VERSION ""

NS_ :

BS_:

BU_: IVI ZCU_F

BO_ 3221225472 VECTOR__INDEPENDENT_SIG_MSG: 0 Vector__XXX
 SG_ IVI_SrcNodeID : 0|8@1+ (1,0) [0|255] "" Vector__XXX
 SG_ IVI_CBV_ReptMsgBit_0 : 0|1@1+ (1,0) [0|1] "" Vector__XXX
 SG_ IVI_CBV_ResdBit_1 : 0|1@1+ (1,0) [0|1] "" Vector__XXX
 SG_ IVI_CBV_ResdBit_2 : 0|1@1+ (1,0) [0|1] "" Vector__XXX
 SG_ IVI_CBV_NMCoordBit_3 : 0|1@1+ (1,0) [0|1] "" Vector__XXX
 SG_ IVI_CBV_ActWakeBit_4 : 0|1@1+ (1,0) [0|1] "" Vector__XXX
 SG_ IVI_CBV_ResdBit_5 : 0|1@1+ (1,0) [0|1] "" Vector__XXX
 SG_ IVI_CBV_PNIBit_6 : 0|1@1+ (1,0) [0|1] "" Vector__XXX
 SG_ IVI_CBV_ResdBit_7 : 0|1@1+ (1,0) [0|1] "" Vector__XXX
 SG_ IVI_UDB_0 : 0|8@1+ (1,0) [0|255] "" Vector__XXX
 SG_ IVI_UDB1_BStoRM_StBit_0 : 0|1@1+ (1,0) [0|1] "" Vector__XXX
 SG_ IVI_UDB1_PBStoRM_StBit_1 : 0|1@1+ (1,0) [0|1] "" Vector__XXX
 SG_ IVI_UDB1_RMtoNO_StBit_2 : 0|1@1+ (1,0) [0|1] "" Vector__XXX
 SG_ IVI_UDB1_RStoNO_StBit_3 : 0|1@1+ (1,0) [0|1] "" Vector__XXX
 SG_ IVI_UDB1_RStoRM_StBit_4 : 0|1@1+ (1,0) [0|1] "" Vector__XXX
 SG_ IVI_UDB1_NOtoRM_StBit_5 : 0|1@1+ (1,0) [0|1] "" Vector__XXX
 SG_ IVI_UDB1_NO_StBit_6 : 0|1@1+ (1,0) [0|1] "" Vector__XXX
 SG_ IVI_UDB1_RM_StBit_7 : 0|1@1+ (1,0) [0|1] "" Vector__XXX
 SG_ IVI_UDB2_IGN_WUPBit_0 : 0|1@1+ (1,0) [0|1] "" Vector__XXX
 SG_ IVI_UDB2_RESET_WUPBit_1 : 0|1@1+ (1,0) [0|1] "" Vector__XXX
 SG_ IVI_UDB2_NM_WUPBit_2 : 0|1@1+ (1,0) [0|1] "" Vector__XXX
 SG_ IVI_UDB2_ECUSPEC_WUPBit_3 : 0|1@1+ (1,0) [0|1] "" Vector__XXX
 SG_ IVI_UDB2_NM_AWAKEBit_4 : 0|1@1+ (1,0) [0|1] "" Vector__XXX
 SG_ IVI_UDB2_IGN_AWAKEBit_5 : 0|1@1+ (1,0) [0|1] "" Vector__XXX
 SG_ IVI_UDB2_DIAG_AWAKEBit_6 : 0|1@1+ (1,0) [0|1] "" Vector__XXX
 SG_ IVI_UDB2_ECUSPEC_AWAKEBit_7 : 0|1@1+ (1,0) [0|1] "" Vector__XXX
 SG_ IVI_UDB3_Bit_0 : 0|1@1+ (1,0) [0|1] "" Vector__XXX
 SG_ IVI_UDB3_Bit_1 : 0|1@1+ (1,0) [0|1] "" Vector__XXX
 SG_ IVI_UDB3_Bit_2 : 0|1@1+ (1,0) [0|1] "" Vector__XXX
 SG_ IVI_UDB3_Bit_3 : 0|1@1+ (1,0) [0|1] "" Vector__XXX
 SG_ IVI_UDB3_Bit_4 : 0|1@1+ (1,0) [0|1] "" Vector__XXX
 SG_ IVI_UDB3_Bit_5 : 0|1@1+ (1,0) [0|1] "" Vector__XXX
 SG_ IVI_UDB3_Bit_6 : 0|1@1+ (1,0) [0|1] "" Vector__XXX
 SG_ IVI_UDB3_Bit_7 : 0|1@1+ (1,0) [0|1] "" Vector__XXX
 SG_ IVI_UDB4_Bit_0 : 0|1@1+ (1,0) [0|1] "" Vector__XXX
 SG_ IVI_UDB4_Bit_1 : 0|1@1+ (1,0) [0|1] "" Vector__XXX
 SG_ IVI_UDB4_Bit_2 : 0|1@1+ (1,0) [0|1] "" Vector__XXX
 SG_ IVI_UDB4_Bit_3 : 0|1@1+ (1,0) [0|1] "" Vector__XXX
 SG_ IVI_UDB4_Bit_4 : 0|1@1+ (1,0) [0|1] "" Vector__XXX
 SG_ IVI_UDB4_Bit_5 : 0|1@1+ (1,0) [0|1] "" Vector__XXX
 SG_ IVI_UDB4_Bit_6 : 0|1@1+ (1,0) [0|1] "" Vector__XXX
 SG_ IVI_UDB4_Bit_7 : 0|1@1+ (1,0) [0|1] "" Vector__XXX
 SG_ IVI_UDB5_Bit_0 : 0|1@1+ (1,0) [0|1] "" Vector__XXX
 SG_ IVI_UDB5_Bit_1 : 0|1@1+ (1,0) [0|1] "" Vector__XXX
 SG_ IVI_UDB5_Bit_2 : 0|1@1+ (1,0) [0|1] "" Vector__XXX
 SG_ IVI_UDB5_Bit_3 : 0|1@1+ (1,0) [0|1] "" Vector__XXX
 SG_ IVI_UDB5_Bit_4 : 0|1@1+ (1,0) [0|1] "" Vector__XXX
 SG_ IVI_UDB5_Bit_5 : 0|1@1+ (1,0) [0|1] "" Vector__XXX
 SG_ IVI_UDB5_Bit_6 : 0|1@1+ (1,0) [0|1] "" Vector__XXX
 SG_ IVI_UDB5_Bit_7 : 0|1@1+ (1,0) [0|1] "" Vector__XXX
 SG_ ZCUF_SrcNodeID : 0|8@1+ (1,0) [0|255] "" Vector__XXX
 SG_ ZCUF_CBV_ReptMsgBit_0 : 0|1@1+ (1,0) [0|1] "" Vector__XXX
 SG_ ZCUF_CBV_ResdBit_1 : 0|1@1+ (1,0) [0|1] "" Vector__XXX
 SG_ ZCUF_CBV_ResdBit_2 : 0|1@1+ (1,0) [0|1] "" Vector__XXX
 SG_ ZCUF_CBV_NMCoordBit_3 : 0|1@1+ (1,0) [0|1] "" Vector__XXX
 SG_ ZCUF_CBV_ActWakeBit_4 : 0|1@1+ (1,0) [0|1] "" Vector__XXX
 SG_ ZCUF_CBV_ResdBit_5 : 0|1@1+ (1,0) [0|1] "" Vector__XXX
 SG_ ZCUF_CBV_PNIBit_6 : 0|1@1+ (1,0) [0|1] "" Vector__XXX
 SG_ ZCUF_CBV_ResdBit_7 : 0|1@1+ (1,0) [0|1] "" Vector__XXX
 SG_ ZCUF_UDB_0 : 0|8@1+ (1,0) [0|255] "" Vector__XXX
 SG_ ZCUF_UDB1_BStoRM_StBit_0 : 0|1@1+ (1,0) [0|1] "" Vector__XXX
 SG_ ZCUF_UDB1_PBStoRM_StBit1 : 0|1@1+ (1,0) [0|1] "" Vector__XXX
 SG_ ZCUF_UDB1_RMtoNO_StBit_2 : 0|1@1+ (1,0) [0|1] "" Vector__XXX
 SG_ ZCUF_UDB1_RStoNO_StBit_3 : 0|1@1+ (1,0) [0|1] "" Vector__XXX
 SG_ ZCUF_UDB1_RStoRM_StBit_4 : 0|1@1+ (1,0) [0|1] "" Vector__XXX
 SG_ ZCUF_UDB1_NOtoRM_StBit_5 : 0|1@1+ (1,0) [0|1] "" Vector__XXX
 SG_ ZCUF_UDB1_NO_StBit_6 : 0|1@1+ (1,0) [0|1] "" Vector__XXX
 SG_ ZCUF_UDB1_RM_StBit_7 : 0|1@1+ (1,0) [0|1] "" Vector__XXX
 SG_ ZCUF_UDB2_IGN_WUPBit_0 : 0|1@1+ (1,0) [0|1] "" Vector__XXX
 SG_ ZCUF_UDB2_RESET_WUPBit_1 : 0|1@1+ (1,0) [0|1] "" Vector__XXX
 SG_ ZCUF_UDB2_NM_WUPBit_2 : 0|1@1+ (1,0) [0|1] "" Vector__XXX
 SG_ ZCUF_UDB2_ECUSPEC_WUPBit_3 : 0|1@1+ (1,0) [0|1] "" Vector__XXX
 SG_ ZCUF_UDB2_NM_AWAKEBit_4 : 0|1@1+ (1,0) [0|1] "" Vector__XXX
 SG_ ZCUF_UDB2_IGN_AWAKEBit_5 : 0|1@1+ (1,0) [0|1] "" Vector__XXX
 SG_ ZCUF_UDB2_DIAG_AWAKEBit_6 : 0|1@1+ (1,0) [0|1] "" Vector__XXX
 SG_ ZCUF_UDB2_ECUSPEC_AWKEBit7 : 0|1@1+ (1,0) [0|1] "" Vector__XXX
 SG_ ZCUF_UDB3_Bit_0 : 0|1@1+ (1,0) [0|1] "" Vector__XXX
 SG_ ZCUF_UDB3_Bit_1 : 0|1@1+ (1,0) [0|1] "" Vector__XXX
 SG_ ZCUF_UDB3_Bit_2 : 0|1@1+ (1,0) [0|1] "" Vector__XXX
 SG_ ZCUF_UDB3_Bit_3 : 0|1@1+ (1,0) [0|1] "" Vector__XXX
 SG_ ZCUF_UDB3_Bit_4 : 0|1@1+ (1,0) [0|1] "" Vector__XXX
 SG_ ZCUF_UDB3_Bit_5 : 0|1@1+ (1,0) [0|1] "" Vector__XXX
 SG_ ZCUF_UDB3_Bit_6 : 0|1@1+ (1,0) [0|1] "" Vector__XXX
 SG_ ZCUF_UDB3_Bit_7 : 0|1@1+ (1,0) [0|1] "" Vector__XXX
 SG_ ZCUF_UDB4_Bit_0 : 0|1@1+ (1,0) [0|1] "" Vector__XXX
 SG_ ZCUF_UDB4_Bit_1 : 0|1@1+ (1,0) [0|1] "" Vector__XXX
 SG_ ZCUF_UDB4_Bit_2 : 0|1@1+ (1,0) [0|1] "" Vector__XXX
 SG_ ZCUF_UDB4_Bit_3 : 0|1@1+ (1,0) [0|1] "" Vector__XXX
 SG_ ZCUF_UDB4_Bit_4 : 0|1@1+ (1,0) [0|1] "" Vector__XXX
 SG_ ZCUF_UDB4_Bit_5 : 0|1@1+ (1,0) [0|1] "" Vector__XXX
 SG_ ZCUF_UDB4_Bit_6 : 0|1@1+ (1,0) [0|1] "" Vector__XXX
 SG_ ZCUF_UDB4_Bit_7 : 0|1@1+ (1,0) [0|1] "" Vector__XXX
 SG_ ZCUF_UDB5_Bit_0 : 0|1@1+ (1,0) [0|1] "" Vector__XXX
 SG_ ZCUF_UDB5_Bit_1 : 0|1@1+ (1,0) [0|1] "" Vector__XXX
 SG_ ZCUF_UDB5_Bit_2 : 0|1@1+ (1,0) [0|1] "" Vector__XXX
 SG_ ZCUF_UDB5_Bit_3 : 0|1@1+ (1,0) [0|1] "" Vector__XXX
 SG_ ZCUF_UDB5_Bit_4 : 0|1@1+ (1,0) [0|1] "" Vector__XXX
 SG_ ZCUF_UDB5_Bit_5 : 0|1@1+ (1,0) [0|1] "" Vector__XXX
 SG_ ZCUF_UDB5_Bit_6 : 0|1@1+ (1,0) [0|1] "" Vector__XXX
 SG_ ZCUF_UDB5_Bit_7 : 0|1@1+ (1,0) [0|1] "" Vector__XXX

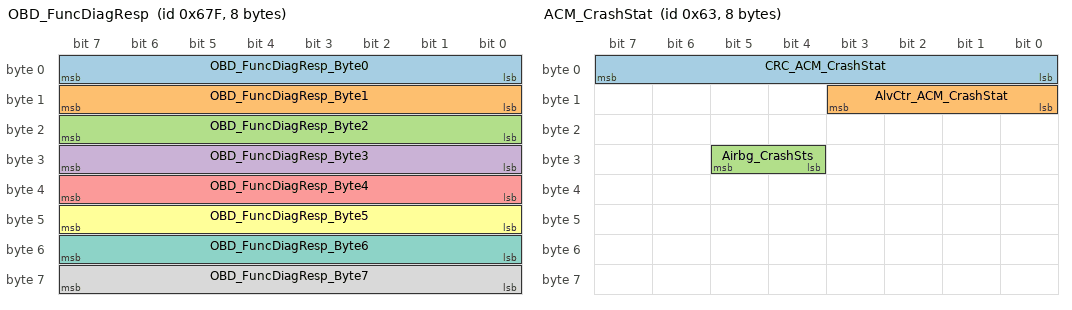
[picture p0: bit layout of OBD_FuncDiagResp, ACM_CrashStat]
BO_ 1663 OBD_FuncDiagResp: 8 IVI
 SG_ OBD_FuncDiagResp_Byte0 : 0|8@1+ (1,0) [0|255] ""  ZCU_F
 SG_ OBD_FuncDiagResp_Byte1 : 8|8@1+ (1,0) [0|255] ""  ZCU_F
 SG_ OBD_FuncDiagResp_Byte2 : 16|8@1+ (1,0) [0|255] ""  ZCU_F
 SG_ OBD_FuncDiagResp_Byte3 : 24|8@1+ (1,0) [0|255] ""  ZCU_F
 SG_ OBD_FuncDiagResp_Byte4 : 32|8@1+ (1,0) [0|255] ""  ZCU_F
 SG_ OBD_FuncDiagResp_Byte5 : 40|8@1+ (1,0) [0|255] ""  ZCU_F
 SG_ OBD_FuncDiagResp_Byte6 : 48|8@1+ (1,0) [0|255] ""  ZCU_F
 SG_ OBD_FuncDiagResp_Byte7 : 56|8@1+ (1,0) [0|255] ""  ZCU_F

BO_ 99 ACM_CrashStat: 8 ZCU_F
 SG_ CRC_ACM_CrashStat : 0|8@1+ (1,0) [0|255] ""  IVI
 SG_ AlvCtr_ACM_CrashStat : 8|4@1+ (1,0) [0|14] ""  IVI
 SG_ Airbg_CrashSts : 28|2@1+ (1,0) [0|3] ""  IVI

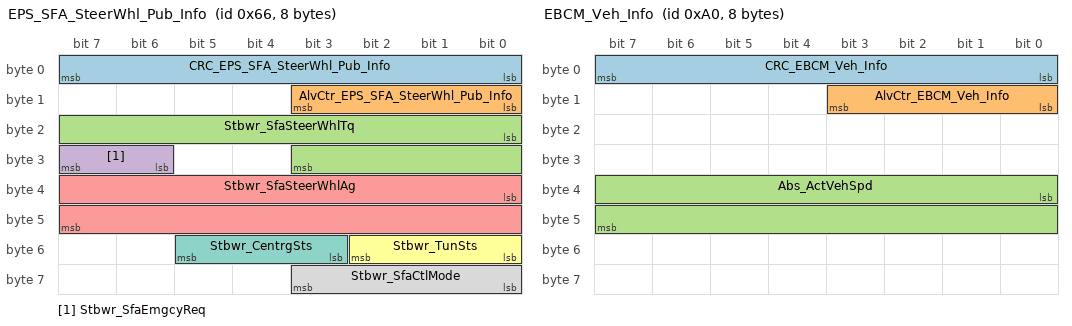
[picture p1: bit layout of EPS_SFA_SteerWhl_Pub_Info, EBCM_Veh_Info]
BO_ 102 EPS_SFA_SteerWhl_Pub_Info: 8 ZCU_F
 SG_ CRC_EPS_SFA_SteerWhl_Pub_Info : 0|8@1+ (1,0) [0|255] ""  IVI
 SG_ AlvCtr_EPS_SFA_SteerWhl_Pub_Info : 8|4@1+ (1,0) [0|14] ""  IVI
 SG_ Stbwr_SfaSteerWhlTq : 16|12@1+ (0.02,-40) [-40|40] "Nm"  IVI
 SG_ Stbwr_SfaEmgcyReq : 30|2@1+ (1,0) [0|3] ""  IVI
 SG_ Stbwr_SfaSteerWhlAg : 32|16@1+ (0.02,-655) [-655|655] "degree"  IVI
 SG_ Stbwr_TunSts : 48|3@1+ (1,0) [0|7] ""  IVI
 SG_ Stbwr_CentrgSts : 51|3@1+ (1,0) [0|7] ""  IVI
 SG_ Stbwr_SfaCtlMode : 56|4@1+ (1,0) [0|15] ""  IVI

BO_ 103 VCU_ETractSys_Info: 32 ZCU_F
 SG_ CRC_VCU_ETractSys_Info : 0|16@1+ (1,0) [0|65535] ""  IVI
 SG_ AlvCtr_VCU_ETractSys_Info : 16|8@1+ (1,0) [0|255] ""  IVI
 SG_ Dtqmt_TgtTqEdsRe : 104|12@1+ (0.5,-1023) [-1023|1024.5] "Nm"  IVI
 SG_ Dtqmt_TgtTqEdsFrnt : 120|12@1+ (0.5,-1023) [-1023|1024.5] "Nm"  IVI

BO_ 118 RWSM_Info: 32 ZCU_F
 SG_ CRC_RWSM_Info : 0|16@1+ (1,0) [0|65535] ""  IVI
 SG_ AlvCtr_RWSM_Info : 16|8@1+ (1,0) [0|255] ""  IVI
 SG_ ReWhlSteer_MeasdStkVal : 40|16@1+ (0.01,-327.67) [0|327.65] "mm"  IVI
 SG_ ReWhlSteer_Sts : 56|2@1+ (1,0) [0|3] ""  IVI

BO_ 119 BMS_Sts: 64 ZCU_F
 SG_ CRC_BMS_Sts : 0|16@1+ (1,0) [0|65535] ""  IVI
 SG_ AlvCtr_BMS_Sts : 16|8@1+ (1,0) [0|255] ""  IVI
 SG_ Bms_BatPreCdnSts : 70|2@1+ (1,0) [0|3] ""  IVI

BO_ 128 EPS_RWA_Pinion_Pub_Info: 32 ZCU_F
 SG_ CRC_EPS_RWA_Pinion_Pub_Info : 0|16@1+ (1,0) [0|65535] ""  IVI
 SG_ AlvCtr_EPS_RWA_Pinion_Pub_Info : 16|8@1+ (1,0) [0|255] ""  IVI
 SG_ Stbwr_RwaPinionAg : 24|16@1+ (0.02,-655) [-655|655] "degree"  IVI
 SG_ Stbwr_RwaPinionAgSpd : 40|16@1+ (0.05,-1638) [-1638|1638] "deg/s"  IVI
 SG_ Stbwr_RwaRackPosn : 56|20@1+ (0.001,-524) [-524|524] "mm"  IVI
 SG_ Stbwr_RwaRackSpd : 76|20@1+ (0.001,-524) [-524|524.575] "mm/s"  IVI

BO_ 160 EBCM_Veh_Info: 8 ZCU_F
 SG_ CRC_EBCM_Veh_Info : 0|8@1+ (1,0) [0|255] ""  IVI
 SG_ AlvCtr_EBCM_Veh_Info : 8|4@1+ (1,0) [0|14] ""  IVI
 SG_ Abs_ActVehSpd : 32|16@1+ (0.015625,0) [0|350] "kmph"  IVI

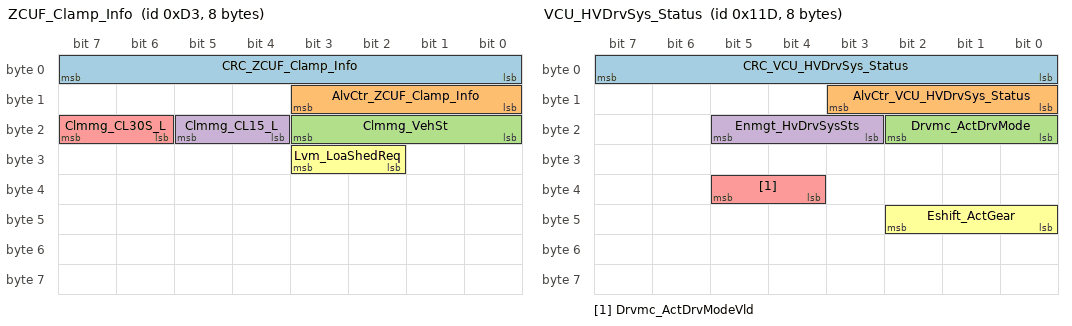
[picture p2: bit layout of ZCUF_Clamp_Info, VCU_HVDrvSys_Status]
BO_ 211 ZCUF_Clamp_Info: 8 ZCU_F
 SG_ CRC_ZCUF_Clamp_Info : 0|8@1+ (1,0) [0|255] ""  IVI
 SG_ AlvCtr_ZCUF_Clamp_Info : 8|4@1+ (1,0) [0|14] ""  IVI
 SG_ Clmmg_VehSt : 16|4@1+ (1,0) [0|15] ""  IVI
 SG_ Clmmg_CL15_L : 20|2@1+ (1,0) [0|3] ""  IVI
 SG_ Clmmg_CL30S_L : 22|2@1+ (1,0) [0|3] ""  IVI
 SG_ Lvm_LoaShedReq : 26|2@1+ (1,0) [0|3] ""  IVI

BO_ 223 ASU_SnsrInfo: 32 ZCU_F
 SG_ CRC_ASU_SnsrInfo : 0|16@1+ (1,0) [0|65535] ""  IVI
 SG_ AlvCtr_ASU_SnsrInfo : 16|8@1+ (1,0) [0|255] ""  IVI
 SG_ AirSuspUnit_HeiFL : 24|12@1+ (1,0) [0|4095] "mm"  IVI
 SG_ AirSuspUnit_HeiFR : 36|12@1+ (1,0) [0|4095] "mm"  IVI
 SG_ AirSuspUnit_HeiRR : 48|12@1+ (1,0) [0|4095] "mm"  IVI
 SG_ AirSuspUnit_HeiRL : 60|12@1+ (1,0) [0|4095] "mm"  IVI
 SG_ AirSuspUnit_HeiSts : 72|3@1+ (1,0) [0|7] ""  IVI
 SG_ AirSuspUnit_CdcModeSts : 75|3@1+ (1,0) [0|7] ""  IVI
 SG_ AirSuspUnit_IngrsModAck : 78|2@1+ (1,0) [0|3] ""  IVI
 SG_ AirSuspUnit_SprgModeSts : 80|3@1+ (1,0) [0|7] ""  IVI
 SG_ AirSuspUnit_CmprSts : 83|3@1+ (1,0) [0|7] ""  IVI
 SG_ AirSuspUnit_SrvModeSts : 86|2@1+ (1,0) [0|3] ""  IVI
 SG_ AirSuspUnit_AirTankP : 88|8@1+ (10,0) [0|2530] "bar"  IVI
 SG_ AirSuspUnit_Sts : 96|3@1+ (1,0) [0|7] ""  IVI

BO_ 273 VCU_Batt_Info: 32 ZCU_F
 SG_ CRC_VCU_Batt_Info : 0|16@1+ (1,0) [0|65535] ""  IVI
 SG_ AlvCtr_VCU_Batt_Info : 16|8@1+ (1,0) [0|255] ""  IVI
 SG_ Bms_PackI : 24|16@1+ (0.1,-1500) [-1500|1500] "A"  IVI
 SG_ Bms_PackU : 40|16@1+ (0.1,0) [0|600] "V"  IVI
 SG_ Acchg_RmngChgTi : 56|12@1+ (1,0) [0|1500] "minute"  IVI
 SG_ Fschg_RmngChgTi : 68|12@1+ (1,0) [0|1500] "minute"  IVI

BO_ 279 VCU_Charging_Info: 32 ZCU_F
 SG_ CRC_VCU_Charging_Info : 0|16@1+ (1,0) [0|65535] ""  IVI
 SG_ AlvCtr_VCU_Charging_Info : 16|8@1+ (1,0) [0|255] ""  IVI
 SG_ Fschg_DcChgGunIn : 24|2@1+ (1,0) [0|3] ""  IVI
 SG_ Acchg_AcChgGunIn : 26|2@1+ (1,0) [0|3] ""  IVI

BO_ 285 VCU_HVDrvSys_Status: 8 ZCU_F
 SG_ CRC_VCU_HVDrvSys_Status : 0|8@1+ (1,0) [0|255] ""  IVI
 SG_ AlvCtr_VCU_HVDrvSys_Status : 8|4@1+ (1,0) [0|14] ""  IVI
 SG_ Drvmc_ActDrvMode : 16|3@1+ (1,0) [0|7] ""  IVI
 SG_ Enmgt_HvDrvSysSts : 19|3@1+ (1,0) [0|7] ""  IVI
 SG_ Drvmc_ActDrvModeVld : 36|2@1+ (1,0) [0|3] ""  IVI
 SG_ Eshift_ActGear : 40|3@1+ (1,0) [0|7] ""  IVI

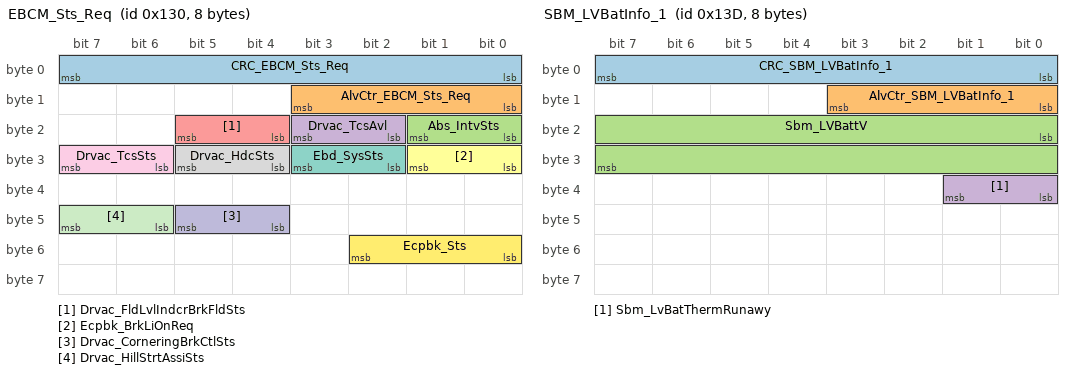
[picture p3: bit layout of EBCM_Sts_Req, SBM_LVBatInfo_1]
BO_ 304 EBCM_Sts_Req: 8 ZCU_F
 SG_ CRC_EBCM_Sts_Req : 0|8@1+ (1,0) [0|255] ""  IVI
 SG_ AlvCtr_EBCM_Sts_Req : 8|4@1+ (1,0) [0|14] ""  IVI
 SG_ Abs_IntvSts : 16|2@1+ (1,0) [0|3] ""  IVI
 SG_ Drvac_TcsAvl : 18|2@1+ (1,0) [0|3] ""  IVI
 SG_ Drvac_FldLvlIndcrBrkFldSts : 20|2@1+ (1,0) [0|3] ""  IVI
 SG_ Ecpbk_BrkLiOnReq : 24|2@1+ (1,0) [0|3] ""  IVI
 SG_ Ebd_SysSts : 26|2@1+ (1,0) [0|3] ""  IVI
 SG_ Drvac_HdcSts : 28|2@1+ (1,0) [0|3] ""  IVI
 SG_ Drvac_TcsSts : 30|2@1+ (1,0) [0|3] ""  IVI
 SG_ Drvac_CorneringBrkCtlSts : 44|2@1+ (1,0) [0|3] ""  IVI
 SG_ Drvac_HillStrtAssiSts : 46|2@1+ (1,0) [0|3] ""  IVI
 SG_ Ecpbk_Sts : 48|3@1+ (1,0) [0|7] ""  IVI

BO_ 313 ZCUR_LampCmd: 32 ZCU_F
 SG_ CRC_ZCUR_LampCmd : 0|16@1+ (1,0) [0|65535] ""  IVI
 SG_ AlvCtr_ZCUR_LampCmd : 16|8@1+ (1,0) [0|255] ""  IVI

BO_ 317 SBM_LVBatInfo_1: 8 ZCU_F
 SG_ CRC_SBM_LVBatInfo_1 : 0|8@1+ (1,0) [0|255] ""  IVI
 SG_ AlvCtr_SBM_LVBatInfo_1 : 8|4@1+ (1,0) [0|14] ""  IVI
 SG_ Sbm_LVBattV : 16|16@1+ (0.001,0) [0|65.535] "V"  IVI
 SG_ Sbm_LvBatThermRunawy : 32|2@1+ (1,0) [0|3] ""  IVI

BO_ 318 SBM_LVBatInfo_2: 32 ZCU_F
 SG_ CRC_SBM_LVBatInfo_2 : 0|16@1+ (1,0) [0|65535] ""  IVI
 SG_ AlvCtr_SBM_LVBatInfo_2 : 16|8@1+ (1,0) [0|255] ""  IVI
 SG_ Sbm_LVBatActSoh : 32|7@1+ (1,0) [0|100] "%"  IVI
 SG_ Sbm_CriticalSoCAlert : 40|4@1+ (1,0) [0|15] ""  IVI
 SG_ Sbm_LvBattT : 96|8@1+ (1,-40) [-40|215] "°C"  IVI

BO_ 327 VCU_Consumption_Info: 12 ZCU_F
 SG_ Engmt_LvAuxAvgEngCns : 0|16@1+ (0.1,0) [0|1440] "Kwh/100Km"  IVI
 SG_ Engmt_InttsEngCnsRate : 16|10@1+ (1,0) [0|1023] "W"  IVI
 SG_ Engmt_TotAvgEngCns : 32|16@1+ (0.1,0) [0|1440] "Kwh/100Km"  IVI
 SG_ Engmt_EdsAvgEngCns : 48|16@1+ (0.1,0) [0|1440] "Kwh/100Km"  IVI
 SG_ Engmt_ThermAvgEngCns : 64|16@1+ (0.1,0) [0|1440] "Kwh/100Km"  IVI

BO_ 349 VCU_To_Veh_Info: 32 ZCU_F
 SG_ CRC_VCU_To_Veh_Info : 0|16@1+ (1,0) [0|65535] ""  IVI
 SG_ AlvCtr_VCU_To_Veh_Info : 16|8@1+ (1,0) [0|255] ""  IVI
 SG_ Acchg_HVBatSoc : 24|10@1+ (0.1,0) [0|100] "%"  IVI
 SG_ Acchg_AcChgSts : 34|3@1+ (1,0) [0|7] ""  IVI
 SG_ Awd_ActWhlDrvMode : 37|3@1+ (1,0) [0|7] ""  IVI
 SG_ Engmt_ChrgrDlvPwr : 40|16@1+ (0.1,0) [0|1440] "kW"  IVI
 SG_ Engmt_VehRmngDrvRng : 56|10@1+ (1,0) [0|1023] "km"  IVI
 SG_ Cregb_CoastRgnLvlIndcr : 69|3@1+ (1,0) [0|7] ""  IVI
 SG_ Fschg_VehChrgnSts : 72|3@1+ (1,0) [0|7] ""  IVI
 SG_ Eshift_ChngGearFromPark : 78|2@1+ (1,0) [0|3] ""  IVI
 SG_ Engmt_VehMilg : 80|10@1+ (1,0) [0|1023] "km/kWh"  IVI
 SG_ Fschg_HVBatSoc : 90|10@1+ (0.1,0) [0|100] "%"  IVI
 SG_ Fschg_ChgGunLockSts : 100|2@1+ (1,0) [0|3] ""  IVI
 SG_ Awd_ActWhlDrvModeVld : 120|2@1+ (1,0) [0|3] ""  IVI

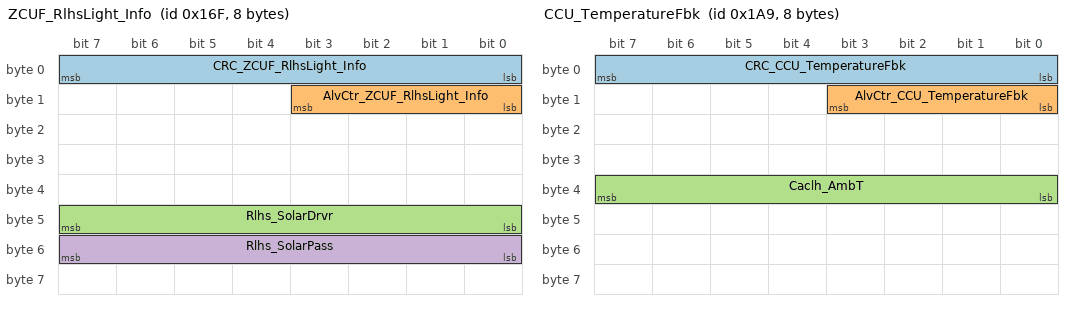
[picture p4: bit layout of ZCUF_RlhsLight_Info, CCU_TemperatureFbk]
BO_ 367 ZCUF_RlhsLight_Info: 8 ZCU_F
 SG_ CRC_ZCUF_RlhsLight_Info : 0|8@1+ (1,0) [0|255] ""  IVI
 SG_ AlvCtr_ZCUF_RlhsLight_Info : 8|4@1+ (1,0) [0|14] ""  IVI
 SG_ Rlhs_SolarDrvr : 40|8@1+ (4,0) [0|1000] "W/m2"  IVI
 SG_ Rlhs_SolarPass : 48|8@1+ (4,0) [0|1000] "W/m2"  IVI

BO_ 371 HDLML_FrontLamp_Sts: 32 ZCU_F
 SG_ CRC_HDLML_FrontLamp_Sts : 0|16@1+ (1,0) [0|65535] ""  IVI
 SG_ AlvCtr_HDLML_FrontLamp_Sts : 16|8@1+ (1,0) [0|255] ""  IVI
 SG_ Hdlamp_LeLoBeamLampSts : 24|2@1+ (1,0) [0|3] ""  IVI
 SG_ Hdlamp_LeHiBeamLampSts : 26|3@1+ (1,0) [0|7] ""  IVI

BO_ 377 HDLMR_FrontLamp_Sts: 32 ZCU_F
 SG_ CRC_HDLMR_FrontLamp_Sts : 0|16@1+ (1,0) [0|65535] ""  IVI
 SG_ AlvCtr_HDLMR_FrontLamp_Sts : 16|8@1+ (1,0) [0|255] ""  IVI
 SG_ Hdlamp_RiLoBeamLampSts : 24|2@1+ (1,0) [0|3] ""  IVI
 SG_ Hdlamp_RiHiBeamLampSts : 26|3@1+ (1,0) [0|7] ""  IVI

BO_ 383 SLMFL_FrontLamp_Sts: 32 ZCU_F
 SG_ CRC_SLMFL_FrontLamp_Sts : 0|16@1+ (1,0) [0|65535] ""  IVI
 SG_ AlvCtr_SLMFL_FrontLamp_Sts : 16|8@1+ (1,0) [0|255] ""  IVI
 SG_ Hdlamp_LeFrntPosnLampSts : 24|2@1+ (1,0) [0|3] ""  IVI
 SG_ Hdlamp_LeDRLLampSts : 26|2@1+ (1,0) [0|3] ""  IVI
 SG_ Hdlamp_FrntLeBodyTurnIndcrSts : 28|3@1+ (1,0) [0|7] ""  IVI

BO_ 387 SLMFR_FrontLamp_Sts: 32 ZCU_F
 SG_ CRC_SLMFR_FrontLamp_Sts : 0|16@1+ (1,0) [0|65535] ""  IVI
 SG_ AlvCtr_SLMFR_FrontLamp_Sts : 16|8@1+ (1,0) [0|255] ""  IVI
 SG_ Hdlamp_RiFrntPosnLampSts : 24|2@1+ (1,0) [0|3] ""  IVI
 SG_ Hdlamp_RiDRLLampSts : 26|2@1+ (1,0) [0|3] ""  IVI
 SG_ Hdlamp_FrntRiBodyTurnIndcrSts : 28|3@1+ (1,0) [0|7] ""  IVI

BO_ 393 RLML_RearLampSts: 32 ZCU_F
 SG_ CRC_RLML_RearLampSts : 0|16@1+ (1,0) [0|65535] ""  IVI
 SG_ AlvCtr_RLML_RearLampSts : 16|8@1+ (1,0) [0|255] ""  IVI
 SG_ Relamp_LeBodyBrkLampSts : 24|2@1+ (1,0) [0|3] ""  IVI
 SG_ Relamp_ReLeBodyPosnLampSts : 26|2@1+ (1,0) [0|3] ""  IVI
 SG_ Relamp_ReLeBodyTurnIndcrSts : 28|3@1+ (1,0) [0|7] ""  IVI

BO_ 399 RLMR_RearLampSts: 32 ZCU_F
 SG_ CRC_RLMR_RearLampSts : 0|16@1+ (1,0) [0|65535] ""  IVI
 SG_ AlvCtr_RLMR_RearLampSts : 16|8@1+ (1,0) [0|255] ""  IVI
 SG_ Relamp_RiBodyBrkLampSts : 24|2@1+ (1,0) [0|3] ""  IVI
 SG_ Relamp_ReRiBodyPosnLampSts : 26|2@1+ (1,0) [0|3] ""  IVI
 SG_ Relamp_ReRiBodyTurnIndcrSts : 28|3@1+ (1,0) [0|7] ""  IVI

BO_ 403 TLML_RearLampSts: 32 ZCU_F
 SG_ CRC_TLML_RearLampSts : 0|16@1+ (1,0) [0|65535] ""  IVI
 SG_ AlvCtr_TLML_RearLampSts : 16|8@1+ (1,0) [0|255] ""  IVI
 SG_ Relamp_LeTLGBrkLampSts : 24|2@1+ (1,0) [0|3] ""  IVI
 SG_ Relamp_ReLeTLGPosnLampSts : 26|2@1+ (1,0) [0|3] ""  IVI
 SG_ Relamp_ReLeTLGTurnIndcrSts : 28|3@1+ (1,0) [0|7] ""  IVI

BO_ 409 SLMFC_LampSts: 32 ZCU_F
 SG_ CRC_SLMFC_LampSts : 0|16@1+ (1,0) [0|65535] ""  IVI
 SG_ AlvCtr_SLMFC_LampSts : 16|8@1+ (1,0) [0|255] ""  IVI
 SG_ Hdlamp_FrntCentr_LeSignLampSts : 24|2@1+ (1,0) [0|3] ""  IVI
 SG_ Hdlamp_FrntCentr_RiSignLampSts : 26|2@1+ (1,0) [0|3] ""  IVI

BO_ 410 SLMRC_LampSts: 32 ZCU_F
 SG_ CRC_SLMRC_LampSts : 0|16@1+ (1,0) [0|65535] ""  IVI
 SG_ AlvCtr_SLMRC_LampSts : 16|8@1+ (1,0) [0|255] ""  IVI
 SG_ Relamp_FrntCentr_LeSignLampSts : 24|2@1+ (1,0) [0|3] ""  IVI
 SG_ Relamp_FrntCentr_RiSignLampSts : 26|2@1+ (1,0) [0|3] ""  IVI

BO_ 415 TLMR_RearLampSts: 32 ZCU_F
 SG_ CRC_TLMR_RearLampSts : 0|16@1+ (1,0) [0|65535] ""  IVI
 SG_ AlvCtr_TLMR_RearLampSts : 16|8@1+ (1,0) [0|255] ""  IVI
 SG_ Relamp_RiTLGBrkLampSts : 24|2@1+ (1,0) [0|3] ""  IVI
 SG_ Relamp_ReRiTLGPosnLampSts : 26|2@1+ (1,0) [0|3] ""  IVI
 SG_ Relamp_ReRiTLGTurnIndcrSts : 28|3@1+ (1,0) [0|7] ""  IVI

BO_ 419 CCU_CompPwr_Req: 8 ZCU_F
 SG_ Ccsf_AgsOpenReq : 32|2@1+ (1,0) [0|3] ""  IVI

BO_ 425 CCU_TemperatureFbk: 8 ZCU_F
 SG_ CRC_CCU_TemperatureFbk : 0|8@1+ (1,0) [0|255] ""  IVI
 SG_ AlvCtr_CCU_TemperatureFbk : 8|4@1+ (1,0) [0|14] ""  IVI
 SG_ Caclh_AmbT : 32|8@1+ (0.5,-40) [-40|85] "°C"  IVI

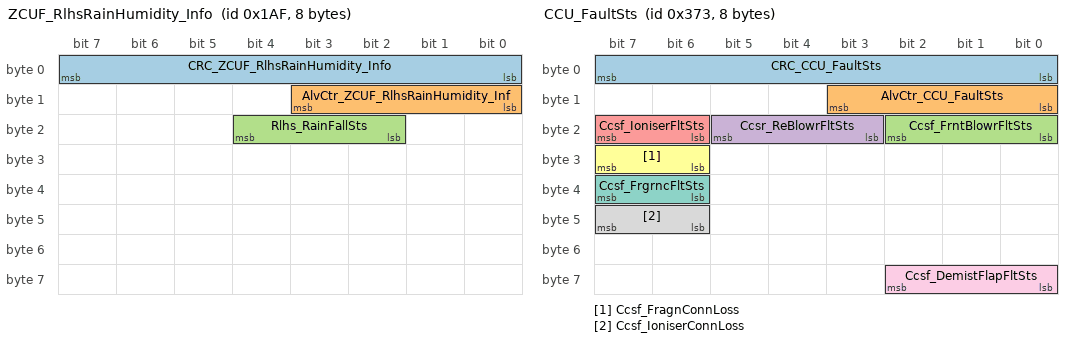
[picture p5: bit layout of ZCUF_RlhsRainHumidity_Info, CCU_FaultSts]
BO_ 431 ZCUF_RlhsRainHumidity_Info: 8 ZCU_F
 SG_ CRC_ZCUF_RlhsRainHumidity_Info : 0|8@1+ (1,0) [0|255] ""  IVI
 SG_ AlvCtr_ZCUF_RlhsRainHumidity_Inf : 8|4@1+ (1,0) [0|14] ""  IVI
 SG_ Rlhs_RainFallSts : 18|3@1+ (1,0) [0|7] ""  IVI

BO_ 740 ADAS_Rvc_Info: 32 ZCU_F
 SG_ CRC_ADAS_Rvc_Info : 0|16@1+ (1,0) [0|65535] ""  IVI
 SG_ AlvCtr_ADAS_Rvc_Info : 16|8@1+ (1,0) [0|255] ""  IVI
 SG_ Rvc_ReBlindSpot_Sts : 24|2@1+ (1,0) [0|3] ""  IVI

BO_ 869 IVI_Ept_Feature_Info: 32 IVI
 SG_ IVI_Acchr_chrggunUnlck_cmd : 0|2@1+ (1,0) [0|3] ""  ZCU_F
 SG_ Acchg_IviChgStopReq : 2|2@1+ (1,0) [0|3] ""  ZCU_F
 SG_ Acchg_ChrgnSdleTi : 4|12@1+ (1,0) [0|2359] "minute"  ZCU_F
 SG_ Acchg_IviMaxChgILim : 16|16@1+ (0.1,0) [0|1500] "A"  ZCU_F
 SG_ Acchg_PeakHourMngtEna : 32|2@1+ (1,0) [0|3] ""  ZCU_F
 SG_ Acchg_IviEnaSdleChrgn : 34|2@1+ (1,0) [0|3] ""  ZCU_F
 SG_ Acchg_IviTgtChgSocLvl : 38|10@1+ (0.1,0) [0|100] "%"  ZCU_F
 SG_ Awd_WhlDrvModeSeln : 48|2@1+ (1,0) [0|3] ""  ZCU_F
 SG_ Eshift_TowMode_Req : 50|2@1+ (1,0) [0|3] ""  ZCU_F
 SG_ Drvmc_ValetModeAcvnSts : 52|2@1+ (1,0) [0|3] ""  ZCU_F
 SG_ Drvmc_WashModeAcvnSts : 54|2@1+ (1,0) [0|3] ""  ZCU_F
 SG_ Dtqmt_SrvModeSpdLim : 56|16@1+ (0.015625,0) [0|350] "kmph"  ZCU_F
 SG_ Drvmc_ShowroomModeAcvnSts : 72|2@1+ (1,0) [0|3] ""  ZCU_F
 SG_ Dtqmt_SrvSpdOvrrEna : 76|2@1+ (1,0) [0|3] ""  ZCU_F
 SG_ Drvmc_TrsptModeAcvnSts : 78|2@1+ (1,0) [0|3] ""  ZCU_F
 SG_ Dtqmt_ValetModeSpdLim : 80|16@1+ (0.015625,0) [0|350] "kmph"  ZCU_F
 SG_ Drvmc_DrvModeSelnReq : 96|3@1+ (1,0) [0|7] ""  ZCU_F
 SG_ Cregb_RegenLvl_Req : 99|3@1+ (1,0) [0|7] ""  ZCU_F

BO_ 873 ZCUR_IVI_Sts: 32 ZCU_F
 SG_ CRC_ZCUR_IVI_Sts : 0|16@1+ (1,0) [0|65535] ""  IVI
 SG_ AlvCtr_ZCUR_IVI_Sts : 16|8@1+ (1,0) [0|255] ""  IVI
 SG_ Acttg_TailGateSts : 24|4@1+ (1,0) [0|15] ""  IVI
 SG_ Acttg_TailGateNmlznSts : 28|2@1+ (1,0) [0|3] ""  IVI
 SG_ Acttg_TailGateAjarSts : 30|2@1+ (1,0) [0|3] ""  IVI
 SG_ Acttg_ActPosnAgSts : 32|7@1+ (1,0) [0|100] "%"  IVI
 SG_ SeatCfmt_ReLeVentnSts : 40|3@1+ (1,0) [0|7] ""  IVI
 SG_ SeatCfmt_ReRiVentnSts : 43|3@1+ (1,0) [0|7] ""  IVI
 SG_ SeatCfmt_ReLeVentnCshnFanFailSts : 48|2@1+ (1,0) [0|3] ""  IVI
 SG_ SeatCfmt_ReLeVentnSqubFanFailSts : 50|2@1+ (1,0) [0|3] ""  IVI
 SG_ SeatCfmt_ReRiVentnCshnFanFailSts : 52|2@1+ (1,0) [0|3] ""  IVI
 SG_ SeatCfmt_ReRiVentnSqubFanFailSts : 54|2@1+ (1,0) [0|3] ""  IVI
 SG_ ChrgrPort_LockUnlck_Sts : 60|2@1+ (1,0) [0|3] ""  IVI
 SG_ ChrgrPort_Ajar_Sts : 62|2@1+ (1,0) [0|3] ""  IVI
 SG_ Relamp_RiLicePlateSts : 64|2@1+ (1,0) [0|3] ""  IVI
 SG_ Relamp_LeLicePlateSts : 66|2@1+ (1,0) [0|3] ""  IVI
 SG_ Relamp_FogLampSts : 68|2@1+ (1,0) [0|3] ""  IVI
 SG_ Relamp_ChmslSts : 70|2@1+ (1,0) [0|3] ""  IVI
 SG_ Relamp_RevLmpSts : 72|2@1+ (1,0) [0|3] ""  IVI

BO_ 883 CCU_FaultSts: 8 ZCU_F
 SG_ CRC_CCU_FaultSts : 0|8@1+ (1,0) [0|255] ""  IVI
 SG_ AlvCtr_CCU_FaultSts : 8|4@1+ (1,0) [0|14] ""  IVI
 SG_ Ccsf_FrntBlowrFltSts : 16|3@1+ (1,0) [0|7] ""  IVI
 SG_ Ccsr_ReBlowrFltSts : 19|3@1+ (1,0) [0|7] ""  IVI
 SG_ Ccsf_IoniserFltSts : 22|2@1+ (1,0) [0|3] ""  IVI
 SG_ Ccsf_FragnConnLoss : 30|2@1+ (1,0) [0|3] ""  IVI
 SG_ Ccsf_FrgrncFltSts : 38|2@1+ (1,0) [0|3] ""  IVI
 SG_ Ccsf_IoniserConnLoss : 46|2@1+ (1,0) [0|3] ""  IVI
 SG_ Ccsf_DemistFlapFltSts : 56|3@1+ (1,0) [0|7] ""  IVI

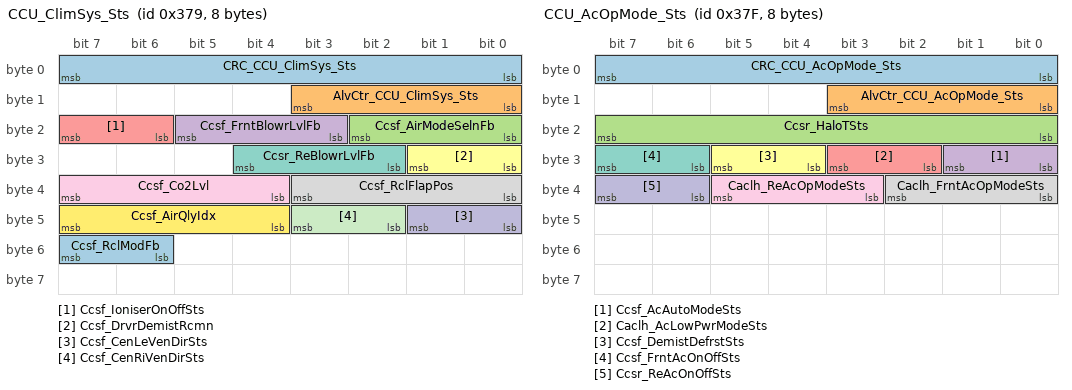
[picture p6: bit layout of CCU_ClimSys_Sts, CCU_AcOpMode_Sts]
BO_ 889 CCU_ClimSys_Sts: 8 ZCU_F
 SG_ CRC_CCU_ClimSys_Sts : 0|8@1+ (1,0) [0|255] ""  IVI
 SG_ AlvCtr_CCU_ClimSys_Sts : 8|4@1+ (1,0) [0|14] ""  IVI
 SG_ Ccsf_AirModeSelnFb : 16|3@1+ (1,0) [0|7] ""  IVI
 SG_ Ccsf_FrntBlowrLvlFb : 19|3@1+ (1,0) [0|7] ""  IVI
 SG_ Ccsf_IoniserOnOffSts : 22|2@1+ (1,0) [0|3] ""  IVI
 SG_ Ccsf_DrvrDemistRcmn : 24|2@1+ (1,0) [0|3] ""  IVI
 SG_ Ccsr_ReBlowrLvlFb : 26|3@1+ (1,0) [0|7] ""  IVI
 SG_ Ccsf_RclFlapPos : 32|4@1+ (10,0) [0|100] "%"  IVI
 SG_ Ccsf_Co2Lvl : 36|4@1+ (10,0) [0|100] "ppm"  IVI
 SG_ Ccsf_CenLeVenDirSts : 40|2@1+ (1,0) [0|3] ""  IVI
 SG_ Ccsf_CenRiVenDirSts : 42|2@1+ (1,0) [0|3] ""  IVI
 SG_ Ccsf_AirQlyIdx : 44|4@1+ (1,0) [0|15] ""  IVI
 SG_ Ccsf_RclModFb : 54|2@1+ (1,0) [0|3] ""  IVI

BO_ 895 CCU_AcOpMode_Sts: 8 ZCU_F
 SG_ CRC_CCU_AcOpMode_Sts : 0|8@1+ (1,0) [0|255] ""  IVI
 SG_ AlvCtr_CCU_AcOpMode_Sts : 8|4@1+ (1,0) [0|14] ""  IVI
 SG_ Ccsr_HaloTSts : 16|8@1+ (0.5,-40) [-40|85] "°C"  IVI
 SG_ Ccsf_AcAutoModeSts : 24|2@1+ (1,0) [0|3] ""  IVI
 SG_ Caclh_AcLowPwrModeSts : 26|2@1+ (1,0) [0|3] ""  IVI
 SG_ Ccsf_DemistDefrstSts : 28|2@1+ (1,0) [0|3] ""  IVI
 SG_ Ccsf_FrntAcOnOffSts : 30|2@1+ (1,0) [0|3] ""  IVI
 SG_ Caclh_FrntAcOpModeSts : 32|3@1+ (1,0) [0|7] ""  IVI
 SG_ Caclh_ReAcOpModeSts : 35|3@1+ (1,0) [0|7] ""  IVI
 SG_ Ccsr_ReAcOnOffSts : 38|2@1+ (1,0) [0|3] ""  IVI

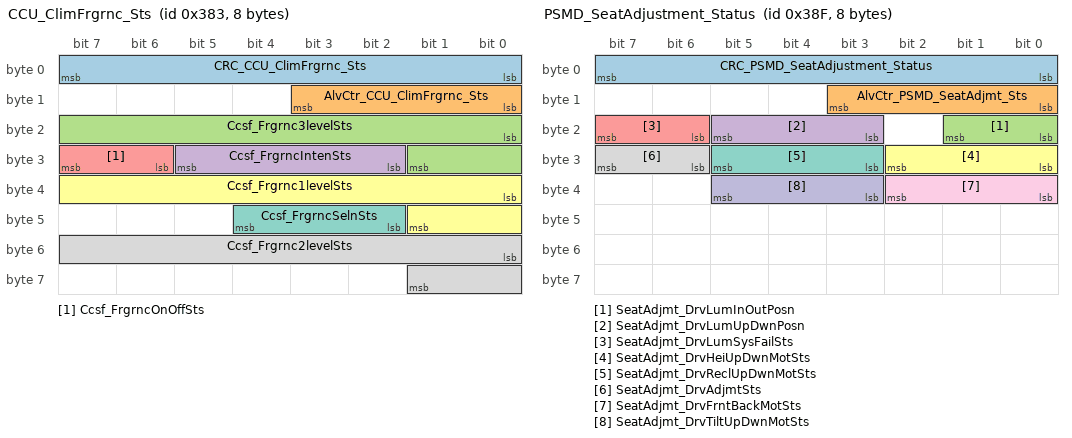
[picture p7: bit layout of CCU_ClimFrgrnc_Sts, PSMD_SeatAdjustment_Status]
BO_ 899 CCU_ClimFrgrnc_Sts: 8 ZCU_F
 SG_ CRC_CCU_ClimFrgrnc_Sts : 0|8@1+ (1,0) [0|255] ""  IVI
 SG_ AlvCtr_CCU_ClimFrgrnc_Sts : 8|4@1+ (1,0) [0|14] ""  IVI
 SG_ Ccsf_Frgrnc3levelSts : 16|10@1+ (0.1,0) [0|100] ""  IVI
 SG_ Ccsf_FrgrncIntenSts : 26|4@1+ (10,0) [0|100] ""  IVI
 SG_ Ccsf_FrgrncOnOffSts : 30|2@1+ (1,0) [0|3] ""  IVI
 SG_ Ccsf_Frgrnc1levelSts : 32|10@1+ (0.1,0) [0|100] ""  IVI
 SG_ Ccsf_FrgrncSelnSts : 42|3@1+ (1,0) [0|7] ""  IVI
 SG_ Ccsf_Frgrnc2levelSts : 48|10@1+ (0.1,0) [0|100] ""  IVI

BO_ 911 PSMD_SeatAdjustment_Status: 8 ZCU_F
 SG_ CRC_PSMD_SeatAdjustment_Status : 0|8@1+ (1,0) [0|255] ""  IVI
 SG_ AlvCtr_PSMD_SeatAdjmt_Sts : 8|4@1+ (1,0) [0|14] ""  IVI
 SG_ SeatAdjmt_DrvLumInOutPosn : 16|2@1+ (1,0) [0|3] ""  IVI
 SG_ SeatAdjmt_DrvLumUpDwnPosn : 19|3@1+ (1,0) [0|7] ""  IVI
 SG_ SeatAdjmt_DrvLumSysFailSts : 22|2@1+ (1,0) [0|3] ""  IVI
 SG_ SeatAdjmt_DrvHeiUpDwnMotSts : 24|3@1+ (1,0) [0|7] ""  IVI
 SG_ SeatAdjmt_DrvReclUpDwnMotSts : 27|3@1+ (1,0) [0|7] ""  IVI
 SG_ SeatAdjmt_DrvAdjmtSts : 30|2@1+ (1,0) [0|3] ""  IVI
 SG_ SeatAdjmt_DrvFrntBackMotSts : 32|3@1+ (1,0) [0|7] ""  IVI
 SG_ SeatAdjmt_DrvTiltUpDwnMotSts : 35|3@1+ (1,0) [0|7] ""  IVI

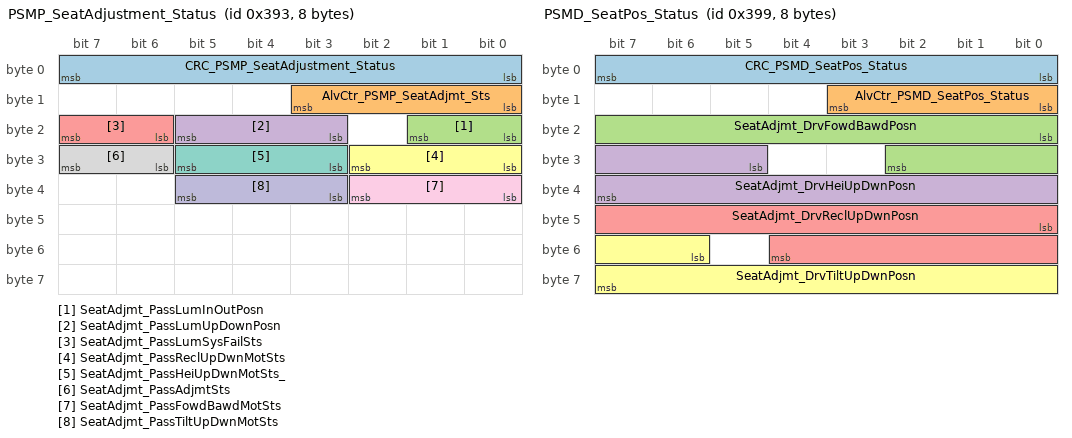
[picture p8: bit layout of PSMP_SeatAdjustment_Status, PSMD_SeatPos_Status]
BO_ 915 PSMP_SeatAdjustment_Status: 8 ZCU_F
 SG_ CRC_PSMP_SeatAdjustment_Status : 0|8@1+ (1,0) [0|255] ""  IVI
 SG_ AlvCtr_PSMP_SeatAdjmt_Sts : 8|4@1+ (1,0) [0|14] ""  IVI
 SG_ SeatAdjmt_PassLumInOutPosn : 16|2@1+ (1,0) [0|3] ""  IVI
 SG_ SeatAdjmt_PassLumUpDownPosn : 19|3@1+ (1,0) [0|7] ""  IVI
 SG_ SeatAdjmt_PassLumSysFailSts : 22|2@1+ (1,0) [0|3] ""  IVI
 SG_ SeatAdjmt_PassReclUpDwnMotSts : 24|3@1+ (1,0) [0|7] ""  IVI
 SG_ SeatAdjmt_PassHeiUpDwnMotSts_ : 27|3@1+ (1,0) [0|7] ""  IVI
 SG_ SeatAdjmt_PassAdjmtSts : 30|2@1+ (1,0) [0|3] ""  IVI
 SG_ SeatAdjmt_PassFowdBawdMotSts : 32|3@1+ (1,0) [0|7] ""  IVI
 SG_ SeatAdjmt_PassTiltUpDwnMotSts : 35|3@1+ (1,0) [0|7] ""  IVI

BO_ 921 PSMD_SeatPos_Status: 8 ZCU_F
 SG_ CRC_PSMD_SeatPos_Status : 0|8@1+ (1,0) [0|255] ""  IVI
 SG_ AlvCtr_PSMD_SeatPos_Status : 8|4@1+ (1,0) [0|14] ""  IVI
 SG_ SeatAdjmt_DrvFowdBawdPosn : 16|11@1+ (1,0) [0|1400] "Count"  IVI
 SG_ SeatAdjmt_DrvHeiUpDwnPosn : 29|11@1+ (1,0) [0|1600] "Count"  IVI
 SG_ SeatAdjmt_DrvReclUpDwnPosn : 40|13@1+ (1,0) [0|5000] "Count"  IVI
 SG_ SeatAdjmt_DrvTiltUpDwnPosn : 54|10@1+ (1,0) [0|1000] "Count"  IVI

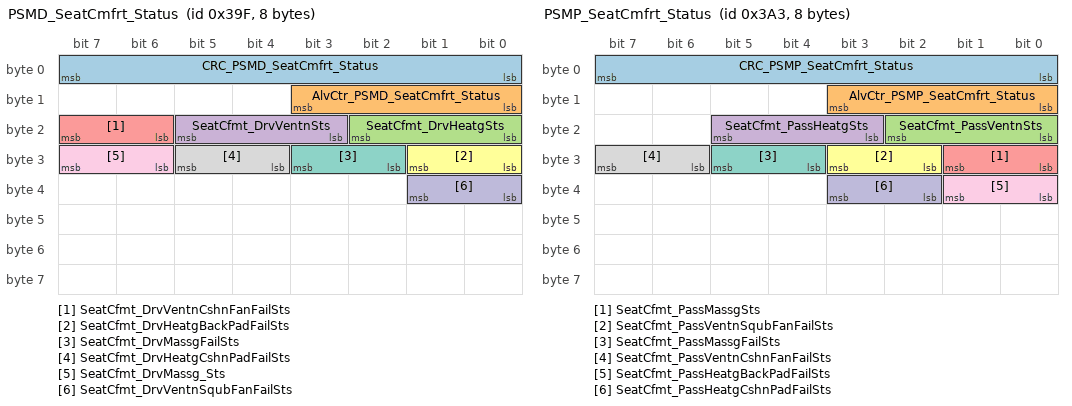
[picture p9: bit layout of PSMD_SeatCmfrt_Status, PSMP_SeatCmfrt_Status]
BO_ 927 PSMD_SeatCmfrt_Status: 8 ZCU_F
 SG_ CRC_PSMD_SeatCmfrt_Status : 0|8@1+ (1,0) [0|255] ""  IVI
 SG_ AlvCtr_PSMD_SeatCmfrt_Status : 8|4@1+ (1,0) [0|14] ""  IVI
 SG_ SeatCfmt_DrvHeatgSts : 16|3@1+ (1,0) [0|7] ""  IVI
 SG_ SeatCfmt_DrvVentnSts : 19|3@1+ (1,0) [0|7] ""  IVI
 SG_ SeatCfmt_DrvVentnCshnFanFailSts : 22|2@1+ (1,0) [0|3] ""  IVI
 SG_ SeatCfmt_DrvHeatgBackPadFailSts : 24|2@1+ (1,0) [0|3] ""  IVI
 SG_ SeatCfmt_DrvMassgFailSts : 26|2@1+ (1,0) [0|3] ""  IVI
 SG_ SeatCfmt_DrvHeatgCshnPadFailSts : 28|2@1+ (1,0) [0|3] ""  IVI
 SG_ SeatCfmt_DrvMassg_Sts : 30|2@1+ (1,0) [0|3] ""  IVI
 SG_ SeatCfmt_DrvVentnSqubFanFailSts : 32|2@1+ (1,0) [0|3] ""  IVI

BO_ 931 PSMP_SeatCmfrt_Status: 8 ZCU_F
 SG_ CRC_PSMP_SeatCmfrt_Status : 0|8@1+ (1,0) [0|255] ""  IVI
 SG_ AlvCtr_PSMP_SeatCmfrt_Status : 8|4@1+ (1,0) [0|14] ""  IVI
 SG_ SeatCfmt_PassVentnSts : 16|3@1+ (1,0) [0|7] ""  IVI
 SG_ SeatCfmt_PassHeatgSts : 19|3@1+ (1,0) [0|7] ""  IVI
 SG_ SeatCfmt_PassMassgSts : 24|2@1+ (1,0) [0|3] ""  IVI
 SG_ SeatCfmt_PassVentnSqubFanFailSts : 26|2@1+ (1,0) [0|3] ""  IVI
 SG_ SeatCfmt_PassMassgFailSts : 28|2@1+ (1,0) [0|3] ""  IVI
 SG_ SeatCfmt_PassVentnCshnFanFailSts : 30|2@1+ (1,0) [0|3] ""  IVI
 SG_ SeatCfmt_PassHeatgBackPadFailSts : 32|2@1+ (1,0) [0|3] ""  IVI
 SG_ SeatCfmt_PassHeatgCshnPadFailSts : 34|2@1+ (1,0) [0|3] ""  IVI

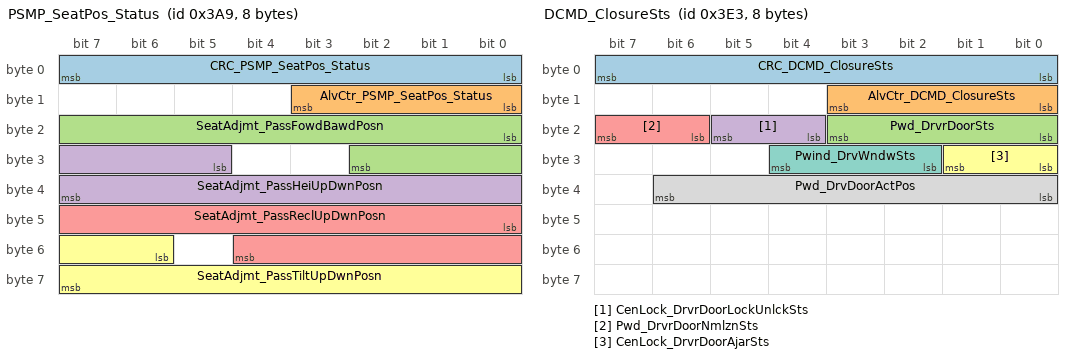
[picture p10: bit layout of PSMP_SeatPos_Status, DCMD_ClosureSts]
BO_ 937 PSMP_SeatPos_Status: 8 ZCU_F
 SG_ CRC_PSMP_SeatPos_Status : 0|8@1+ (1,0) [0|255] ""  IVI
 SG_ AlvCtr_PSMP_SeatPos_Status : 8|4@1+ (1,0) [0|14] ""  IVI
 SG_ SeatAdjmt_PassFowdBawdPosn : 16|11@1+ (1,0) [0|1400] "Count"  IVI
 SG_ SeatAdjmt_PassHeiUpDwnPosn : 29|11@1+ (1,0) [0|1600] "Count"  IVI
 SG_ SeatAdjmt_PassReclUpDwnPosn : 40|13@1+ (1,0) [0|5000] "Count"  IVI
 SG_ SeatAdjmt_PassTiltUpDwnPosn : 54|10@1+ (1,0) [0|1000] "Count"  IVI

BO_ 995 DCMD_ClosureSts: 8 ZCU_F
 SG_ CRC_DCMD_ClosureSts : 0|8@1+ (1,0) [0|255] ""  IVI
 SG_ AlvCtr_DCMD_ClosureSts : 8|4@1+ (1,0) [0|14] ""  IVI
 SG_ Pwd_DrvrDoorSts : 16|4@1+ (1,0) [0|15] ""  IVI
 SG_ CenLock_DrvrDoorLockUnlckSts : 20|2@1+ (1,0) [0|3] ""  IVI
 SG_ Pwd_DrvrDoorNmlznSts : 22|2@1+ (1,0) [0|3] ""  IVI
 SG_ CenLock_DrvrDoorAjarSts : 24|2@1+ (1,0) [0|3] ""  IVI
 SG_ Pwind_DrvWndwSts : 26|3@1+ (1,0) [0|7] ""  IVI
 SG_ Pwd_DrvDoorActPos : 32|7@1+ (1,0) [0|100] "%"  IVI

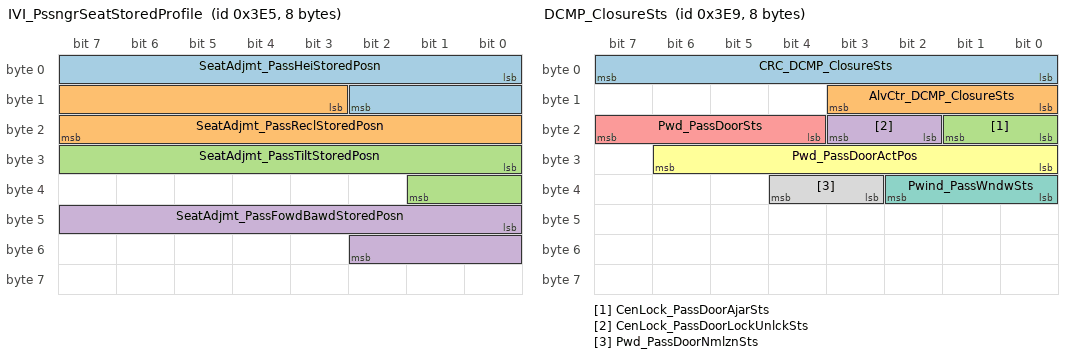
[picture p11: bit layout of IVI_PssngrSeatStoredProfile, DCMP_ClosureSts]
BO_ 997 IVI_PssngrSeatStoredProfile: 8 IVI
 SG_ SeatAdjmt_PassHeiStoredPosn : 0|11@1+ (1,0) [0|1600] "Count"  ZCU_F
 SG_ SeatAdjmt_PassReclStoredPosn : 11|13@1+ (1,0) [0|5000] "Count"  ZCU_F
 SG_ SeatAdjmt_PassTiltStoredPosn : 24|10@1+ (1,0) [0|1000] "Count"  ZCU_F
 SG_ SeatAdjmt_PassFowdBawdStoredPosn : 40|11@1+ (1,0) [0|1400] "Count"  ZCU_F

BO_ 999 VCU_Sts: 32 ZCU_F
 SG_ CRC_VCU_Sts : 0|16@1+ (1,0) [0|65535] ""  IVI
 SG_ AlvCtr_VCU_Sts : 16|8@1+ (1,0) [0|255] ""  IVI
 SG_ Engmt_LimphmSts : 24|2@1+ (1,0) [0|3] ""  IVI
 SG_ Fschg_ChgAuthenSts : 32|3@1+ (1,0) [0|7] ""  IVI
 SG_ Acchg_ChgAuthnSts : 35|3@1+ (1,0) [0|7] ""  IVI
 SG_ Thmgt_ThermFltSts : 38|2@1+ (1,0) [0|3] ""  IVI
 SG_ Cregb_CoastRgnTqPctg : 40|8@1+ (1,0) [0|100] "%"  IVI
 SG_ Hfdia_RemdActn : 48|8@1+ (1,0) [0|255] ""  IVI
 SG_ Hvsco_HvSysSts : 56|3@1+ (1,0) [0|7] ""  IVI

BO_ 1001 DCMP_ClosureSts: 8 ZCU_F
 SG_ CRC_DCMP_ClosureSts : 0|8@1+ (1,0) [0|255] ""  IVI
 SG_ AlvCtr_DCMP_ClosureSts : 8|4@1+ (1,0) [0|14] ""  IVI
 SG_ CenLock_PassDoorAjarSts : 16|2@1+ (1,0) [0|3] ""  IVI
 SG_ CenLock_PassDoorLockUnlckSts : 18|2@1+ (1,0) [0|3] ""  IVI
 SG_ Pwd_PassDoorSts : 20|4@1+ (1,0) [0|15] ""  IVI
 SG_ Pwd_PassDoorActPos : 24|7@1+ (1,0) [0|100] "%"  IVI
 SG_ Pwind_PassWndwSts : 32|3@1+ (1,0) [0|7] ""  IVI
 SG_ Pwd_PassDoorNmlznSts : 35|2@1+ (1,0) [0|3] ""  IVI

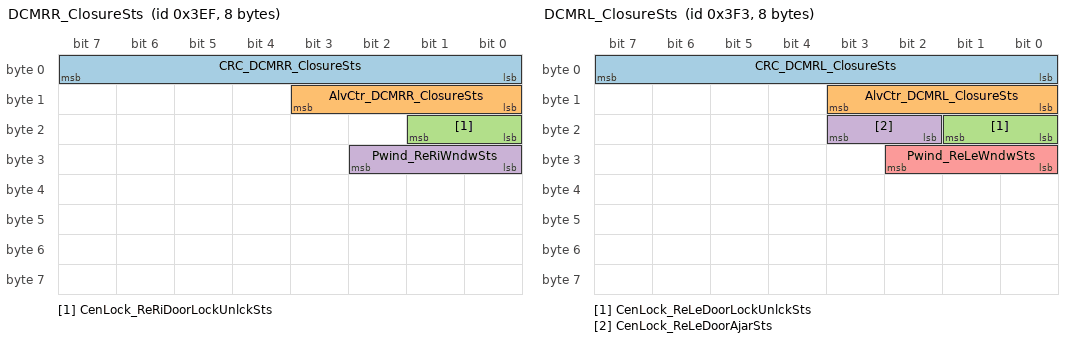
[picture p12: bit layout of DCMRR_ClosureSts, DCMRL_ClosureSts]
BO_ 1007 DCMRR_ClosureSts: 8 ZCU_F
 SG_ CRC_DCMRR_ClosureSts : 0|8@1+ (1,0) [0|255] ""  IVI
 SG_ AlvCtr_DCMRR_ClosureSts : 8|4@1+ (1,0) [0|14] ""  IVI
 SG_ CenLock_ReRiDoorLockUnlckSts : 16|2@1+ (1,0) [0|3] ""  IVI
 SG_ Pwind_ReRiWndwSts : 24|3@1+ (1,0) [0|7] ""  IVI

BO_ 1011 DCMRL_ClosureSts: 8 ZCU_F
 SG_ CRC_DCMRL_ClosureSts : 0|8@1+ (1,0) [0|255] ""  IVI
 SG_ AlvCtr_DCMRL_ClosureSts : 8|4@1+ (1,0) [0|14] ""  IVI
 SG_ CenLock_ReLeDoorLockUnlckSts : 16|2@1+ (1,0) [0|3] ""  IVI
 SG_ CenLock_ReLeDoorAjarSts : 18|2@1+ (1,0) [0|3] ""  IVI
 SG_ Pwind_ReLeWndwSts : 24|3@1+ (1,0) [0|7] ""  IVI

BO_ 1017 ZCUF_WiperSts: 32 ZCU_F
 SG_ CRC_ZCUF_WiperSts : 0|16@1+ (1,0) [0|65535] ""  IVI
 SG_ AlvCtr_ZCUF_WiperSts : 16|8@1+ (1,0) [0|255] ""  IVI
 SG_ Wipr_FrntLeParkPosSts : 24|2@1+ (1,0) [0|3] ""  IVI
 SG_ Wipr_FrntLeSerPosSts : 26|2@1+ (1,0) [0|3] ""  IVI
 SG_ Wipr_FrntLeSts : 28|2@1+ (1,0) [0|3] ""  IVI
 SG_ Wipr_FrntRiParkPosSts : 32|2@1+ (1,0) [0|3] ""  IVI
 SG_ Wipr_FrntRiSerPosSts : 34|2@1+ (1,0) [0|3] ""  IVI
 SG_ Wipr_FrntRiSts : 36|2@1+ (1,0) [0|3] ""  IVI
 SG_ Wipr_WshrSts : 38|2@1+ (1,0) [0|3] ""  IVI
 SG_ Wipr_WshrFluidLevelSts : 40|3@1+ (1,0) [0|7] ""  IVI
 SG_ Wipr_FrntRiFaildSts : 48|4@1+ (1,0) [0|15] ""  IVI
 SG_ Wipr_FrntLeFaildSts : 52|4@1+ (1,0) [0|15] ""  IVI

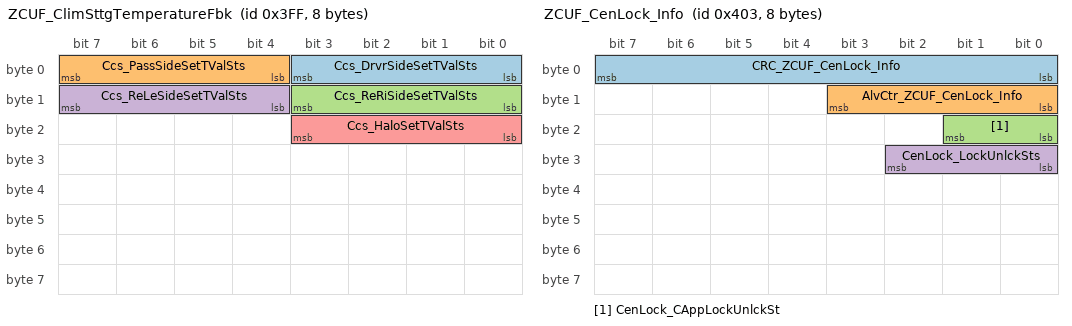
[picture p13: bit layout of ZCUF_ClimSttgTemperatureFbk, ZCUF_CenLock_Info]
BO_ 1023 ZCUF_ClimSttgTemperatureFbk: 8 ZCU_F
 SG_ Ccs_DrvrSideSetTValSts : 0|4@1+ (1,16) [16|28] "°C"  IVI
 SG_ Ccs_PassSideSetTValSts : 4|4@1+ (1,16) [16|28] "°C"  IVI
 SG_ Ccs_ReRiSideSetTValSts : 8|4@1+ (1,16) [16|28] "°C"  IVI
 SG_ Ccs_ReLeSideSetTValSts : 12|4@1+ (1,16) [16|28] "°C"  IVI
 SG_ Ccs_HaloSetTValSts : 16|4@1+ (1,16) [16|28] "°C"  IVI

BO_ 1027 ZCUF_CenLock_Info: 8 ZCU_F
 SG_ CRC_ZCUF_CenLock_Info : 0|8@1+ (1,0) [0|255] ""  IVI
 SG_ AlvCtr_ZCUF_CenLock_Info : 8|4@1+ (1,0) [0|14] ""  IVI
 SG_ CenLock_CAppLockUnlckSt : 16|2@1+ (1,0) [0|3] ""  IVI
 SG_ CenLock_LockUnlckSts : 24|3@1+ (1,0) [0|7] ""  IVI

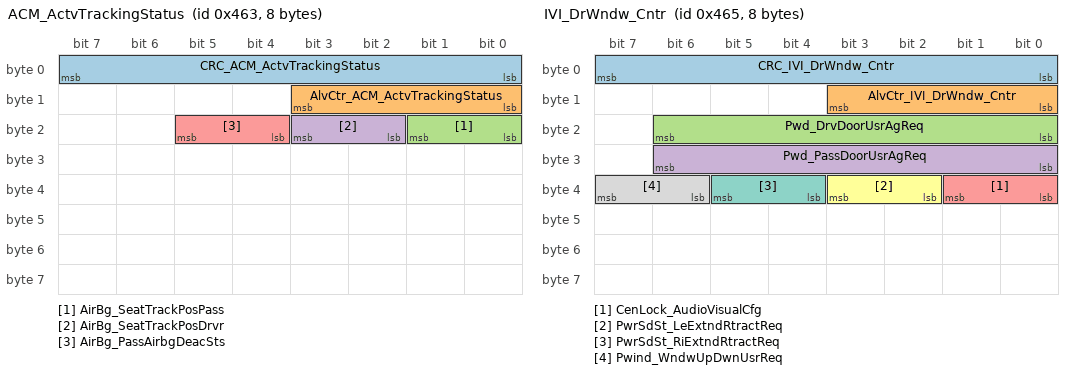
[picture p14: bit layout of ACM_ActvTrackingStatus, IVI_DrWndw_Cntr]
BO_ 1123 ACM_ActvTrackingStatus: 8 ZCU_F
 SG_ CRC_ACM_ActvTrackingStatus : 0|8@1+ (1,0) [0|255] ""  IVI
 SG_ AlvCtr_ACM_ActvTrackingStatus : 8|4@1+ (1,0) [0|14] ""  IVI
 SG_ AirBg_SeatTrackPosPass : 16|2@1+ (1,0) [0|3] ""  IVI
 SG_ AirBg_SeatTrackPosDrvr : 18|2@1+ (1,0) [0|3] ""  IVI
 SG_ AirBg_PassAirbgDeacSts : 20|2@1+ (1,0) [0|3] ""  IVI

BO_ 1125 IVI_DrWndw_Cntr: 8 IVI
 SG_ CRC_IVI_DrWndw_Cntr : 0|8@1+ (1,0) [0|255] ""  ZCU_F
 SG_ AlvCtr_IVI_DrWndw_Cntr : 8|4@1+ (1,0) [0|14] ""  ZCU_F
 SG_ Pwd_DrvDoorUsrAgReq : 16|7@1+ (1,0) [0|100] "%"  ZCU_F
 SG_ Pwd_PassDoorUsrAgReq : 24|7@1+ (1,0) [0|100] "%"  ZCU_F
 SG_ CenLock_AudioVisualCfg : 32|2@1+ (1,0) [0|3] ""  ZCU_F
 SG_ PwrSdSt_LeExtndRtractReq : 34|2@1+ (1,0) [0|3] ""  ZCU_F
 SG_ PwrSdSt_RiExtndRtractReq : 36|2@1+ (1,0) [0|3] ""  ZCU_F
 SG_ Pwind_WndwUpDwnUsrReq : 38|2@1+ (1,0) [0|3] ""  ZCU_F

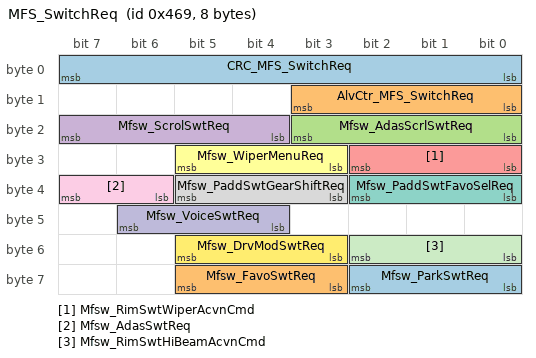
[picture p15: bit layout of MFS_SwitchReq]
BO_ 1129 MFS_SwitchReq: 8 ZCU_F
 SG_ CRC_MFS_SwitchReq : 0|8@1+ (1,0) [0|255] ""  IVI
 SG_ AlvCtr_MFS_SwitchReq : 8|4@1+ (1,0) [0|14] ""  IVI
 SG_ Mfsw_AdasScrlSwtReq : 16|4@1+ (1,0) [0|15] ""  IVI
 SG_ Mfsw_ScrolSwtReq : 20|4@1+ (1,0) [0|15] ""  IVI
 SG_ Mfsw_RimSwtWiperAcvnCmd : 24|3@1+ (1,0) [0|7] ""  IVI
 SG_ Mfsw_WiperMenuReq : 27|3@1+ (1,0) [0|7] ""  IVI
 SG_ Mfsw_PaddSwtFavoSelReq : 32|3@1+ (1,0) [0|7] ""  IVI
 SG_ Mfsw_PaddSwtGearShiftReq : 35|3@1+ (1,0) [0|7] ""  IVI
 SG_ Mfsw_AdasSwtReq : 38|2@1+ (1,0) [0|3] ""  IVI
 SG_ Mfsw_VoiceSwtReq : 44|3@1+ (1,0) [0|7] ""  IVI
 SG_ Mfsw_RimSwtHiBeamAcvnCmd : 48|3@1+ (1,0) [0|7] ""  IVI
 SG_ Mfsw_DrvModSwtReq : 51|3@1+ (1,0) [0|7] ""  IVI
 SG_ Mfsw_ParkSwtReq : 56|3@1+ (1,0) [0|7] ""  IVI
 SG_ Mfsw_FavoSwtReq : 59|3@1+ (1,0) [0|7] ""  IVI

CM_ "Infotainment 1 CAN FD";
CM_ BU_ IVI "In Vehicle Infotainment";
CM_ BU_ ZCU_F "Zone Control Unit-Front";
CM_ BO_ 3221225472 "This is a message for not used signals, created by Vector CANdb++ DBC OLE DB Provider.";
CM_ SG_ 3221225472 IVI_SrcNodeID "IVI Network management signal for Source Node identifer";
CM_ SG_ 3221225472 IVI_CBV_ReptMsgBit_0 "IVI Network management signal for Control bit vector Repeat Message Request";
CM_ SG_ 3221225472 IVI_CBV_ResdBit_1 "IVI Network management signal for Control bit vector Reserved";
CM_ SG_ 3221225472 IVI_CBV_ResdBit_2 "IVI Network management signal for Control bit vector Reserved";
CM_ SG_ 3221225472 IVI_CBV_NMCoordBit_3 "IVI Network management signal for Control bit vector NM Coordinator Sleep Bit";
CM_ SG_ 3221225472 IVI_CBV_ActWakeBit_4 "IVI Network management signal for Control bit vector Active Wakeup Bit";
CM_ SG_ 3221225472 IVI_CBV_ResdBit_5 "IVI Network management signal for Control bit vector Reserved";
CM_ SG_ 3221225472 IVI_CBV_PNIBit_6 "IVI Network management signal for Partial Network Information Bit";
CM_ SG_ 3221225472 IVI_CBV_ResdBit_7 "IVI Network management signal for Control bit vector Reserved";
CM_ SG_ 3221225472 IVI_UDB_0 "IVI Network management user data Byte 0";
CM_ SG_ 3221225472 IVI_UDB1_BStoRM_StBit_0 "IVI Network management user data 1 from Bus sleep mode to Repeat Message State";
CM_ SG_ 3221225472 IVI_UDB1_PBStoRM_StBit_1 "IVI Network management user data 1 from Prepare Bus sleep mode to Repeat Message State";
CM_ SG_ 3221225472 IVI_UDB1_RMtoNO_StBit_2 "IVI Network management user data 1 from Repeat Message State to Normal Operation State";
CM_ SG_ 3221225472 IVI_UDB1_RStoNO_StBit_3 "IVI Network management user data 1 from Ready Sleep State to Normal Operation State";
CM_ SG_ 3221225472 IVI_UDB1_RStoRM_StBit_4 "IVI Network management user data 1 from Ready Sleep State to Repeat Message State";
CM_ SG_ 3221225472 IVI_UDB1_NOtoRM_StBit_5 "IVI Network management user data 1 from Normal Operation State to Repeat Message State";
CM_ SG_ 3221225472 IVI_UDB1_NO_StBit_6 "IVI Network management user data 1 at Normal Operation State";
CM_ SG_ 3221225472 IVI_UDB1_RM_StBit_7 "IVI Network management user data 1 at Repeat Message State";
CM_ SG_ 3221225472 IVI_UDB2_IGN_WUPBit_0 "ECU was power off or Bus sleep mode and stated by Ignition turn on";
CM_ SG_ 3221225472 IVI_UDB2_RESET_WUPBit_1 "If ECU was already awake, in Prepare Bus Sleep or Ready Sleep Mode and re -started by an internal or an external reset.";
CM_ SG_ 3221225472 IVI_UDB2_NM_WUPBit_2 "ECU was in Power off , Bus Sleep, Prepare Bus Sleep or Ready Sleep Mode and then re-started by a network communication.";
CM_ SG_ 3221225472 IVI_UDB2_ECUSPEC_WUPBit_3 "ECU was in Power off, Bus Sleep, Prepare Bus Sleep or Ready Sleep mode or awake and then re -started by ECU -specific reason(e.g. pressed Button, timer, etc.)";
CM_ SG_ 3221225472 IVI_UDB2_NM_AWAKEBit_4 "ECU need network communication and keeps the network awake.";
CM_ SG_ 3221225472 IVI_UDB2_IGN_AWAKEBit_5 "ECU can not release communication because Ignition is turn on.";
CM_ SG_ 3221225472 IVI_UDB2_DIAG_AWAKEBit_6 "ECU need communication for diagnostic purpose and keeps network awake.";
CM_ SG_ 3221225472 IVI_UDB2_ECUSPEC_AWAKEBit_7 "ECU keeps the network awake for ECU-define reasons for which communication is needed.";
CM_ SG_ 3221225472 IVI_UDB3_Bit_0 "IVI Network management user data 3 Bit 0";
CM_ SG_ 3221225472 IVI_UDB3_Bit_1 "IVI Network management user data 3 Bit 1";
CM_ SG_ 3221225472 IVI_UDB3_Bit_2 "IVI Network management user data 3 Bit 2";
CM_ SG_ 3221225472 IVI_UDB3_Bit_3 "IVI Network management user data 3 Bit 3";
CM_ SG_ 3221225472 IVI_UDB3_Bit_4 "IVI Network management user data 3 Bit 4";
CM_ SG_ 3221225472 IVI_UDB3_Bit_5 "IVI Network management user data 3 Bit 5";
CM_ SG_ 3221225472 IVI_UDB3_Bit_6 "IVI Network management user data 3 Bit 6";
CM_ SG_ 3221225472 IVI_UDB3_Bit_7 "IVI Network management user data 3 Bit 7";
CM_ SG_ 3221225472 IVI_UDB4_Bit_0 "IVI Network management user data 4 Bit 0";
CM_ SG_ 3221225472 IVI_UDB4_Bit_1 "IVI Network management user data 4 Bit 1";
CM_ SG_ 3221225472 IVI_UDB4_Bit_2 "IVI Network management user data 4 Bit 2";
CM_ SG_ 3221225472 IVI_UDB4_Bit_3 "IVI Network management user data 4 Bit 3";
CM_ SG_ 3221225472 IVI_UDB4_Bit_4 "IVI Network management user data 4 Bit 4";
CM_ SG_ 3221225472 IVI_UDB4_Bit_5 "IVI Network management user data 4 Bit 5";
CM_ SG_ 3221225472 IVI_UDB4_Bit_6 "IVI Network management user data 4 Bit 6";
CM_ SG_ 3221225472 IVI_UDB4_Bit_7 "IVI Network management user data 4 Bit 7";
CM_ SG_ 3221225472 IVI_UDB5_Bit_0 "IVI Network management user data 5 Bit 0";
CM_ SG_ 3221225472 IVI_UDB5_Bit_1 "IVI Network management user data 5 Bit 1";
CM_ SG_ 3221225472 IVI_UDB5_Bit_2 "IVI Network management user data 5 Bit 2";
CM_ SG_ 3221225472 IVI_UDB5_Bit_3 "IVI Network management user data 5 Bit 3";
CM_ SG_ 3221225472 IVI_UDB5_Bit_4 "IVI Network management user data 5 Bit 4";
CM_ SG_ 3221225472 IVI_UDB5_Bit_5 "IVI Network management user data 5 Bit 5";
CM_ SG_ 3221225472 IVI_UDB5_Bit_6 "IVI Network management user data 5 Bit 6";
CM_ SG_ 3221225472 IVI_UDB5_Bit_7 "IVI Network management user data 5 Bit 7";
CM_ SG_ 3221225472 ZCUF_SrcNodeID "ZCU_F Network management signal for Source Node identifer";
CM_ SG_ 3221225472 ZCUF_CBV_ReptMsgBit_0 "ZCU_F Network management signal for Control bit vector Repeat Message Request";
CM_ SG_ 3221225472 ZCUF_CBV_ResdBit_1 "ZCU_F Network management signal for Control bit vector Reserved";
CM_ SG_ 3221225472 ZCUF_CBV_ResdBit_2 "ZCU_F Network management signal for Control bit vector Reserved";
CM_ SG_ 3221225472 ZCUF_CBV_NMCoordBit_3 "ZCU_F Network management signal for Control bit vector NM Coordinator Sleep Bit";
CM_ SG_ 3221225472 ZCUF_CBV_ActWakeBit_4 "ZCU_F Network management signal for Control bit vector Active Wakeup Bit";
CM_ SG_ 3221225472 ZCUF_CBV_ResdBit_5 "ZCU_F Network management signal for Control bit vector Reserved";
CM_ SG_ 3221225472 ZCUF_CBV_PNIBit_6 "ZCU_F Network management signal for Partial Network Information Bit";
CM_ SG_ 3221225472 ZCUF_CBV_ResdBit_7 "ZCU_F Network management signal for Control bit vector Reserved";
CM_ SG_ 3221225472 ZCUF_UDB_0 "ZCU_F Network management user data Byte 0";
CM_ SG_ 3221225472 ZCUF_UDB1_BStoRM_StBit_0 "ZCU_F Network management user data 1 from Bus sleep mode to Repeat Message State";
CM_ SG_ 3221225472 ZCUF_UDB1_PBStoRM_StBit1 "ZCU_F Network management user data 1 from Prepare Bus sleep mode to Repeat Message State";
CM_ SG_ 3221225472 ZCUF_UDB1_RMtoNO_StBit_2 "ZCU_F Network management user data 1 from Repeat Message State to Normal Operation State";
CM_ SG_ 3221225472 ZCUF_UDB1_RStoNO_StBit_3 "ZCU_F Network management user data 1 from Ready Sleep State to Normal Operation State";
CM_ SG_ 3221225472 ZCUF_UDB1_RStoRM_StBit_4 "ZCU_F Network management user data 1 from Ready Sleep State to Repeat Message State";
CM_ SG_ 3221225472 ZCUF_UDB1_NOtoRM_StBit_5 "ZCU_F Network management user data 1 from Normal Operation State to Repeat Message State";
CM_ SG_ 3221225472 ZCUF_UDB1_NO_StBit_6 "ZCU_F Network management user data 1 at Normal Operation State";
CM_ SG_ 3221225472 ZCUF_UDB1_RM_StBit_7 "ZCU_F Network management user data 1 at Repeat Message State";
CM_ SG_ 3221225472 ZCUF_UDB2_IGN_WUPBit_0 "ECU was power off or Bus sleep mode and stated by Ignition turn on";
CM_ SG_ 3221225472 ZCUF_UDB2_RESET_WUPBit_1 "If ECU was already awake, in Prepare Bus Sleep or Ready Sleep Mode and re -started by an internal or an external reset.";
CM_ SG_ 3221225472 ZCUF_UDB2_NM_WUPBit_2 "ECU was in Power off , Bus Sleep, Prepare Bus Sleep or Ready Sleep Mode and then re-started by a network communication.";
CM_ SG_ 3221225472 ZCUF_UDB2_ECUSPEC_WUPBit_3 "ECU was in Power off, Bus Sleep, Prepare Bus Sleep or Ready Sleep mode or awake and then re -started by ECU -specific reason(e.g. pressed Button, timer, etc.)";
CM_ SG_ 3221225472 ZCUF_UDB2_NM_AWAKEBit_4 "ECU need network communication and keeps the network awake.";
CM_ SG_ 3221225472 ZCUF_UDB2_IGN_AWAKEBit_5 "ECU can not release communication because Ignition is turn on.";
CM_ SG_ 3221225472 ZCUF_UDB2_DIAG_AWAKEBit_6 "ECU need communication for diagnostic purpose and keeps network awake.";
CM_ SG_ 3221225472 ZCUF_UDB2_ECUSPEC_AWKEBit7 "ECU keeps the network awake for ECU-define reasons for which communication is needed.";
CM_ SG_ 3221225472 ZCUF_UDB3_Bit_0 "ZCU_F Network management user data 3 Bit 0";
CM_ SG_ 3221225472 ZCUF_UDB3_Bit_1 "ZCU_F Network management user data 3 Bit 1";
CM_ SG_ 3221225472 ZCUF_UDB3_Bit_2 "ZCU_F Network management user data 3 Bit 2";
CM_ SG_ 3221225472 ZCUF_UDB3_Bit_3 "ZCU_F Network management user data 3 Bit 3";
CM_ SG_ 3221225472 ZCUF_UDB3_Bit_4 "ZCU_F Network management user data 3 Bit 4";
CM_ SG_ 3221225472 ZCUF_UDB3_Bit_5 "ZCU_F Network management user data 3 Bit 5";
CM_ SG_ 3221225472 ZCUF_UDB3_Bit_6 "ZCU_F Network management user data 3 Bit 6";
CM_ SG_ 3221225472 ZCUF_UDB3_Bit_7 "ZCU_F Network management user data 3 Bit 7";
CM_ SG_ 3221225472 ZCUF_UDB4_Bit_0 "ZCU_F Network management user data 4 Bit 0";
CM_ SG_ 3221225472 ZCUF_UDB4_Bit_1 "ZCU_F Network management user data 4 Bit 1";
CM_ SG_ 3221225472 ZCUF_UDB4_Bit_2 "ZCU_F Network management user data 4 Bit 2";
CM_ SG_ 3221225472 ZCUF_UDB4_Bit_3 "ZCU_F Network management user data 4 Bit 3";
CM_ SG_ 3221225472 ZCUF_UDB4_Bit_4 "ZCU_F Network management user data 4 Bit 4";
CM_ SG_ 3221225472 ZCUF_UDB4_Bit_5 "ZCU_F Network management user data 4 Bit 5";
CM_ SG_ 3221225472 ZCUF_UDB4_Bit_6 "ZCU_F Network management user data 4 Bit 6";
CM_ SG_ 3221225472 ZCUF_UDB4_Bit_7 "ZCU_F Network management user data 4 Bit 7";
CM_ SG_ 3221225472 ZCUF_UDB5_Bit_0 "ZCU_F Network management user data 5 Bit 0";
CM_ SG_ 3221225472 ZCUF_UDB5_Bit_1 "ZCU_F Network management user data 5 Bit 1";
CM_ SG_ 3221225472 ZCUF_UDB5_Bit_2 "ZCU_F Network management user data 5 Bit 2";
CM_ SG_ 3221225472 ZCUF_UDB5_Bit_3 "ZCU_F Network management user data 5 Bit 3";
CM_ SG_ 3221225472 ZCUF_UDB5_Bit_4 "ZCU_F Network management user data 5 Bit 4";
CM_ SG_ 3221225472 ZCUF_UDB5_Bit_5 "ZCU_F Network management user data 5 Bit 5";
CM_ SG_ 3221225472 ZCUF_UDB5_Bit_6 "ZCU_F Network management user data 5 Bit 6";
CM_ SG_ 3221225472 ZCUF_UDB5_Bit_7 "ZCU_F Network management user data 5 Bit 7";
CM_ BO_ 1663 "Diagnostic Functional Request
";
CM_ SG_ 1663 OBD_FuncDiagResp_Byte0 "Diagnostic Signal Data Request Byte0
";
CM_ SG_ 1663 OBD_FuncDiagResp_Byte1 "Diagnostic Signal Data Request Byte1
";
CM_ SG_ 1663 OBD_FuncDiagResp_Byte2 "Diagnostic Signal Data Request Byte2
";
CM_ SG_ 1663 OBD_FuncDiagResp_Byte3 "Diagnostic Signal Data Request Byte3
";
CM_ SG_ 1663 OBD_FuncDiagResp_Byte4 "Diagnostic Signal Data Request Byte4
";
CM_ SG_ 1663 OBD_FuncDiagResp_Byte5 "Diagnostic Signal Data Request Byte5
";
CM_ SG_ 1663 OBD_FuncDiagResp_Byte6 "Diagnostic Signal Data Request Byte6
";
CM_ SG_ 1663 OBD_FuncDiagResp_Byte7 "Diagnostic Signal Data Request Byte7
";
CM_ BO_ 99 "Airbag Control Module Crash Status
";
CM_ SG_ 99 CRC_ACM_CrashStat "Cyclic Redundancy Check Profile 1c";
CM_ SG_ 99 AlvCtr_ACM_CrashStat "Alive Counter Profile 1c
";
CM_ SG_ 99 Airbg_CrashSts "crash status";
CM_ BO_ 102 "Electric Power Steering-Steering Feedback Actuator 1 (Except SFA And RWA)";
CM_ SG_ 102 CRC_EPS_SFA_SteerWhl_Pub_Info "Cyclic redundancy check Profile 1C";
CM_ SG_ 102 AlvCtr_EPS_SFA_SteerWhl_Pub_Info "Alive Counter Profile 1C";
CM_ SG_ 102 Stbwr_SfaSteerWhlTq "Torque applied to the steering wheel ";
CM_ SG_ 102 Stbwr_SfaEmgcyReq "Steering emergency request ";
CM_ SG_ 102 Stbwr_SfaSteerWhlAg "SFA Calculated Steering Angle ";
CM_ SG_ 102 Stbwr_TunSts "Status feedback based on vehicle mode ";
CM_ SG_ 102 Stbwr_CentrgSts "SFA Centering status ";
CM_ SG_ 102 Stbwr_SfaCtlMode "SFA control mode for Soft lock information to driver 
";
CM_ BO_ 103 "Vehicle Control Unit Traction system Information";
CM_ SG_ 103 CRC_VCU_ETractSys_Info "Cyclic redundancy check Profile 5";
CM_ SG_ 103 AlvCtr_VCU_ETractSys_Info "Alive Counter Profile 5
";
CM_ SG_ 103 Dtqmt_TgtTqEdsRe "Target torque of electric machine system 1";
CM_ SG_ 103 Dtqmt_TgtTqEdsFrnt "Target torque of electric machine system 2
";
CM_ BO_ 118 "Rear Wheel Steering Module Info";
CM_ SG_ 118 CRC_RWSM_Info "Cyclic redundancy check Profile 5";
CM_ SG_ 118 AlvCtr_RWSM_Info "Alive Counter Profile 5
";
CM_ SG_ 118 ReWhlSteer_MeasdStkVal "REAR_RWA_Measured Stroke Value";
CM_ SG_ 118 ReWhlSteer_Sts "Rear wheel steering status ";
CM_ BO_ 119 "Battery Management System Status
";
CM_ SG_ 119 CRC_BMS_Sts "Cyclic Redundancy Check Profile 5";
CM_ SG_ 119 AlvCtr_BMS_Sts "Alive Counter Profile 5";
CM_ SG_ 119 Bms_BatPreCdnSts "HV battery preconditioning status";
CM_ BO_ 128 "Electric Power Steering-Road Wheel Actuator 1 Pinion Info exchanged (Except SFA And RWA)";
CM_ SG_ 128 CRC_EPS_RWA_Pinion_Pub_Info "Cyclic redundancy check Profile 5";
CM_ SG_ 128 AlvCtr_EPS_RWA_Pinion_Pub_Info "Alive Counter Profile 5";
CM_ SG_ 128 Stbwr_RwaPinionAg "RWA pinion angle value";
CM_ SG_ 128 Stbwr_RwaPinionAgSpd "RWA Pinion Angle Speed";
CM_ SG_ 128 Stbwr_RwaRackPosn "RWA Current Rack Position";
CM_ SG_ 128 Stbwr_RwaRackSpd "RWA Speed Feedback";
CM_ BO_ 160 "Electronic Brake Control Module Vehicle Information
";
CM_ SG_ 160 CRC_EBCM_Veh_Info "Cyclic redundancy check Profile 5";
CM_ SG_ 160 AlvCtr_EBCM_Veh_Info "Alive Counter Profile 5
";
CM_ SG_ 160 Abs_ActVehSpd "Actual vehicle speed";
CM_ BO_ 211 "Front Zone Control Unit Clamp Information
";
CM_ SG_ 211 CRC_ZCUF_Clamp_Info "Cyclic Redundancy Check Profile 1c ";
CM_ SG_ 211 AlvCtr_ZCUF_Clamp_Info "Alive Counter Profile 1c";
CM_ SG_ 211 Clmmg_VehSt "Vehicle State";
CM_ SG_ 211 Clmmg_CL15_L "Ignition switch status - KL15";
CM_ SG_ 211 Clmmg_CL30S_L "Switched clamp 30 power supply.";
CM_ SG_ 211 Lvm_LoaShedReq "load shedding request for LV";
CM_ BO_ 223 "Air Spring Suspension Unit Sensor Info";
CM_ SG_ 223 CRC_ASU_SnsrInfo "Cyclic Redundancy Check Profile 5";
CM_ SG_ 223 AlvCtr_ASU_SnsrInfo "Alive Counter Profile 5";
CM_ SG_ 223 AirSuspUnit_HeiFL "Front Left Height Sensor Info";
CM_ SG_ 223 AirSuspUnit_HeiFR "Front Right Height Sensor Info";
CM_ SG_ 223 AirSuspUnit_HeiRR "Rear Right Height Sensor Info";
CM_ SG_ 223 AirSuspUnit_HeiRL "Rear Left Height Sensor Info";
CM_ SG_ 223 AirSuspUnit_HeiSts "Height status depend on level sensor information";
CM_ SG_ 223 AirSuspUnit_CdcModeSts "Damping Stiffness status";
CM_ SG_ 223 AirSuspUnit_IngrsModAck "In-Egress mode Acknowledgement";
CM_ SG_ 223 AirSuspUnit_SprgModeSts "Spring Stiffness status";
CM_ SG_ 223 AirSuspUnit_CmprSts "Compressor status Info";
CM_ SG_ 223 AirSuspUnit_SrvModeSts "ASU sends Service mode enable/Disabled status to IVI";
CM_ SG_ 223 AirSuspUnit_AirTankP "Air_Tank_pressure_information";
CM_ SG_ 223 AirSuspUnit_Sts "Air suspension available unavailable status to user ";
CM_ BO_ 273 "Vehicle Control Unit Battery information";
CM_ SG_ 273 CRC_VCU_Batt_Info "Cyclic redundancy check Profile 5";
CM_ SG_ 273 AlvCtr_VCU_Batt_Info "Alive Counter Profile 5";
CM_ SG_ 273 Bms_PackI "Battery Pack Total Current";
CM_ SG_ 273 Bms_PackU "Pack Voltage";
CM_ SG_ 273 Acchg_RmngChgTi "BMS Remain Charging Time";
CM_ SG_ 273 Fschg_RmngChgTi "BMS Remaining Charging Time for displaying only ";
CM_ BO_ 279 "Vehicle Control Unit Charging Information";
CM_ SG_ 279 CRC_VCU_Charging_Info "Cyclic redundancy check Profile 5";
CM_ SG_ 279 AlvCtr_VCU_Charging_Info "Alive Counter Profile 5";
CM_ SG_ 279 Fschg_DcChgGunIn "Connection Status Of Dc Fast Charging Gun";
CM_ SG_ 279 Acchg_AcChgGunIn "Slow Charge Gun Insert Status ";
CM_ BO_ 285 "Vehicle Control Unit HV Drive system status";
CM_ SG_ 285 CRC_VCU_HVDrvSys_Status "Cyclic redundancy check Profile 1C
";
CM_ SG_ 285 AlvCtr_VCU_HVDrvSys_Status "Alive Counter Profile 1C
";
CM_ SG_ 285 Drvmc_ActDrvMode "Active Drive mode";
CM_ SG_ 285 Enmgt_HvDrvSysSts "HV Drive System Status";
CM_ SG_ 285 Drvmc_ActDrvModeVld "Vehicle drive mode status";
CM_ SG_ 285 Eshift_ActGear "Actual Gear Status";
CM_ BO_ 304 "Electronic Brake Control Module status request";
CM_ SG_ 304 CRC_EBCM_Sts_Req "Cyclic Redundancy Check Profile 5";
CM_ SG_ 304 AlvCtr_EBCM_Sts_Req "Alive Counter Profile 5";
CM_ SG_ 304 Abs_IntvSts "ABS activation indication ";
CM_ SG_ 304 Drvac_TcsAvl "Traction control system available ";
CM_ SG_ 304 Drvac_FldLvlIndcrBrkFldSts "Brake Fluid Status ";
CM_ SG_ 304 Ecpbk_BrkLiOnReq "Brake lights on requested by EPB auto apply";
CM_ SG_ 304 Ebd_SysSts "indicates EBD active deactive status ";
CM_ SG_ 304 Drvac_HdcSts "Status of HDC system ";
CM_ SG_ 304 Drvac_TcsSts "Status of TCS system ";
CM_ SG_ 304 Drvac_CorneringBrkCtlSts "Status of CBC system ";
CM_ SG_ 304 Drvac_HillStrtAssiSts "Status of Hill Start Assist system ";
CM_ SG_ 304 Ecpbk_Sts "Status signal for electric park brake function ";
CM_ BO_ 313 "Rear Zone Control Unit Lamp Command";
CM_ SG_ 313 CRC_ZCUR_LampCmd "Cyclic Redundancy Check Profile 5";
CM_ SG_ 313 AlvCtr_ZCUR_LampCmd "Alive Counter Profile 5

";
CM_ BO_ 317 "Smart Battery Module LV Battery Information 1";
CM_ SG_ 317 CRC_SBM_LVBatInfo_1 "Cyclic Redundancy Check Profile 1c";
CM_ SG_ 317 AlvCtr_SBM_LVBatInfo_1 "Alive Counter Profile 1c";
CM_ SG_ 317 Sbm_LVBattV "LV battery voltage";
CM_ SG_ 317 Sbm_LvBatThermRunawy "SBM Thermal Runaway Status
";
CM_ BO_ 318 "Smart Battery Module LV Battery Information 2
";
CM_ SG_ 318 CRC_SBM_LVBatInfo_2 "Cyclic Redundancy Check Profile 5";
CM_ SG_ 318 AlvCtr_SBM_LVBatInfo_2 "Alive Counter Profile 5";
CM_ SG_ 318 Sbm_LVBatActSoh "LV battery actual SoH";
CM_ SG_ 318 Sbm_CriticalSoCAlert "LV Battery critical Soc Alert (<10%) (ASIL B)";
CM_ SG_ 318 Sbm_LvBattT "LV Battery Temprature";
CM_ BO_ 327 "Vehicle Control Unit Consumption Information";
CM_ SG_ 327 Engmt_LvAuxAvgEngCns "Average energy consumption of LV auxilixaries";
CM_ SG_ 327 Engmt_InttsEngCnsRate "Instataneous energy consumpution";
CM_ SG_ 327 Engmt_TotAvgEngCns "Total Average energy consumption value";
CM_ SG_ 327 Engmt_EdsAvgEngCns "Average energy consumption of EDS";
CM_ SG_ 327 Engmt_ThermAvgEngCns "Average energy consumption of CCU";
CM_ BO_ 349 "Vehicle Control Unit features info to IVI";
CM_ SG_ 349 CRC_VCU_To_Veh_Info "Cyclic Redundancy check Profilr 5";
CM_ SG_ 349 AlvCtr_VCU_To_Veh_Info "Alive Counter Profile 5";
CM_ SG_ 349 Acchg_HVBatSoc "HV battery SOC for displaying only";
CM_ SG_ 349 Acchg_AcChgSts "Charge Status";
CM_ SG_ 349 Awd_ActWhlDrvMode "Actual wheel drive mode";
CM_ SG_ 349 Engmt_ChrgrDlvPwr "Total Power delivered by charger while charging";
CM_ SG_ 349 Engmt_VehRmngDrvRng "Remaining Range information";
CM_ SG_ 349 Cregb_CoastRgnLvlIndcr "Actual coasting level";
CM_ SG_ 349 Fschg_VehChrgnSts "Vehicle Charging Status";
CM_ SG_ 349 Eshift_ChngGearFromPark "Change gear alert from P to drive";
CM_ SG_ 349 Engmt_VehMilg "Vehicle milage information";
CM_ SG_ 349 Fschg_HVBatSoc "HV Battery SOC for displaying only";
CM_ SG_ 349 Fschg_ChgGunLockSts "Charging gun status";
CM_ SG_ 349 Awd_ActWhlDrvModeVld "Validity of All wheel drive mode";
CM_ BO_ 367 "Zone Control Unit-Front RLHS Information";
CM_ SG_ 367 CRC_ZCUF_RlhsLight_Info "Cyclic Redundancy Check Profile 1c
";
CM_ SG_ 367 AlvCtr_ZCUF_RlhsLight_Info "Alive Counter Profile 1c";
CM_ SG_ 367 Rlhs_SolarDrvr "Driver Side Solar intensity";
CM_ SG_ 367 Rlhs_SolarPass "Passenger Side Solar intensity";
CM_ BO_ 371 "Headlamp Module-Left Front Lamp Status";
CM_ SG_ 371 CRC_HDLML_FrontLamp_Sts "Cyclic Redundancy Check Profile 5";
CM_ SG_ 371 AlvCtr_HDLML_FrontLamp_Sts "Alive Counter Profile 5

";
CM_ SG_ 371 Hdlamp_LeLoBeamLampSts "Low Beam LH On Off Status by HDLM Fusa signal (ASIL B)";
CM_ SG_ 371 Hdlamp_LeHiBeamLampSts "High Beam LH On Off Status by HDLM Fusa signal (ASIL B)";
CM_ BO_ 377 "Headlamp Module-Right Front Lamp Status";
CM_ SG_ 377 CRC_HDLMR_FrontLamp_Sts "Cyclic Redundancy Check Profile 5";
CM_ SG_ 377 AlvCtr_HDLMR_FrontLamp_Sts "Alive Counter Profile 5

";
CM_ SG_ 377 Hdlamp_RiLoBeamLampSts "Low Beam RH On Off Status by HDLM Fusa signal (ASIL B)";
CM_ SG_ 377 Hdlamp_RiHiBeamLampSts "High  Beam RH On Off Status by HDLM";
CM_ BO_ 383 "Signal Lamp Module Front Left Status";
CM_ SG_ 383 CRC_SLMFL_FrontLamp_Sts "Cyclic Redundancy Check Profile 5";
CM_ SG_ 383 AlvCtr_SLMFL_FrontLamp_Sts "Alive Counter Profile 5

";
CM_ SG_ 383 Hdlamp_LeFrntPosnLampSts " Left Position light status combination of  Front and rear ";
CM_ SG_ 383 Hdlamp_LeDRLLampSts "Left DRL  lamp  ON ,OFF Status (Fusa ASIL B)";
CM_ SG_ 383 Hdlamp_FrntLeBodyTurnIndcrSts "Left side turn indicator On OFF status ";
CM_ BO_ 387 "Signal Lamp Module Front Right Status";
CM_ SG_ 387 CRC_SLMFR_FrontLamp_Sts "Cyclic Redundancy Check Profile 5";
CM_ SG_ 387 AlvCtr_SLMFR_FrontLamp_Sts "Alive Counter Profile 5

";
CM_ SG_ 387 Hdlamp_RiFrntPosnLampSts " Right Position light status combination of  Front and rear ";
CM_ SG_ 387 Hdlamp_RiDRLLampSts "Right DRL  lamp  ON ,OFF Status (Fusa ASIL B)";
CM_ SG_ 387 Hdlamp_FrntRiBodyTurnIndcrSts "Right side turn indicator On OFF status for IVI display and audible warning";
CM_ BO_ 393 "Rear Lamp Module Left Status";
CM_ SG_ 393 CRC_RLML_RearLampSts "Cyclic Redundancy Check Profile 5";
CM_ SG_ 393 AlvCtr_RLML_RearLampSts "Alive Counter Profile 5

";
CM_ SG_ 393 Relamp_LeBodyBrkLampSts "Left brake lamp OnOff Status";
CM_ SG_ 393 Relamp_ReLeBodyPosnLampSts "Rear Left  Turn light on off status";
CM_ SG_ 393 Relamp_ReLeBodyTurnIndcrSts "Rear Left Position light status";
CM_ BO_ 399 "Rear Lamp Module Right Status";
CM_ SG_ 399 CRC_RLMR_RearLampSts "Cyclic Redundancy Check Profile 5";
CM_ SG_ 399 AlvCtr_RLMR_RearLampSts "Alive Counter Profile 5

";
CM_ SG_ 399 Relamp_RiBodyBrkLampSts "Right brake lamp OnOff Status";
CM_ SG_ 399 Relamp_ReRiBodyPosnLampSts "Rear Right Position light status";
CM_ SG_ 399 Relamp_ReRiBodyTurnIndcrSts "Rear Right Turn light on off status";
CM_ BO_ 403 "Tail Lamp Module Rear left Lamp status";
CM_ SG_ 403 CRC_TLML_RearLampSts "Cyclic Redundancy Check Profile 5";
CM_ SG_ 403 AlvCtr_TLML_RearLampSts "Alive Counter Profile 5

";
CM_ SG_ 403 Relamp_LeTLGBrkLampSts "Left brake lamp OnOff Status";
CM_ SG_ 403 Relamp_ReLeTLGPosnLampSts "Rear Left Position light status";
CM_ SG_ 403 Relamp_ReLeTLGTurnIndcrSts "Rear Left  Turn light on off status";
CM_ BO_ 409 "Front Center Signature Light Module Lamp Status";
CM_ SG_ 409 CRC_SLMFC_LampSts "Cyclic Redundancy check Profilr 5";
CM_ SG_ 409 AlvCtr_SLMFC_LampSts "Alive Counter Profile 5";
CM_ SG_ 409 Hdlamp_FrntCentr_LeSignLampSts "Front left signature lamp status";
CM_ SG_ 409 Hdlamp_FrntCentr_RiSignLampSts "Front right signature lamp status";
CM_ BO_ 410 "Signature Light Module - Rear Center Status";
CM_ SG_ 410 CRC_SLMRC_LampSts "Cyclic redundancy check Profile 5";
CM_ SG_ 410 AlvCtr_SLMRC_LampSts "Alive Counter Profile 5";
CM_ SG_ 410 Relamp_FrntCentr_LeSignLampSts "Rear left signature lamp status";
CM_ SG_ 410 Relamp_FrntCentr_RiSignLampSts "Rear Right signature lamp status";
CM_ BO_ 415 "Tail Lamp Module Rear Right Lamp status";
CM_ SG_ 415 CRC_TLMR_RearLampSts "Cyclic Redundancy Check Profile 5";
CM_ SG_ 415 AlvCtr_TLMR_RearLampSts "Alive Counter Profile 5

";
CM_ SG_ 415 Relamp_RiTLGBrkLampSts "Right brake lamp OnOff Status";
CM_ SG_ 415 Relamp_ReRiTLGPosnLampSts "Rear Right Position light status";
CM_ SG_ 415 Relamp_ReRiTLGTurnIndcrSts "Rear Right Turn light on off status";
CM_ BO_ 419 "Climate Control Unit Power Request";
CM_ SG_ 419 Ccsf_AgsOpenReq "Grill Open/Close Request";
CM_ BO_ 425 "Climate Control Unit Temperature Feedback";
CM_ SG_ 425 CRC_CCU_TemperatureFbk "Cyclic Redundancy Check Profile 1c";
CM_ SG_ 425 AlvCtr_CCU_TemperatureFbk "Alive Counter Profile 1c";
CM_ SG_ 425 Caclh_AmbT "Ambient Temperature";
CM_ BO_ 431 "Zone Control Unit-Front RLHS Information";
CM_ SG_ 431 CRC_ZCUF_RlhsRainHumidity_Info "Cyclic Redundancy Check Profile 1c ";
CM_ SG_ 431 AlvCtr_ZCUF_RlhsRainHumidity_Inf "Alive Counter Profile 1c";
CM_ SG_ 431 Rlhs_RainFallSts "Rainfall status";
CM_ BO_ 740 "Rear View Camera Information";
CM_ SG_ 740 CRC_ADAS_Rvc_Info "Cyclic Redundancy Check Profile 5";
CM_ SG_ 740 AlvCtr_ADAS_Rvc_Info "Alive Counter Profile 5";
CM_ SG_ 740 Rvc_ReBlindSpot_Sts "Current Status of 'Rear Blind Spot Monitoring' arround Vehicle";
CM_ BO_ 869 "In Vehicle Infotainment Ept Feature Information";
CM_ SG_ 869 IVI_Acchr_chrggunUnlck_cmd "Charge gun unlock command via IVI,Mobile,Key Fob";
CM_ SG_ 869 Acchg_IviChgStopReq "Charge stop request via IVI";
CM_ SG_ 869 Acchg_ChrgnSdleTi "Scheduled charge start time by IVI touch screen.";
CM_ SG_ 869 Acchg_IviMaxChgILim "Max charge current limit for Scheduled Charging via IVI";
CM_ SG_ 869 Acchg_PeakHourMngtEna "Peak hour Management enable for schedule charging via IVI";
CM_ SG_ 869 Acchg_IviEnaSdleChrgn "Enabling /disabling command for scheduled charging.via IVI";
CM_ SG_ 869 Acchg_IviTgtChgSocLvl " Target SOC limit from IVI";
CM_ SG_ 869 Awd_WhlDrvModeSeln "Driver wheel drive mode selection request";
CM_ SG_ 869 Eshift_TowMode_Req "Tow mode set from IVI ";
CM_ SG_ 869 Drvmc_ValetModeAcvnSts "This signal indicates Valet Mode active deasctive statu";
CM_ SG_ 869 Drvmc_WashModeAcvnSts "This signal indicates Wash Mode active deactive status ";
CM_ SG_ 869 Dtqmt_SrvModeSpdLim " speed Limit for Service mode from IVI";
CM_ SG_ 869 Drvmc_ShowroomModeAcvnSts "This signal indicates showroom Mode active deactive status ";
CM_ SG_ 869 Dtqmt_SrvSpdOvrrEna "Service Mode Speed Override Enable";
CM_ SG_ 869 Drvmc_TrsptModeAcvnSts "This signal indicates Transport mode active deactive status ";
CM_ SG_ 869 Dtqmt_ValetModeSpdLim " speed Limit for valet mode from IVI";
CM_ SG_ 869 Drvmc_DrvModeSelnReq "Vehicle drive mode Request from IVI";
CM_ SG_ 869 Cregb_RegenLvl_Req "Regen level request";
CM_ BO_ 873 "Rear Zone Control Unit IVI Status";
CM_ SG_ 873 CRC_ZCUR_IVI_Sts "Cyclic redundancy check Profile 5";
CM_ SG_ 873 AlvCtr_ZCUR_IVI_Sts "Alive Counter Profile 5";
CM_ SG_ 873 Acttg_TailGateSts "Tailgate Open/Close status";
CM_ SG_ 873 Acttg_TailGateNmlznSts "Tailgate Normalised state ";
CM_ SG_ 873 Acttg_TailGateAjarSts "TLG ajar Switch status";
CM_ SG_ 873 Acttg_ActPosnAgSts "Tailgate Actual position ";
CM_ SG_ 873 SeatCfmt_ReLeVentnSts "RearLH seat ventilation status";
CM_ SG_ 873 SeatCfmt_ReRiVentnSts "RearRH seat ventilation status";
CM_ SG_ 873 SeatCfmt_ReLeVentnCshnFanFailSts "RearLH seat ventilation seat cushion fan failuare status";
CM_ SG_ 873 SeatCfmt_ReLeVentnSqubFanFailSts "RearLH seat ventilation squab fan failuare status";
CM_ SG_ 873 SeatCfmt_ReRiVentnCshnFanFailSts "RearRH seat ventilation cushion fan failuare status";
CM_ SG_ 873 SeatCfmt_ReRiVentnSqubFanFailSts "RearRH seat ventilation squab fan failuare status";
CM_ SG_ 873 ChrgrPort_LockUnlck_Sts "Charge port lock unlock actuator status";
CM_ SG_ 873 ChrgrPort_Ajar_Sts "Charge Port  Door Open/Close Status";
CM_ SG_ 873 Relamp_RiLicePlateSts "Rear Right License plate lamp status";
CM_ SG_ 873 Relamp_LeLicePlateSts "Rear Left License plate lamp status";
CM_ SG_ 873 Relamp_FogLampSts "Rear Fog lamp status";
CM_ SG_ 873 Relamp_ChmslSts "Rear center high mount stop lamp status";
CM_ SG_ 873 Relamp_RevLmpSts "Reverse lamp status";
CM_ BO_ 883 "Climate Control Unit Fault Status";
CM_ SG_ 883 CRC_CCU_FaultSts "Cyclic redundancy check Profile 5";
CM_ SG_ 883 AlvCtr_CCU_FaultSts "Alive Counter Profile 1c";
CM_ SG_ 883 Ccsf_FrntBlowrFltSts "Front blower fail status";
CM_ SG_ 883 Ccsr_ReBlowrFltSts "rear blower motor fails status";
CM_ SG_ 883 Ccsf_IoniserFltSts "Ionizer fail status";
CM_ SG_ 883 Ccsf_FragnConnLoss "Failure of connectivity between CCU and Fragrance Selection Module";
CM_ SG_ 883 Ccsf_FrgrncFltSts "Fragarance module fail status";
CM_ SG_ 883 Ccsf_IoniserConnLoss "failure of connectivity between CCU and Ioniser Module";
CM_ SG_ 883 Ccsf_DemistFlapFltSts "Defrost Flap Fault";
CM_ BO_ 889 "Climate Control Unit System Status";
CM_ SG_ 889 CRC_CCU_ClimSys_Sts "Cyclic Redundancy Check Profile 1c";
CM_ SG_ 889 AlvCtr_CCU_ClimSys_Sts "Alive Counter Profile 1c";
CM_ SG_ 889 Ccsf_AirModeSelnFb "Air mode selection feedback";
CM_ SG_ 889 Ccsf_FrntBlowrLvlFb "Front blower speed feedback";
CM_ SG_ 889 Ccsf_IoniserOnOffSts "Ionizer on off status";
CM_ SG_ 889 Ccsf_DrvrDemistRcmn "HVAC Front Defrost Recommadation to driver";
CM_ SG_ 889 Ccsr_ReBlowrLvlFb "rear blower motor Status";
CM_ SG_ 889 Ccsf_RclFlapPos "Recirculation flap position";
CM_ SG_ 889 Ccsf_Co2Lvl "Co2 level status";
CM_ SG_ 889 Ccsf_CenLeVenDirSts "Vent motor Front Left Status";
CM_ SG_ 889 Ccsf_CenRiVenDirSts "Vent motor Front Right Status";
CM_ SG_ 889 Ccsf_AirQlyIdx "Air quality status";
CM_ SG_ 889 Ccsf_RclModFb "Recirculation mode Feedback";
CM_ BO_ 895 "Climate Control Unit AC Op Mode Status";
CM_ SG_ 895 CRC_CCU_AcOpMode_Sts "Cyclic redundancy check Profile 5";
CM_ SG_ 895 AlvCtr_CCU_AcOpMode_Sts "Alive Counter Profile 1c";
CM_ SG_ 895 Ccsr_HaloTSts "Current Halo Temperature Status
";
CM_ SG_ 895 Ccsf_AcAutoModeSts "Auto AC ON/OFF status from CCU for display";
CM_ SG_ 895 Caclh_AcLowPwrModeSts "AC in low power mode";
CM_ SG_ 895 Ccsf_DemistDefrstSts "Demist on/off status";
CM_ SG_ 895 Ccsf_FrntAcOnOffSts "HVAC Status Front";
CM_ SG_ 895 Caclh_FrntAcOpModeSts "Front AC opmode status";
CM_ SG_ 895 Caclh_ReAcOpModeSts "Rear AC opmode status";
CM_ SG_ 895 Ccsr_ReAcOnOffSts "Rear AC (Halo) OnOff Status";
CM_ BO_ 899 "Climate Control Unit Fragnance Status
";
CM_ SG_ 899 CRC_CCU_ClimFrgrnc_Sts "Cyclic redundancy check Profile 5";
CM_ SG_ 899 AlvCtr_CCU_ClimFrgrnc_Sts "Alive Counter Profile 1c";
CM_ SG_ 899 Ccsf_Frgrnc3levelSts "HVAC Front Fragnace3 Level status";
CM_ SG_ 899 Ccsf_FrgrncIntenSts "Fragrance intensity status";
CM_ SG_ 899 Ccsf_FrgrncOnOffSts "Fragrance on off status";
CM_ SG_ 899 Ccsf_Frgrnc1levelSts "HVAC Front Fragnace1 Level status";
CM_ SG_ 899 Ccsf_FrgrncSelnSts "Fragrance selection status";
CM_ SG_ 899 Ccsf_Frgrnc2levelSts "HVAC Front Fragnace2 Level status";
CM_ BO_ 911 "Power Seat Module – Driver Seat Adjustment Status";
CM_ SG_ 911 CRC_PSMD_SeatAdjustment_Status "Cyclic Redundancy Check Profile 1c  ";
CM_ SG_ 911 AlvCtr_PSMD_SeatAdjmt_Sts "Alive Counter Profile 1c";
CM_ SG_ 911 SeatAdjmt_DrvLumInOutPosn "Driver seat lumbar pump in/out position status to IVI for notification";
CM_ SG_ 911 SeatAdjmt_DrvLumUpDwnPosn "Driver seat recliner pump up/down position status  to IVI for notification";
CM_ SG_ 911 SeatAdjmt_DrvLumSysFailSts "Lumbar support pneumatic pump failure status";
CM_ SG_ 911 SeatAdjmt_DrvHeiUpDwnMotSts "Driver seat height motor  status";
CM_ SG_ 911 SeatAdjmt_DrvReclUpDwnMotSts "Driver seat recliner motor status";
CM_ SG_ 911 SeatAdjmt_DrvAdjmtSts "Driver seat user profile recall adjustment status notification to IVI";
CM_ SG_ 911 SeatAdjmt_DrvFrntBackMotSts "Driver seat forward backward motor status ";
CM_ SG_ 911 SeatAdjmt_DrvTiltUpDwnMotSts "Driver seat cushion tilt motor status";
CM_ BO_ 915 "Power Seat Module – Passenger Seat Adjustment Status";
CM_ SG_ 915 CRC_PSMP_SeatAdjustment_Status "Cyclic Redundancy Check Profile 1c";
CM_ SG_ 915 AlvCtr_PSMP_SeatAdjmt_Sts "Alive Counter Profile 1c  ";
CM_ SG_ 915 SeatAdjmt_PassLumInOutPosn "Passenger seat lumbar pump in/out position status";
CM_ SG_ 915 SeatAdjmt_PassLumUpDownPosn "Passenger seat lumbar pump up/down position status";
CM_ SG_ 915 SeatAdjmt_PassLumSysFailSts "Passenger seat lumbar system fail status";
CM_ SG_ 915 SeatAdjmt_PassReclUpDwnMotSts "Passanger seat recliner motor  status";
CM_ SG_ 915 SeatAdjmt_PassHeiUpDwnMotSts_ "Passanger  seat height motor  status";
CM_ SG_ 915 SeatAdjmt_PassAdjmtSts "Passanger seat user profile recall adjustment status notification to IVI";
CM_ SG_ 915 SeatAdjmt_PassFowdBawdMotSts "Passenger seat forward backward motor status ";
CM_ SG_ 915 SeatAdjmt_PassTiltUpDwnMotSts "Passenger seat cushion tilt motor status ";
CM_ BO_ 921 "Power Seat Module – Driver Seat Position Status";
CM_ SG_ 921 CRC_PSMD_SeatPos_Status "Cyclic Redundancy Check Profile 1c  ";
CM_ SG_ 921 AlvCtr_PSMD_SeatPos_Status "Alive Counter Profile 1c";
CM_ SG_ 921 SeatAdjmt_DrvFowdBawdPosn "Driver seat forward backward motor position status to IVI for notification";
CM_ SG_ 921 SeatAdjmt_DrvHeiUpDwnPosn "Driver seat height motor position status to IVI for notification";
CM_ SG_ 921 SeatAdjmt_DrvReclUpDwnPosn "Driver seat recliner motor position status to IVI for notification";
CM_ SG_ 921 SeatAdjmt_DrvTiltUpDwnPosn "Driver seat tilt motor  position status to IVI for notification";
CM_ BO_ 927 "Power Seat Module – Driver Seat Comfort Status";
CM_ SG_ 927 CRC_PSMD_SeatCmfrt_Status "Cyclic Redundancy Check Profile 1c";
CM_ SG_ 927 AlvCtr_PSMD_SeatCmfrt_Status "Alive Counter Profile 1c  ";
CM_ SG_ 927 SeatCfmt_DrvHeatgSts "Driver seat heating Status";
CM_ SG_ 927 SeatCfmt_DrvVentnSts "Driver seat ventilation status";
CM_ SG_ 927 SeatCfmt_DrvVentnCshnFanFailSts "Driver seat ventilation cushion fan failure status";
CM_ SG_ 927 SeatCfmt_DrvHeatgBackPadFailSts "Driver seat heating back pad failure status";
CM_ SG_ 927 SeatCfmt_DrvMassgFailSts "Driver seat massage fail status via PSMD";
CM_ SG_ 927 SeatCfmt_DrvHeatgCshnPadFailSts "Driver seat heating cushion pad failure status";
CM_ SG_ 927 SeatCfmt_DrvMassg_Sts "Driver seat massage on/off status via PSMD";
CM_ SG_ 927 SeatCfmt_DrvVentnSqubFanFailSts "Driver seat ventilation squab fan failure status";
CM_ BO_ 931 "Power Seat Module – Passenger Seat Comfort Status";
CM_ SG_ 931 CRC_PSMP_SeatCmfrt_Status "Cyclic Redundancy Check Profile 1c";
CM_ SG_ 931 AlvCtr_PSMP_SeatCmfrt_Status "Alive Counter Profile 1c  ";
CM_ SG_ 931 SeatCfmt_PassVentnSts "Passanger seat ventilation status";
CM_ SG_ 931 SeatCfmt_PassHeatgSts "Passanger seat heating status";
CM_ SG_ 931 SeatCfmt_PassMassgSts "Passenger seat massage on/off status via PSMP";
CM_ SG_ 931 SeatCfmt_PassVentnSqubFanFailSts "Passanger seat ventilation squab fan failure status";
CM_ SG_ 931 SeatCfmt_PassMassgFailSts "Passenger seat massage fail status via PSMP";
CM_ SG_ 931 SeatCfmt_PassVentnCshnFanFailSts "Passanger seat ventilation cushion fan failure status";
CM_ SG_ 931 SeatCfmt_PassHeatgBackPadFailSts "Passanger seat heating back pad failure status";
CM_ SG_ 931 SeatCfmt_PassHeatgCshnPadFailSts "Passanger seat heating cushion pad failure status";
CM_ BO_ 937 "Power Seat Module – Passenger Seat Position Status";
CM_ SG_ 937 CRC_PSMP_SeatPos_Status "Cyclic Redundancy Check Profile 1c";
CM_ SG_ 937 AlvCtr_PSMP_SeatPos_Status "Alive Counter Profile 1c  ";
CM_ SG_ 937 SeatAdjmt_PassFowdBawdPosn "Passenger seat forward backward motor position status to IVI for notification";
CM_ SG_ 937 SeatAdjmt_PassHeiUpDwnPosn "Passenger seat height motor position status to IVI for notification";
CM_ SG_ 937 SeatAdjmt_PassReclUpDwnPosn "Passenger seat recliner motor position status to IVI for notification";
CM_ SG_ 937 SeatAdjmt_PassTiltUpDwnPosn "Passenger seat tilt motor  position status to IVI for notification";
CM_ BO_ 995 "Door Control Module Driver Closure Status";
CM_ SG_ 995 CRC_DCMD_ClosureSts "Cyclic Redundancy Check Profile 1c";
CM_ SG_ 995 AlvCtr_DCMD_ClosureSts "Alive Counter Profile 1c";
CM_ SG_ 995 Pwd_DrvrDoorSts "Driver  Gullwing Doors Ajar status ";
CM_ SG_ 995 CenLock_DrvrDoorLockUnlckSts "Driver door lock_Unlcok actuator Status";
CM_ SG_ 995 Pwd_DrvrDoorNmlznSts "Driver  Gullwing Doors Normalised_state";
CM_ SG_ 995 CenLock_DrvrDoorAjarSts "Driver Door Ajar Open/Close Status";
CM_ SG_ 995 Pwind_DrvWndwSts "Driver Power Window Status";
CM_ SG_ 995 Pwd_DrvDoorActPos "Driver Gullwing Door  Position Angle ";
CM_ BO_ 997 "In Vehicle Infotainment Passenger Seat Stored Profile";
CM_ SG_ 997 SeatAdjmt_PassHeiStoredPosn "Passanger seat height motor position stored in passanger user profile";
CM_ SG_ 997 SeatAdjmt_PassReclStoredPosn "Passanger seat recliner motor position stored in passanger user profile";
CM_ SG_ 997 SeatAdjmt_PassTiltStoredPosn "Passanger seat tilt motor position stored in passanger user profile";
CM_ SG_ 997 SeatAdjmt_PassFowdBawdStoredPosn "Passanger seat forward backward motor position stored in passanger user profile";
CM_ BO_ 999 "Vehicle Control Unit Status";
CM_ SG_ 999 CRC_VCU_Sts "Cyclic Redundancy Check Profile 5";
CM_ SG_ 999 AlvCtr_VCU_Sts "Alive Counter Profile 5";
CM_ SG_ 999 Engmt_LimphmSts "limp home mode enable Status";
CM_ SG_ 999 Fschg_ChgAuthenSts "Charging authetication from VCU";
CM_ SG_ 999 Acchg_ChgAuthnSts "Charging authetication from VCU";
CM_ SG_ 999 Thmgt_ThermFltSts "Individual fault status of thermal components";
CM_ SG_ 999 Cregb_CoastRgnTqPctg "Coasting Torque percetage value signal for IVI display purpose";
CM_ SG_ 999 Hfdia_RemdActn "High Voltage Interlock loop circuit error";
CM_ SG_ 999 Hvsco_HvSysSts "High Voltage system status";
CM_ BO_ 1001 "Door Control Module Passenger Closure Status";
CM_ SG_ 1001 CRC_DCMP_ClosureSts "Cyclic Redundancy Check Profile 1c ";
CM_ SG_ 1001 AlvCtr_DCMP_ClosureSts "Alive Counter Profile 1c ";
CM_ SG_ 1001 CenLock_PassDoorAjarSts "Passenger Door Open/Close Status";
CM_ SG_ 1001 CenLock_PassDoorLockUnlckSts "Passenger door lock_Unlcok actuator Status";
CM_ SG_ 1001 Pwd_PassDoorSts "Passenger Gullwing Doors Ajar status ";
CM_ SG_ 1001 Pwd_PassDoorActPos "Passenger Gullwing Doors Actual Position";
CM_ SG_ 1001 Pwind_PassWndwSts "PassengerPower  Window  Status";
CM_ SG_ 1001 Pwd_PassDoorNmlznSts "Passenger Gullwing Doors Normalised state";
CM_ BO_ 1007 "Door Control Module Rear Right Closure Status";
CM_ SG_ 1007 CRC_DCMRR_ClosureSts "Cyclic Redundancy Check Profile 1c  ";
CM_ SG_ 1007 AlvCtr_DCMRR_ClosureSts "Alive Counter Profile 1c";
CM_ SG_ 1007 CenLock_ReRiDoorLockUnlckSts "Rear Right  Door Lock/Unlock Status";
CM_ SG_ 1007 Pwind_ReRiWndwSts "Rear Right Door Power Window Status ";
CM_ BO_ 1011 "Door Control Module Rear Left Closure Status
";
CM_ SG_ 1011 CRC_DCMRL_ClosureSts "Cyclic Redundancy Check Profile 1c  ";
CM_ SG_ 1011 AlvCtr_DCMRL_ClosureSts "Alive Counter Profile 1c";
CM_ SG_ 1011 CenLock_ReLeDoorLockUnlckSts "Rear door RH lock_Unlcok actuator Status";
CM_ SG_ 1011 CenLock_ReLeDoorAjarSts "Rear door LH lock_Unlcok actuator Status";
CM_ SG_ 1011 Pwind_ReLeWndwSts "Rear Left Door Power Window Status ";
CM_ BO_ 1017 "Zone Control Unit-Front Wiper Status";
CM_ SG_ 1017 CRC_ZCUF_WiperSts "Cyclic redundancy check Profile 5";
CM_ SG_ 1017 AlvCtr_ZCUF_WiperSts "Alive Counter Profile 5
";
CM_ SG_ 1017 Wipr_FrntLeParkPosSts "Left side Wiper Motor park Position status";
CM_ SG_ 1017 Wipr_FrntLeSerPosSts "Front Left wiper service position Status";
CM_ SG_ 1017 Wipr_FrntLeSts "Wiper Motor send Left  Hand  motor ON/OFF status";
CM_ SG_ 1017 Wipr_FrntRiParkPosSts "Right side Wiper Motor park Position status";
CM_ SG_ 1017 Wipr_FrntRiSerPosSts "Front Right wiper service position Status";
CM_ SG_ 1017 Wipr_FrntRiSts "Wiper motor On/OFF status Front Left";
CM_ SG_ 1017 Wipr_WshrSts "Front washer status to IVI for indication";
CM_ SG_ 1017 Wipr_WshrFluidLevelSts "Washer Fluid Level Sts";
CM_ SG_ 1017 Wipr_FrntRiFaildSts "Wiper motor failure status Front Right";
CM_ SG_ 1017 Wipr_FrntLeFaildSts "Wiper motor failure status Front Left";
CM_ BO_ 1023 "Zone Control Unit-Front Climate Setting Temperature feedback";
CM_ SG_ 1023 Ccs_DrvrSideSetTValSts "Display set value of temperature Driver side";
CM_ SG_ 1023 Ccs_PassSideSetTValSts "Display set value of temperature Passenger side";
CM_ SG_ 1023 Ccs_ReRiSideSetTValSts "Display set value of temperature Rear Right side";
CM_ SG_ 1023 Ccs_ReLeSideSetTValSts "Display set value of temperature Rear Left side";
CM_ SG_ 1023 Ccs_HaloSetTValSts "Display set value of temperature Halo side";
CM_ BO_ 1027 "Central Lock Information";
CM_ SG_ 1027 CRC_ZCUF_CenLock_Info "Cyclic Redundancy Check Profile 1c

";
CM_ SG_ 1027 AlvCtr_ZCUF_CenLock_Info "Alive Counter Profile 1c";
CM_ SG_ 1027 CenLock_CAppLockUnlckSt "Central lock Remote lock unlock status";
CM_ SG_ 1027 CenLock_LockUnlckSts "Central lock unlock current status";
CM_ BO_ 1123 "Airbag Control Module Active Tracking Status
";
CM_ SG_ 1123 CRC_ACM_ActvTrackingStatus "Cyclic Redundancy Check Profile 1c";
CM_ SG_ 1123 AlvCtr_ACM_ActvTrackingStatus "Alive Counter Profile 1c
";
CM_ SG_ 1123 AirBg_SeatTrackPosPass "passenger seat position on track";
CM_ SG_ 1123 AirBg_SeatTrackPosDrvr "driver seat position on track";
CM_ SG_ 1123 AirBg_PassAirbgDeacSts "passenger airbag deactivation confirmation status";
CM_ BO_ 1125 "In Vehicle Infotainment Driver Window Control";
CM_ SG_ 1125 CRC_IVI_DrWndw_Cntr "Cyclic Redundancy Check Profile 1c";
CM_ SG_ 1125 AlvCtr_IVI_DrWndw_Cntr "Alive Counter Profile 1c";
CM_ SG_ 1125 Pwd_DrvDoorUsrAgReq "Gwllwing Driver door Height Adjustment from IVI";
CM_ SG_ 1125 Pwd_PassDoorUsrAgReq "Gwllwing Passenger door Height Adjustment from IVI";
CM_ SG_ 1125 CenLock_AudioVisualCfg "IVI Configuration for Audio Visual Configuration";
CM_ SG_ 1125 PwrSdSt_LeExtndRtractReq "Power side step left extend/rectract request ny user via IVI";
CM_ SG_ 1125 PwrSdSt_RiExtndRtractReq "Power side step Right extend/rectract request ny user via IVI";
CM_ SG_ 1125 Pwind_WndwUpDwnUsrReq "Window Up/Down Request From voice command for all door window";
CM_ BO_ 1129 "Multi-Function Switches Switch Request";
CM_ SG_ 1129 CRC_MFS_SwitchReq "Cyclic Redundancy Check Profile 1c";
CM_ SG_ 1129 AlvCtr_MFS_SwitchReq "Alive Counter Profile 1c  ";
CM_ SG_ 1129 Mfsw_AdasScrlSwtReq "ADAS scroll switch press";
CM_ SG_ 1129 Mfsw_ScrolSwtReq "IVI scroll switch press ";
CM_ SG_ 1129 Mfsw_RimSwtWiperAcvnCmd "Wash/Wipe Switch (Rear Right)";
CM_ SG_ 1129 Mfsw_WiperMenuReq "Wiper mode menu on Driver Display";
CM_ SG_ 1129 Mfsw_PaddSwtFavoSelReq "Paddle Switch managing favourite option functions e.g. B+ increasing level of regen, B- decreasing level of braking B+ moving sunvisor in upper position, B- moving sunvisor in down position";
CM_ SG_ 1129 Mfsw_PaddSwtGearShiftReq "Paddle Switch managing favourite option functions e.g. B+ increasing level of regen, B- decreasing level of braking B+ moving sunvisor in upper position, B- moving sunvisor in down position";
CM_ SG_ 1129 Mfsw_AdasSwtReq "ADAS button on the MFS for display on IVI (center console display)/cluster (digital horizon display) of various ADAS options";
CM_ SG_ 1129 Mfsw_VoiceSwtReq "IVI Voice Activate Switch Press";
CM_ SG_ 1129 Mfsw_RimSwtHiBeamAcvnCmd "High Beam Switch Pressed (Rear Left)";
CM_ SG_ 1129 Mfsw_DrvModSwtReq "drive mode selection request";
CM_ SG_ 1129 Mfsw_ParkSwtReq "Paddle Switch Gear Shift Pressed";
CM_ SG_ 1129 Mfsw_FavoSwtReq "Favorite Switch Pressed";
BA_DEF_ BO_  "DiagConnection" INT 0 0;
BA_DEF_ BO_  "DiagFdOnly" ENUM  "Yes","No";
BA_DEF_ BO_  "DataID" HEX 0 0;
BA_DEF_ BO_  "E2EProfile" ENUM  "PROFILE_1C","PROFILE_5","Not Applicable","NOT_E2E_MSG";
BA_DEF_ BU_  "TpSTMin" INT 0 255;
BA_DEF_  "Version" STRING ;
BA_DEF_  "BusType" STRING ;
BA_DEF_  "DBName" STRING ;
BA_DEF_ SG_  "GenSigSendType" ENUM  "Cyclic","OnChange","Cyclic On Change","NoSigSendType";
BA_DEF_  "NmType" STRING ;
BA_DEF_  "NmAsrWaitBusSleepTime" INT 0 65535;
BA_DEF_ BO_  "VFrameFormat" ENUM  "StandardCAN","ExtendedCAN","reserved","reserved","reserved","reserved","reserved","reserved","reserved","reserved","reserved","reserved","reserved","reserved","StandardCAN_FD","ExtendedCAN_FD";
BA_DEF_ BU_  "ILUsed" ENUM  "No","Yes";
BA_DEF_  "NmAsrTimeoutTime" INT 0 65535;
BA_DEF_ BU_  "NmAsrNode" ENUM  "No","Yes";
BA_DEF_  "NmAsrRepeatMessageTime" INT 0 65535;
BA_DEF_ BO_  "NmAsrMessageCount" INT 1 256;
BA_DEF_ BU_  "NmAsrNodeIdentifier" HEX 0 255;
BA_DEF_  "NmAsrCanMsgCycleTime" INT 0 65535;
BA_DEF_ BU_  "NmStationAddress" HEX 0 0;
BA_DEF_  "NmAsrBaseAddress" HEX 0 2047;
BA_DEF_ BO_  "GenMsgSendType" ENUM  "Cyclic","OnChange","Cyclic On Change","NoMsgSendType";
BA_DEF_ SG_  "InvalidValue" STRING ;
BA_DEF_ BO_  "GenMsgCycleTime" INT 0 65535;
BA_DEF_ BO_  "GenMsgCycleTimeFast" INT 0 65535;
BA_DEF_ SG_  "GenSigTimeoutTime" INT 0 65535;
BA_DEF_ SG_  "GenSigStartValue" INT 0 0;
BA_DEF_ BO_  "GenMsgILSupport" ENUM  "No","Yes";
BA_DEF_ BO_  "GenMsgNrOfRepetition" INT 0 0;
BA_DEF_ BO_  "DiagState" ENUM  "No","Yes";
BA_DEF_ BO_  "DiagResponse" ENUM  "No","Yes";
BA_DEF_ BO_  "DiagRequest" ENUM  "No","Yes";
BA_DEF_  "Manufacturer" STRING ;
BA_DEF_  "Baudrate" INT 0 2000000;
BA_DEF_  "DataBaudrate" INT 0 2000000;
BA_DEF_DEF_  "DiagConnection" 0;
BA_DEF_DEF_  "DiagFdOnly" "Yes";
BA_DEF_DEF_  "DataID" 0;
BA_DEF_DEF_  "E2EProfile" "NOT_E2E_MSG";
BA_DEF_DEF_  "TpSTMin" 20;
BA_DEF_DEF_  "Version" "";
BA_DEF_DEF_  "BusType" "CAN";
BA_DEF_DEF_  "DBName" "";
BA_DEF_DEF_  "GenSigSendType" "Cyclic";
BA_DEF_DEF_  "NmType" "NmAsr";
BA_DEF_DEF_  "NmAsrWaitBusSleepTime" 1500;
BA_DEF_DEF_  "VFrameFormat" "StandardCAN";
BA_DEF_DEF_  "ILUsed" "Yes";
BA_DEF_DEF_  "NmAsrTimeoutTime" 2000;
BA_DEF_DEF_  "NmAsrNode" "No";
BA_DEF_DEF_  "NmAsrRepeatMessageTime" 3200;
BA_DEF_DEF_  "NmAsrMessageCount" 128;
BA_DEF_DEF_  "NmAsrNodeIdentifier" 0;
BA_DEF_DEF_  "NmAsrCanMsgCycleTime" 640;
BA_DEF_DEF_  "NmStationAddress" 0;
BA_DEF_DEF_  "NmAsrBaseAddress" 1280;
BA_DEF_DEF_  "GenMsgSendType" "Cyclic";
BA_DEF_DEF_  "InvalidValue" "";
BA_DEF_DEF_  "GenMsgCycleTime" 0;
BA_DEF_DEF_  "GenMsgCycleTimeFast" 0;
BA_DEF_DEF_  "GenSigTimeoutTime" 0;
BA_DEF_DEF_  "GenSigStartValue" 0;
BA_DEF_DEF_  "GenMsgILSupport" "Yes";
BA_DEF_DEF_  "GenMsgNrOfRepetition" 0;
BA_DEF_DEF_  "DiagState" "No";
BA_DEF_DEF_  "DiagResponse" "No";
BA_DEF_DEF_  "DiagRequest" "No";
BA_DEF_DEF_  "Manufacturer" "";
BA_DEF_DEF_  "Baudrate" 0;
BA_DEF_DEF_  "DataBaudrate" 0;
BA_ "Version" "02.01.01";
BA_ "Manufacturer" "CEER ";
BA_ "DataBaudrate" 2000000;
BA_ "BusType" "CAN FD";
BA_ "Baudrate" 500000;
BA_ "DBName" "I1_CAN_FD";
BA_ "NmStationAddress" BU_ IVI 2;
BA_ "NmAsrNodeIdentifier" BU_ IVI 2;
BA_ "NmAsrNode" BU_ IVI 1;
BA_ "NmStationAddress" BU_ ZCU_F 5;
BA_ "NmAsrNodeIdentifier" BU_ ZCU_F 5;
BA_ "NmAsrNode" BU_ ZCU_F 1;
BA_ "DiagResponse" BO_ 1663 1;
BA_ "GenMsgSendType" BO_ 1663 3;
BA_ "DiagConnection" BO_ 1663 11113;
BA_ "GenMsgILSupport" BO_ 1663 0;
BA_ "VFrameFormat" BO_ 1663 14;
BA_ "GenMsgCycleTime" BO_ 99 10;
BA_ "E2EProfile" BO_ 99 0;
BA_ "DataID" BO_ 99 3951;
BA_ "VFrameFormat" BO_ 99 14;
BA_ "GenMsgCycleTime" BO_ 102 10;
BA_ "E2EProfile" BO_ 102 0;
BA_ "DataID" BO_ 102 1000;
BA_ "VFrameFormat" BO_ 102 14;
BA_ "GenMsgCycleTime" BO_ 103 10;
BA_ "E2EProfile" BO_ 103 1;
BA_ "DataID" BO_ 103 3272;
BA_ "VFrameFormat" BO_ 103 14;
BA_ "GenMsgCycleTime" BO_ 118 10;
BA_ "E2EProfile" BO_ 118 1;
BA_ "DataID" BO_ 118 2319;
BA_ "VFrameFormat" BO_ 118 14;
BA_ "GenMsgCycleTime" BO_ 119 10;
BA_ "E2EProfile" BO_ 119 1;
BA_ "DataID" BO_ 119 1657;
BA_ "VFrameFormat" BO_ 119 14;
BA_ "GenMsgCycleTime" BO_ 128 10;
BA_ "E2EProfile" BO_ 128 1;
BA_ "DataID" BO_ 128 331;
BA_ "VFrameFormat" BO_ 128 14;
BA_ "GenMsgCycleTime" BO_ 160 20;
BA_ "E2EProfile" BO_ 160 0;
BA_ "DataID" BO_ 160 2215;
BA_ "VFrameFormat" BO_ 160 14;
BA_ "GenMsgCycleTime" BO_ 211 20;
BA_ "E2EProfile" BO_ 211 0;
BA_ "DataID" BO_ 211 3352;
BA_ "VFrameFormat" BO_ 211 14;
BA_ "GenMsgCycleTime" BO_ 223 20;
BA_ "E2EProfile" BO_ 223 1;
BA_ "DataID" BO_ 223 1517;
BA_ "VFrameFormat" BO_ 223 14;
BA_ "GenMsgCycleTime" BO_ 273 50;
BA_ "E2EProfile" BO_ 273 1;
BA_ "DataID" BO_ 273 3241;
BA_ "VFrameFormat" BO_ 273 14;
BA_ "GenMsgCycleTime" BO_ 279 50;
BA_ "E2EProfile" BO_ 279 1;
BA_ "DataID" BO_ 279 3509;
BA_ "VFrameFormat" BO_ 279 14;
BA_ "GenMsgCycleTime" BO_ 285 50;
BA_ "E2EProfile" BO_ 285 0;
BA_ "DataID" BO_ 285 762;
BA_ "VFrameFormat" BO_ 285 14;
BA_ "GenMsgCycleTime" BO_ 304 100;
BA_ "E2EProfile" BO_ 304 0;
BA_ "DataID" BO_ 304 2450;
BA_ "VFrameFormat" BO_ 304 14;
BA_ "GenMsgCycleTime" BO_ 313 100;
BA_ "E2EProfile" BO_ 313 1;
BA_ "DataID" BO_ 313 1223;
BA_ "VFrameFormat" BO_ 313 14;
BA_ "GenMsgCycleTime" BO_ 317 100;
BA_ "E2EProfile" BO_ 317 0;
BA_ "DataID" BO_ 317 735;
BA_ "VFrameFormat" BO_ 317 14;
BA_ "GenMsgCycleTime" BO_ 318 100;
BA_ "E2EProfile" BO_ 318 1;
BA_ "DataID" BO_ 318 1248;
BA_ "VFrameFormat" BO_ 318 14;
BA_ "GenMsgCycleTime" BO_ 327 100;
BA_ "VFrameFormat" BO_ 327 14;
BA_ "GenMsgCycleTime" BO_ 349 100;
BA_ "E2EProfile" BO_ 349 1;
BA_ "DataID" BO_ 349 2396;
BA_ "VFrameFormat" BO_ 349 14;
BA_ "GenMsgCycleTime" BO_ 367 100;
BA_ "E2EProfile" BO_ 367 0;
BA_ "DataID" BO_ 367 1660;
BA_ "VFrameFormat" BO_ 367 14;
BA_ "GenMsgCycleTime" BO_ 371 100;
BA_ "E2EProfile" BO_ 371 1;
BA_ "DataID" BO_ 371 3347;
BA_ "VFrameFormat" BO_ 371 14;
BA_ "GenMsgCycleTime" BO_ 377 100;
BA_ "E2EProfile" BO_ 377 1;
BA_ "DataID" BO_ 377 542;
BA_ "VFrameFormat" BO_ 377 14;
BA_ "GenMsgCycleTime" BO_ 383 100;
BA_ "E2EProfile" BO_ 383 1;
BA_ "DataID" BO_ 383 1563;
BA_ "VFrameFormat" BO_ 383 14;
BA_ "GenMsgCycleTime" BO_ 387 100;
BA_ "E2EProfile" BO_ 387 1;
BA_ "DataID" BO_ 387 2050;
BA_ "VFrameFormat" BO_ 387 14;
BA_ "GenMsgCycleTime" BO_ 393 100;
BA_ "E2EProfile" BO_ 393 1;
BA_ "DataID" BO_ 393 3625;
BA_ "VFrameFormat" BO_ 393 14;
BA_ "GenMsgCycleTime" BO_ 399 100;
BA_ "E2EProfile" BO_ 399 1;
BA_ "DataID" BO_ 399 3372;
BA_ "VFrameFormat" BO_ 399 14;
BA_ "GenMsgCycleTime" BO_ 403 100;
BA_ "E2EProfile" BO_ 403 1;
BA_ "DataID" BO_ 403 302;
BA_ "VFrameFormat" BO_ 403 14;
BA_ "GenMsgCycleTime" BO_ 409 100;
BA_ "E2EProfile" BO_ 409 1;
BA_ "DataID" BO_ 409 2578;
BA_ "VFrameFormat" BO_ 409 14;
BA_ "GenMsgCycleTime" BO_ 410 100;
BA_ "E2EProfile" BO_ 410 1;
BA_ "DataID" BO_ 410 259;
BA_ "VFrameFormat" BO_ 410 14;
BA_ "GenMsgCycleTime" BO_ 415 100;
BA_ "E2EProfile" BO_ 415 1;
BA_ "DataID" BO_ 415 2095;
BA_ "VFrameFormat" BO_ 415 14;
BA_ "GenMsgCycleTime" BO_ 419 100;
BA_ "E2EProfile" BO_ 419 0;
BA_ "DataID" BO_ 419 1400;
BA_ "VFrameFormat" BO_ 419 14;
BA_ "GenMsgCycleTime" BO_ 425 100;
BA_ "E2EProfile" BO_ 425 0;
BA_ "DataID" BO_ 425 1601;
BA_ "VFrameFormat" BO_ 425 14;
BA_ "GenMsgCycleTime" BO_ 431 100;
BA_ "E2EProfile" BO_ 431 0;
BA_ "DataID" BO_ 431 2510;
BA_ "VFrameFormat" BO_ 431 14;
BA_ "GenMsgCycleTime" BO_ 740 500;
BA_ "E2EProfile" BO_ 740 1;
BA_ "DataID" BO_ 740 3274;
BA_ "VFrameFormat" BO_ 740 14;
BA_ "GenMsgSendType" BO_ 869 2;
BA_ "GenMsgNrOfRepetition" BO_ 869 3;
BA_ "GenMsgCycleTimeFast" BO_ 869 50;
BA_ "GenMsgCycleTime" BO_ 869 500;
BA_ "VFrameFormat" BO_ 869 14;
BA_ "GenMsgSendType" BO_ 873 2;
BA_ "GenMsgNrOfRepetition" BO_ 873 2;
BA_ "GenMsgCycleTimeFast" BO_ 873 50;
BA_ "GenMsgCycleTime" BO_ 873 500;
BA_ "E2EProfile" BO_ 873 1;
BA_ "DataID" BO_ 873 612;
BA_ "VFrameFormat" BO_ 873 14;
BA_ "GenMsgCycleTime" BO_ 883 500;
BA_ "E2EProfile" BO_ 883 0;
BA_ "DataID" BO_ 883 952;
BA_ "VFrameFormat" BO_ 883 14;
BA_ "GenMsgSendType" BO_ 889 2;
BA_ "GenMsgNrOfRepetition" BO_ 889 1;
BA_ "GenMsgCycleTimeFast" BO_ 889 50;
BA_ "GenMsgCycleTime" BO_ 889 500;
BA_ "E2EProfile" BO_ 889 0;
BA_ "DataID" BO_ 889 1414;
BA_ "VFrameFormat" BO_ 889 14;
BA_ "GenMsgSendType" BO_ 895 2;
BA_ "GenMsgNrOfRepetition" BO_ 895 1;
BA_ "GenMsgCycleTimeFast" BO_ 895 50;
BA_ "GenMsgCycleTime" BO_ 895 500;
BA_ "E2EProfile" BO_ 895 0;
BA_ "DataID" BO_ 895 2000;
BA_ "VFrameFormat" BO_ 895 14;
BA_ "GenMsgSendType" BO_ 899 2;
BA_ "GenMsgNrOfRepetition" BO_ 899 1;
BA_ "GenMsgCycleTimeFast" BO_ 899 50;
BA_ "GenMsgCycleTime" BO_ 899 500;
BA_ "E2EProfile" BO_ 899 0;
BA_ "DataID" BO_ 899 2928;
BA_ "VFrameFormat" BO_ 899 14;
BA_ "GenMsgCycleTime" BO_ 911 500;
BA_ "E2EProfile" BO_ 911 0;
BA_ "DataID" BO_ 911 923;
BA_ "VFrameFormat" BO_ 911 14;
BA_ "GenMsgCycleTime" BO_ 915 500;
BA_ "E2EProfile" BO_ 915 0;
BA_ "DataID" BO_ 915 1842;
BA_ "VFrameFormat" BO_ 915 14;
BA_ "GenMsgCycleTime" BO_ 921 500;
BA_ "E2EProfile" BO_ 921 0;
BA_ "DataID" BO_ 921 1292;
BA_ "VFrameFormat" BO_ 921 14;
BA_ "GenMsgCycleTime" BO_ 927 500;
BA_ "E2EProfile" BO_ 927 0;
BA_ "DataID" BO_ 927 1712;
BA_ "VFrameFormat" BO_ 927 14;
BA_ "GenMsgCycleTime" BO_ 931 500;
BA_ "E2EProfile" BO_ 931 0;
BA_ "DataID" BO_ 931 3463;
BA_ "VFrameFormat" BO_ 931 14;
BA_ "GenMsgCycleTime" BO_ 937 500;
BA_ "E2EProfile" BO_ 937 0;
BA_ "DataID" BO_ 937 1374;
BA_ "VFrameFormat" BO_ 937 14;
BA_ "GenMsgSendType" BO_ 995 2;
BA_ "GenMsgNrOfRepetition" BO_ 995 1;
BA_ "GenMsgCycleTimeFast" BO_ 995 100;
BA_ "GenMsgCycleTime" BO_ 995 1000;
BA_ "E2EProfile" BO_ 995 0;
BA_ "DataID" BO_ 995 412;
BA_ "VFrameFormat" BO_ 995 14;
BA_ "GenMsgSendType" BO_ 997 1;
BA_ "GenMsgNrOfRepetition" BO_ 997 3;
BA_ "GenMsgCycleTimeFast" BO_ 997 20;
BA_ "VFrameFormat" BO_ 997 14;
BA_ "GenMsgCycleTime" BO_ 999 1000;
BA_ "E2EProfile" BO_ 999 1;
BA_ "DataID" BO_ 999 1958;
BA_ "VFrameFormat" BO_ 999 14;
BA_ "GenMsgSendType" BO_ 1001 2;
BA_ "GenMsgNrOfRepetition" BO_ 1001 1;
BA_ "GenMsgCycleTimeFast" BO_ 1001 100;
BA_ "GenMsgCycleTime" BO_ 1001 1000;
BA_ "E2EProfile" BO_ 1001 0;
BA_ "DataID" BO_ 1001 3202;
BA_ "VFrameFormat" BO_ 1001 14;
BA_ "GenMsgSendType" BO_ 1007 2;
BA_ "GenMsgNrOfRepetition" BO_ 1007 1;
BA_ "GenMsgCycleTimeFast" BO_ 1007 100;
BA_ "GenMsgCycleTime" BO_ 1007 1000;
BA_ "E2EProfile" BO_ 1007 0;
BA_ "DataID" BO_ 1007 1756;
BA_ "VFrameFormat" BO_ 1007 14;
BA_ "GenMsgSendType" BO_ 1011 2;
BA_ "GenMsgNrOfRepetition" BO_ 1011 1;
BA_ "GenMsgCycleTimeFast" BO_ 1011 100;
BA_ "GenMsgCycleTime" BO_ 1011 1000;
BA_ "E2EProfile" BO_ 1011 0;
BA_ "DataID" BO_ 1011 2022;
BA_ "VFrameFormat" BO_ 1011 14;
BA_ "GenMsgSendType" BO_ 1017 2;
BA_ "GenMsgNrOfRepetition" BO_ 1017 2;
BA_ "GenMsgCycleTimeFast" BO_ 1017 50;
BA_ "GenMsgCycleTime" BO_ 1017 1000;
BA_ "E2EProfile" BO_ 1017 1;
BA_ "DataID" BO_ 1017 3526;
BA_ "VFrameFormat" BO_ 1017 14;
BA_ "GenMsgCycleTime" BO_ 1023 1000;
BA_ "VFrameFormat" BO_ 1023 14;
BA_ "GenMsgSendType" BO_ 1027 2;
BA_ "GenMsgNrOfRepetition" BO_ 1027 2;
BA_ "GenMsgCycleTimeFast" BO_ 1027 100;
BA_ "GenMsgCycleTime" BO_ 1027 1000;
BA_ "E2EProfile" BO_ 1027 0;
BA_ "DataID" BO_ 1027 3037;
BA_ "VFrameFormat" BO_ 1027 14;
BA_ "GenMsgSendType" BO_ 1123 2;
BA_ "GenMsgNrOfRepetition" BO_ 1123 2;
BA_ "GenMsgCycleTimeFast" BO_ 1123 50;
BA_ "GenMsgCycleTime" BO_ 1123 1000;
BA_ "E2EProfile" BO_ 1123 0;
BA_ "DataID" BO_ 1123 737;
BA_ "VFrameFormat" BO_ 1123 14;
BA_ "GenMsgSendType" BO_ 1125 2;
BA_ "GenMsgNrOfRepetition" BO_ 1125 3;
BA_ "GenMsgCycleTimeFast" BO_ 1125 50;
BA_ "GenMsgCycleTime" BO_ 1125 1000;
BA_ "E2EProfile" BO_ 1125 0;
BA_ "DataID" BO_ 1125 1038;
BA_ "VFrameFormat" BO_ 1125 14;
BA_ "GenMsgSendType" BO_ 1129 2;
BA_ "GenMsgNrOfRepetition" BO_ 1129 2;
BA_ "GenMsgCycleTimeFast" BO_ 1129 50;
BA_ "GenMsgCycleTime" BO_ 1129 1000;
BA_ "E2EProfile" BO_ 1129 0;
BA_ "DataID" BO_ 1129 3426;
BA_ "VFrameFormat" BO_ 1129 14;
BA_ "GenSigSendType" SG_ 3221225472 IVI_SrcNodeID 3;
BA_ "GenSigSendType" SG_ 3221225472 IVI_CBV_ReptMsgBit_0 3;
BA_ "GenSigSendType" SG_ 3221225472 IVI_CBV_ResdBit_1 3;
BA_ "GenSigSendType" SG_ 3221225472 IVI_CBV_ResdBit_2 3;
BA_ "GenSigSendType" SG_ 3221225472 IVI_CBV_NMCoordBit_3 3;
BA_ "GenSigSendType" SG_ 3221225472 IVI_CBV_ActWakeBit_4 3;
BA_ "GenSigSendType" SG_ 3221225472 IVI_CBV_ResdBit_5 3;
BA_ "GenSigSendType" SG_ 3221225472 IVI_CBV_PNIBit_6 3;
BA_ "GenSigSendType" SG_ 3221225472 IVI_CBV_ResdBit_7 3;
BA_ "InvalidValue" SG_ 3221225472 IVI_UDB_0 "255";
BA_ "GenSigSendType" SG_ 3221225472 IVI_UDB_0 3;
BA_ "InvalidValue" SG_ 3221225472 IVI_UDB1_BStoRM_StBit_0 "1";
BA_ "GenSigSendType" SG_ 3221225472 IVI_UDB1_BStoRM_StBit_0 3;
BA_ "InvalidValue" SG_ 3221225472 IVI_UDB1_PBStoRM_StBit_1 "1";
BA_ "GenSigSendType" SG_ 3221225472 IVI_UDB1_PBStoRM_StBit_1 3;
BA_ "InvalidValue" SG_ 3221225472 IVI_UDB1_RMtoNO_StBit_2 "1";
BA_ "GenSigSendType" SG_ 3221225472 IVI_UDB1_RMtoNO_StBit_2 3;
BA_ "InvalidValue" SG_ 3221225472 IVI_UDB1_RStoNO_StBit_3 "1";
BA_ "GenSigSendType" SG_ 3221225472 IVI_UDB1_RStoNO_StBit_3 3;
BA_ "InvalidValue" SG_ 3221225472 IVI_UDB1_RStoRM_StBit_4 "1";
BA_ "GenSigSendType" SG_ 3221225472 IVI_UDB1_RStoRM_StBit_4 3;
BA_ "InvalidValue" SG_ 3221225472 IVI_UDB1_NOtoRM_StBit_5 "1";
BA_ "GenSigSendType" SG_ 3221225472 IVI_UDB1_NOtoRM_StBit_5 3;
BA_ "InvalidValue" SG_ 3221225472 IVI_UDB1_NO_StBit_6 "1";
BA_ "GenSigSendType" SG_ 3221225472 IVI_UDB1_NO_StBit_6 3;
BA_ "InvalidValue" SG_ 3221225472 IVI_UDB1_RM_StBit_7 "1";
BA_ "GenSigSendType" SG_ 3221225472 IVI_UDB1_RM_StBit_7 3;
BA_ "InvalidValue" SG_ 3221225472 IVI_UDB2_IGN_WUPBit_0 "1";
BA_ "GenSigSendType" SG_ 3221225472 IVI_UDB2_IGN_WUPBit_0 3;
BA_ "InvalidValue" SG_ 3221225472 IVI_UDB2_RESET_WUPBit_1 "1";
BA_ "GenSigSendType" SG_ 3221225472 IVI_UDB2_RESET_WUPBit_1 3;
BA_ "InvalidValue" SG_ 3221225472 IVI_UDB2_NM_WUPBit_2 "1";
BA_ "GenSigSendType" SG_ 3221225472 IVI_UDB2_NM_WUPBit_2 3;
BA_ "InvalidValue" SG_ 3221225472 IVI_UDB2_ECUSPEC_WUPBit_3 "1";
BA_ "GenSigSendType" SG_ 3221225472 IVI_UDB2_ECUSPEC_WUPBit_3 3;
BA_ "InvalidValue" SG_ 3221225472 IVI_UDB2_NM_AWAKEBit_4 "1";
BA_ "GenSigSendType" SG_ 3221225472 IVI_UDB2_NM_AWAKEBit_4 3;
BA_ "InvalidValue" SG_ 3221225472 IVI_UDB2_IGN_AWAKEBit_5 "1";
BA_ "GenSigSendType" SG_ 3221225472 IVI_UDB2_IGN_AWAKEBit_5 3;
BA_ "InvalidValue" SG_ 3221225472 IVI_UDB2_DIAG_AWAKEBit_6 "1";
BA_ "GenSigSendType" SG_ 3221225472 IVI_UDB2_DIAG_AWAKEBit_6 3;
BA_ "InvalidValue" SG_ 3221225472 IVI_UDB2_ECUSPEC_AWAKEBit_7 "1";
BA_ "GenSigSendType" SG_ 3221225472 IVI_UDB2_ECUSPEC_AWAKEBit_7 3;
BA_ "InvalidValue" SG_ 3221225472 IVI_UDB3_Bit_0 "1";
BA_ "GenSigSendType" SG_ 3221225472 IVI_UDB3_Bit_0 3;
BA_ "InvalidValue" SG_ 3221225472 IVI_UDB3_Bit_1 "1";
BA_ "GenSigSendType" SG_ 3221225472 IVI_UDB3_Bit_1 3;
BA_ "InvalidValue" SG_ 3221225472 IVI_UDB3_Bit_2 "1";
BA_ "GenSigSendType" SG_ 3221225472 IVI_UDB3_Bit_2 3;
BA_ "InvalidValue" SG_ 3221225472 IVI_UDB3_Bit_3 "1";
BA_ "GenSigSendType" SG_ 3221225472 IVI_UDB3_Bit_3 3;
BA_ "InvalidValue" SG_ 3221225472 IVI_UDB3_Bit_4 "1";
BA_ "GenSigSendType" SG_ 3221225472 IVI_UDB3_Bit_4 3;
BA_ "InvalidValue" SG_ 3221225472 IVI_UDB3_Bit_5 "1";
BA_ "GenSigSendType" SG_ 3221225472 IVI_UDB3_Bit_5 3;
BA_ "InvalidValue" SG_ 3221225472 IVI_UDB3_Bit_6 "1";
BA_ "GenSigSendType" SG_ 3221225472 IVI_UDB3_Bit_6 3;
BA_ "InvalidValue" SG_ 3221225472 IVI_UDB3_Bit_7 "1";
BA_ "GenSigSendType" SG_ 3221225472 IVI_UDB3_Bit_7 3;
BA_ "InvalidValue" SG_ 3221225472 IVI_UDB4_Bit_0 "1";
BA_ "GenSigSendType" SG_ 3221225472 IVI_UDB4_Bit_0 3;
BA_ "InvalidValue" SG_ 3221225472 IVI_UDB4_Bit_1 "1";
BA_ "GenSigSendType" SG_ 3221225472 IVI_UDB4_Bit_1 3;
BA_ "InvalidValue" SG_ 3221225472 IVI_UDB4_Bit_2 "1";
BA_ "GenSigSendType" SG_ 3221225472 IVI_UDB4_Bit_2 3;
BA_ "InvalidValue" SG_ 3221225472 IVI_UDB4_Bit_3 "1";
BA_ "GenSigSendType" SG_ 3221225472 IVI_UDB4_Bit_3 3;
BA_ "InvalidValue" SG_ 3221225472 IVI_UDB4_Bit_4 "1";
BA_ "GenSigSendType" SG_ 3221225472 IVI_UDB4_Bit_4 3;
BA_ "InvalidValue" SG_ 3221225472 IVI_UDB4_Bit_5 "1";
BA_ "GenSigSendType" SG_ 3221225472 IVI_UDB4_Bit_5 3;
BA_ "InvalidValue" SG_ 3221225472 IVI_UDB4_Bit_6 "1";
BA_ "GenSigSendType" SG_ 3221225472 IVI_UDB4_Bit_6 3;
BA_ "InvalidValue" SG_ 3221225472 IVI_UDB4_Bit_7 "1";
BA_ "GenSigSendType" SG_ 3221225472 IVI_UDB4_Bit_7 3;
BA_ "InvalidValue" SG_ 3221225472 IVI_UDB5_Bit_0 "1";
BA_ "GenSigSendType" SG_ 3221225472 IVI_UDB5_Bit_0 3;
BA_ "InvalidValue" SG_ 3221225472 IVI_UDB5_Bit_1 "1";
BA_ "GenSigSendType" SG_ 3221225472 IVI_UDB5_Bit_1 3;
BA_ "InvalidValue" SG_ 3221225472 IVI_UDB5_Bit_2 "1";
BA_ "GenSigSendType" SG_ 3221225472 IVI_UDB5_Bit_2 3;
BA_ "InvalidValue" SG_ 3221225472 IVI_UDB5_Bit_3 "1";
BA_ "GenSigSendType" SG_ 3221225472 IVI_UDB5_Bit_3 3;
BA_ "InvalidValue" SG_ 3221225472 IVI_UDB5_Bit_4 "1";
BA_ "GenSigSendType" SG_ 3221225472 IVI_UDB5_Bit_4 3;
BA_ "InvalidValue" SG_ 3221225472 IVI_UDB5_Bit_5 "1";
BA_ "GenSigSendType" SG_ 3221225472 IVI_UDB5_Bit_5 3;
BA_ "InvalidValue" SG_ 3221225472 IVI_UDB5_Bit_6 "1";
BA_ "GenSigSendType" SG_ 3221225472 IVI_UDB5_Bit_6 3;
BA_ "InvalidValue" SG_ 3221225472 IVI_UDB5_Bit_7 "1";
BA_ "GenSigSendType" SG_ 3221225472 IVI_UDB5_Bit_7 3;
BA_ "GenSigSendType" SG_ 3221225472 ZCUF_SrcNodeID 3;
BA_ "GenSigSendType" SG_ 3221225472 ZCUF_CBV_ReptMsgBit_0 3;
BA_ "GenSigSendType" SG_ 3221225472 ZCUF_CBV_ResdBit_1 3;
BA_ "GenSigSendType" SG_ 3221225472 ZCUF_CBV_ResdBit_2 3;
BA_ "GenSigSendType" SG_ 3221225472 ZCUF_CBV_NMCoordBit_3 3;
BA_ "GenSigSendType" SG_ 3221225472 ZCUF_CBV_ActWakeBit_4 3;
BA_ "GenSigSendType" SG_ 3221225472 ZCUF_CBV_ResdBit_5 3;
BA_ "GenSigSendType" SG_ 3221225472 ZCUF_CBV_PNIBit_6 3;
BA_ "GenSigSendType" SG_ 3221225472 ZCUF_CBV_ResdBit_7 3;
BA_ "InvalidValue" SG_ 3221225472 ZCUF_UDB_0 "255";
BA_ "GenSigSendType" SG_ 3221225472 ZCUF_UDB_0 3;
BA_ "InvalidValue" SG_ 3221225472 ZCUF_UDB1_BStoRM_StBit_0 "1";
BA_ "GenSigSendType" SG_ 3221225472 ZCUF_UDB1_BStoRM_StBit_0 3;
BA_ "InvalidValue" SG_ 3221225472 ZCUF_UDB1_PBStoRM_StBit1 "1";
BA_ "GenSigSendType" SG_ 3221225472 ZCUF_UDB1_PBStoRM_StBit1 3;
BA_ "InvalidValue" SG_ 3221225472 ZCUF_UDB1_RMtoNO_StBit_2 "1";
BA_ "GenSigSendType" SG_ 3221225472 ZCUF_UDB1_RMtoNO_StBit_2 3;
BA_ "InvalidValue" SG_ 3221225472 ZCUF_UDB1_RStoNO_StBit_3 "1";
BA_ "GenSigSendType" SG_ 3221225472 ZCUF_UDB1_RStoNO_StBit_3 3;
BA_ "InvalidValue" SG_ 3221225472 ZCUF_UDB1_RStoRM_StBit_4 "1";
BA_ "GenSigSendType" SG_ 3221225472 ZCUF_UDB1_RStoRM_StBit_4 3;
BA_ "InvalidValue" SG_ 3221225472 ZCUF_UDB1_NOtoRM_StBit_5 "1";
BA_ "GenSigSendType" SG_ 3221225472 ZCUF_UDB1_NOtoRM_StBit_5 3;
BA_ "InvalidValue" SG_ 3221225472 ZCUF_UDB1_NO_StBit_6 "1";
BA_ "GenSigSendType" SG_ 3221225472 ZCUF_UDB1_NO_StBit_6 3;
BA_ "InvalidValue" SG_ 3221225472 ZCUF_UDB1_RM_StBit_7 "1";
BA_ "GenSigSendType" SG_ 3221225472 ZCUF_UDB1_RM_StBit_7 3;
BA_ "InvalidValue" SG_ 3221225472 ZCUF_UDB2_IGN_WUPBit_0 "1";
BA_ "GenSigSendType" SG_ 3221225472 ZCUF_UDB2_IGN_WUPBit_0 3;
BA_ "InvalidValue" SG_ 3221225472 ZCUF_UDB2_RESET_WUPBit_1 "1";
BA_ "GenSigSendType" SG_ 3221225472 ZCUF_UDB2_RESET_WUPBit_1 3;
BA_ "InvalidValue" SG_ 3221225472 ZCUF_UDB2_NM_WUPBit_2 "1";
BA_ "GenSigSendType" SG_ 3221225472 ZCUF_UDB2_NM_WUPBit_2 3;
BA_ "InvalidValue" SG_ 3221225472 ZCUF_UDB2_ECUSPEC_WUPBit_3 "1";
BA_ "GenSigSendType" SG_ 3221225472 ZCUF_UDB2_ECUSPEC_WUPBit_3 3;
BA_ "InvalidValue" SG_ 3221225472 ZCUF_UDB2_NM_AWAKEBit_4 "1";
BA_ "GenSigSendType" SG_ 3221225472 ZCUF_UDB2_NM_AWAKEBit_4 3;
BA_ "InvalidValue" SG_ 3221225472 ZCUF_UDB2_IGN_AWAKEBit_5 "1";
BA_ "GenSigSendType" SG_ 3221225472 ZCUF_UDB2_IGN_AWAKEBit_5 3;
BA_ "InvalidValue" SG_ 3221225472 ZCUF_UDB2_DIAG_AWAKEBit_6 "1";
BA_ "GenSigSendType" SG_ 3221225472 ZCUF_UDB2_DIAG_AWAKEBit_6 3;
BA_ "InvalidValue" SG_ 3221225472 ZCUF_UDB2_ECUSPEC_AWKEBit7 "1";
BA_ "GenSigSendType" SG_ 3221225472 ZCUF_UDB2_ECUSPEC_AWKEBit7 3;
BA_ "InvalidValue" SG_ 3221225472 ZCUF_UDB3_Bit_0 "1";
BA_ "GenSigSendType" SG_ 3221225472 ZCUF_UDB3_Bit_0 3;
BA_ "InvalidValue" SG_ 3221225472 ZCUF_UDB3_Bit_1 "1";
BA_ "GenSigSendType" SG_ 3221225472 ZCUF_UDB3_Bit_1 3;
BA_ "InvalidValue" SG_ 3221225472 ZCUF_UDB3_Bit_2 "1";
BA_ "GenSigSendType" SG_ 3221225472 ZCUF_UDB3_Bit_2 3;
BA_ "InvalidValue" SG_ 3221225472 ZCUF_UDB3_Bit_3 "1";
BA_ "GenSigSendType" SG_ 3221225472 ZCUF_UDB3_Bit_3 3;
BA_ "InvalidValue" SG_ 3221225472 ZCUF_UDB3_Bit_4 "1";
BA_ "GenSigSendType" SG_ 3221225472 ZCUF_UDB3_Bit_4 3;
BA_ "InvalidValue" SG_ 3221225472 ZCUF_UDB3_Bit_5 "1";
BA_ "GenSigSendType" SG_ 3221225472 ZCUF_UDB3_Bit_5 3;
BA_ "InvalidValue" SG_ 3221225472 ZCUF_UDB3_Bit_6 "1";
BA_ "GenSigSendType" SG_ 3221225472 ZCUF_UDB3_Bit_6 3;
BA_ "InvalidValue" SG_ 3221225472 ZCUF_UDB3_Bit_7 "1";
BA_ "GenSigSendType" SG_ 3221225472 ZCUF_UDB3_Bit_7 3;
BA_ "InvalidValue" SG_ 3221225472 ZCUF_UDB4_Bit_0 "1";
BA_ "GenSigSendType" SG_ 3221225472 ZCUF_UDB4_Bit_0 3;
BA_ "InvalidValue" SG_ 3221225472 ZCUF_UDB4_Bit_1 "1";
BA_ "GenSigSendType" SG_ 3221225472 ZCUF_UDB4_Bit_1 3;
BA_ "InvalidValue" SG_ 3221225472 ZCUF_UDB4_Bit_2 "1";
BA_ "GenSigSendType" SG_ 3221225472 ZCUF_UDB4_Bit_2 3;
BA_ "InvalidValue" SG_ 3221225472 ZCUF_UDB4_Bit_3 "1";
BA_ "GenSigSendType" SG_ 3221225472 ZCUF_UDB4_Bit_3 3;
BA_ "InvalidValue" SG_ 3221225472 ZCUF_UDB4_Bit_4 "1";
BA_ "GenSigSendType" SG_ 3221225472 ZCUF_UDB4_Bit_4 3;
BA_ "InvalidValue" SG_ 3221225472 ZCUF_UDB4_Bit_5 "1";
BA_ "GenSigSendType" SG_ 3221225472 ZCUF_UDB4_Bit_5 3;
BA_ "InvalidValue" SG_ 3221225472 ZCUF_UDB4_Bit_6 "1";
BA_ "GenSigSendType" SG_ 3221225472 ZCUF_UDB4_Bit_6 3;
BA_ "InvalidValue" SG_ 3221225472 ZCUF_UDB4_Bit_7 "1";
BA_ "GenSigSendType" SG_ 3221225472 ZCUF_UDB4_Bit_7 3;
BA_ "InvalidValue" SG_ 3221225472 ZCUF_UDB5_Bit_0 "1";
BA_ "GenSigSendType" SG_ 3221225472 ZCUF_UDB5_Bit_0 3;
BA_ "InvalidValue" SG_ 3221225472 ZCUF_UDB5_Bit_1 "1";
BA_ "GenSigSendType" SG_ 3221225472 ZCUF_UDB5_Bit_1 3;
BA_ "InvalidValue" SG_ 3221225472 ZCUF_UDB5_Bit_2 "1";
BA_ "GenSigSendType" SG_ 3221225472 ZCUF_UDB5_Bit_2 3;
BA_ "InvalidValue" SG_ 3221225472 ZCUF_UDB5_Bit_3 "1";
BA_ "GenSigSendType" SG_ 3221225472 ZCUF_UDB5_Bit_3 3;
BA_ "InvalidValue" SG_ 3221225472 ZCUF_UDB5_Bit_4 "1";
BA_ "GenSigSendType" SG_ 3221225472 ZCUF_UDB5_Bit_4 3;
BA_ "InvalidValue" SG_ 3221225472 ZCUF_UDB5_Bit_5 "1";
BA_ "GenSigSendType" SG_ 3221225472 ZCUF_UDB5_Bit_5 3;
BA_ "InvalidValue" SG_ 3221225472 ZCUF_UDB5_Bit_6 "1";
BA_ "GenSigSendType" SG_ 3221225472 ZCUF_UDB5_Bit_6 3;
BA_ "InvalidValue" SG_ 3221225472 ZCUF_UDB5_Bit_7 "1";
BA_ "GenSigSendType" SG_ 3221225472 ZCUF_UDB5_Bit_7 3;
BA_ "GenSigSendType" SG_ 1663 OBD_FuncDiagResp_Byte0 3;
BA_ "GenSigSendType" SG_ 1663 OBD_FuncDiagResp_Byte1 3;
BA_ "GenSigSendType" SG_ 1663 OBD_FuncDiagResp_Byte2 3;
BA_ "GenSigSendType" SG_ 1663 OBD_FuncDiagResp_Byte3 3;
BA_ "GenSigSendType" SG_ 1663 OBD_FuncDiagResp_Byte4 3;
BA_ "GenSigSendType" SG_ 1663 OBD_FuncDiagResp_Byte5 3;
BA_ "GenSigSendType" SG_ 1663 OBD_FuncDiagResp_Byte6 3;
BA_ "GenSigSendType" SG_ 1663 OBD_FuncDiagResp_Byte7 3;
BA_ "GenSigTimeoutTime" SG_ 99 CRC_ACM_CrashStat 50;
BA_ "GenSigStartValue" SG_ 99 CRC_ACM_CrashStat 255;
BA_ "InvalidValue" SG_ 99 AlvCtr_ACM_CrashStat "15";
BA_ "GenSigTimeoutTime" SG_ 99 AlvCtr_ACM_CrashStat 50;
BA_ "GenSigStartValue" SG_ 99 AlvCtr_ACM_CrashStat 15;
BA_ "InvalidValue" SG_ 99 Airbg_CrashSts "3";
BA_ "GenSigTimeoutTime" SG_ 99 Airbg_CrashSts 50;
BA_ "GenSigTimeoutTime" SG_ 102 CRC_EPS_SFA_SteerWhl_Pub_Info 50;
BA_ "InvalidValue" SG_ 102 AlvCtr_EPS_SFA_SteerWhl_Pub_Info "15";
BA_ "GenSigTimeoutTime" SG_ 102 AlvCtr_EPS_SFA_SteerWhl_Pub_Info 50;
BA_ "GenSigStartValue" SG_ 102 AlvCtr_EPS_SFA_SteerWhl_Pub_Info 15;
BA_ "InvalidValue" SG_ 102 Stbwr_SfaSteerWhlTq "4095";
BA_ "GenSigTimeoutTime" SG_ 102 Stbwr_SfaSteerWhlTq 50;
BA_ "GenSigStartValue" SG_ 102 Stbwr_SfaSteerWhlTq 2000;
BA_ "InvalidValue" SG_ 102 Stbwr_SfaEmgcyReq "3";
BA_ "GenSigTimeoutTime" SG_ 102 Stbwr_SfaEmgcyReq 50;
BA_ "GenSigStartValue" SG_ 102 Stbwr_SfaEmgcyReq 3;
BA_ "InvalidValue" SG_ 102 Stbwr_SfaSteerWhlAg "65535";
BA_ "GenSigTimeoutTime" SG_ 102 Stbwr_SfaSteerWhlAg 50;
BA_ "InvalidValue" SG_ 102 Stbwr_TunSts "7";
BA_ "GenSigTimeoutTime" SG_ 102 Stbwr_TunSts 50;
BA_ "GenSigStartValue" SG_ 102 Stbwr_TunSts 7;
BA_ "InvalidValue" SG_ 102 Stbwr_CentrgSts "7";
BA_ "GenSigTimeoutTime" SG_ 102 Stbwr_CentrgSts 50;
BA_ "GenSigStartValue" SG_ 102 Stbwr_CentrgSts 7;
BA_ "InvalidValue" SG_ 102 Stbwr_SfaCtlMode "15";
BA_ "GenSigTimeoutTime" SG_ 102 Stbwr_SfaCtlMode 50;
BA_ "GenSigStartValue" SG_ 102 Stbwr_SfaCtlMode 15;
BA_ "GenSigTimeoutTime" SG_ 103 CRC_VCU_ETractSys_Info 50;
BA_ "GenSigStartValue" SG_ 103 CRC_VCU_ETractSys_Info 65535;
BA_ "GenSigTimeoutTime" SG_ 103 AlvCtr_VCU_ETractSys_Info 50;
BA_ "GenSigStartValue" SG_ 103 AlvCtr_VCU_ETractSys_Info 255;
BA_ "InvalidValue" SG_ 103 Dtqmt_TgtTqEdsRe "4095";
BA_ "GenSigTimeoutTime" SG_ 103 Dtqmt_TgtTqEdsRe 50;
BA_ "GenSigStartValue" SG_ 103 Dtqmt_TgtTqEdsRe 4095;
BA_ "InvalidValue" SG_ 103 Dtqmt_TgtTqEdsFrnt "4095";
BA_ "GenSigTimeoutTime" SG_ 103 Dtqmt_TgtTqEdsFrnt 50;
BA_ "GenSigStartValue" SG_ 103 Dtqmt_TgtTqEdsFrnt 4095;
BA_ "GenSigTimeoutTime" SG_ 118 CRC_RWSM_Info 50;
BA_ "GenSigStartValue" SG_ 118 CRC_RWSM_Info 65535;
BA_ "GenSigTimeoutTime" SG_ 118 AlvCtr_RWSM_Info 50;
BA_ "GenSigStartValue" SG_ 118 AlvCtr_RWSM_Info 255;
BA_ "InvalidValue" SG_ 118 ReWhlSteer_MeasdStkVal "65535";
BA_ "GenSigTimeoutTime" SG_ 118 ReWhlSteer_MeasdStkVal 50;
BA_ "GenSigStartValue" SG_ 118 ReWhlSteer_MeasdStkVal 32767;
BA_ "InvalidValue" SG_ 118 ReWhlSteer_Sts "3";
BA_ "GenSigTimeoutTime" SG_ 118 ReWhlSteer_Sts 50;
BA_ "GenSigStartValue" SG_ 118 ReWhlSteer_Sts 3;
BA_ "GenSigTimeoutTime" SG_ 119 CRC_BMS_Sts 50;
BA_ "GenSigStartValue" SG_ 119 CRC_BMS_Sts 65535;
BA_ "GenSigTimeoutTime" SG_ 119 AlvCtr_BMS_Sts 50;
BA_ "GenSigStartValue" SG_ 119 AlvCtr_BMS_Sts 255;
BA_ "InvalidValue" SG_ 119 Bms_BatPreCdnSts "3";
BA_ "GenSigTimeoutTime" SG_ 119 Bms_BatPreCdnSts 50;
BA_ "GenSigTimeoutTime" SG_ 128 CRC_EPS_RWA_Pinion_Pub_Info 50;
BA_ "GenSigTimeoutTime" SG_ 128 AlvCtr_EPS_RWA_Pinion_Pub_Info 50;
BA_ "InvalidValue" SG_ 128 Stbwr_RwaPinionAg "65535";
BA_ "GenSigTimeoutTime" SG_ 128 Stbwr_RwaPinionAg 50;
BA_ "GenSigStartValue" SG_ 128 Stbwr_RwaPinionAg 65535;
BA_ "InvalidValue" SG_ 128 Stbwr_RwaPinionAgSpd "65535";
BA_ "GenSigTimeoutTime" SG_ 128 Stbwr_RwaPinionAgSpd 50;
BA_ "InvalidValue" SG_ 128 Stbwr_RwaRackPosn "1048575";
BA_ "GenSigTimeoutTime" SG_ 128 Stbwr_RwaRackPosn 50;
BA_ "GenSigStartValue" SG_ 128 Stbwr_RwaRackPosn 524000;
BA_ "InvalidValue" SG_ 128 Stbwr_RwaRackSpd "1048575";
BA_ "GenSigTimeoutTime" SG_ 128 Stbwr_RwaRackSpd 50;
BA_ "GenSigStartValue" SG_ 128 Stbwr_RwaRackSpd 524000;
BA_ "GenSigTimeoutTime" SG_ 160 CRC_EBCM_Veh_Info 100;
BA_ "GenSigStartValue" SG_ 160 CRC_EBCM_Veh_Info 255;
BA_ "InvalidValue" SG_ 160 AlvCtr_EBCM_Veh_Info "15";
BA_ "GenSigTimeoutTime" SG_ 160 AlvCtr_EBCM_Veh_Info 100;
BA_ "GenSigStartValue" SG_ 160 AlvCtr_EBCM_Veh_Info 15;
BA_ "InvalidValue" SG_ 160 Abs_ActVehSpd "65535";
BA_ "GenSigTimeoutTime" SG_ 160 Abs_ActVehSpd 100;
BA_ "GenSigTimeoutTime" SG_ 211 CRC_ZCUF_Clamp_Info 100;
BA_ "GenSigStartValue" SG_ 211 CRC_ZCUF_Clamp_Info 255;
BA_ "InvalidValue" SG_ 211 AlvCtr_ZCUF_Clamp_Info "15";
BA_ "GenSigTimeoutTime" SG_ 211 AlvCtr_ZCUF_Clamp_Info 100;
BA_ "GenSigStartValue" SG_ 211 AlvCtr_ZCUF_Clamp_Info 15;
BA_ "InvalidValue" SG_ 211 Clmmg_VehSt "15";
BA_ "GenSigTimeoutTime" SG_ 211 Clmmg_VehSt 100;
BA_ "GenSigStartValue" SG_ 211 Clmmg_VehSt 15;
BA_ "InvalidValue" SG_ 211 Clmmg_CL15_L "3";
BA_ "GenSigTimeoutTime" SG_ 211 Clmmg_CL15_L 100;
BA_ "GenSigStartValue" SG_ 211 Clmmg_CL15_L 3;
BA_ "InvalidValue" SG_ 211 Clmmg_CL30S_L "3";
BA_ "GenSigTimeoutTime" SG_ 211 Clmmg_CL30S_L 100;
BA_ "GenSigStartValue" SG_ 211 Clmmg_CL30S_L 3;
BA_ "InvalidValue" SG_ 211 Lvm_LoaShedReq "3";
BA_ "GenSigTimeoutTime" SG_ 211 Lvm_LoaShedReq 100;
BA_ "GenSigStartValue" SG_ 211 Lvm_LoaShedReq 3;
BA_ "GenSigTimeoutTime" SG_ 223 CRC_ASU_SnsrInfo 100;
BA_ "GenSigStartValue" SG_ 223 CRC_ASU_SnsrInfo 65535;
BA_ "GenSigTimeoutTime" SG_ 223 AlvCtr_ASU_SnsrInfo 100;
BA_ "GenSigStartValue" SG_ 223 AlvCtr_ASU_SnsrInfo 255;
BA_ "InvalidValue" SG_ 223 AirSuspUnit_HeiFL "4095";
BA_ "GenSigTimeoutTime" SG_ 223 AirSuspUnit_HeiFL 100;
BA_ "GenSigStartValue" SG_ 223 AirSuspUnit_HeiFL 4095;
BA_ "InvalidValue" SG_ 223 AirSuspUnit_HeiFR "4095";
BA_ "GenSigTimeoutTime" SG_ 223 AirSuspUnit_HeiFR 100;
BA_ "GenSigStartValue" SG_ 223 AirSuspUnit_HeiFR 4095;
BA_ "InvalidValue" SG_ 223 AirSuspUnit_HeiRR "4095";
BA_ "GenSigTimeoutTime" SG_ 223 AirSuspUnit_HeiRR 100;
BA_ "GenSigStartValue" SG_ 223 AirSuspUnit_HeiRR 4095;
BA_ "InvalidValue" SG_ 223 AirSuspUnit_HeiRL "4095";
BA_ "GenSigTimeoutTime" SG_ 223 AirSuspUnit_HeiRL 100;
BA_ "GenSigStartValue" SG_ 223 AirSuspUnit_HeiRL 4095;
BA_ "InvalidValue" SG_ 223 AirSuspUnit_HeiSts "7";
BA_ "GenSigTimeoutTime" SG_ 223 AirSuspUnit_HeiSts 100;
BA_ "InvalidValue" SG_ 223 AirSuspUnit_CdcModeSts "7";
BA_ "GenSigTimeoutTime" SG_ 223 AirSuspUnit_CdcModeSts 100;
BA_ "GenSigStartValue" SG_ 223 AirSuspUnit_CdcModeSts 7;
BA_ "InvalidValue" SG_ 223 AirSuspUnit_IngrsModAck "3";
BA_ "GenSigTimeoutTime" SG_ 223 AirSuspUnit_IngrsModAck 100;
BA_ "InvalidValue" SG_ 223 AirSuspUnit_SprgModeSts "7";
BA_ "GenSigTimeoutTime" SG_ 223 AirSuspUnit_SprgModeSts 100;
BA_ "InvalidValue" SG_ 223 AirSuspUnit_CmprSts "7";
BA_ "GenSigTimeoutTime" SG_ 223 AirSuspUnit_CmprSts 100;
BA_ "GenSigStartValue" SG_ 223 AirSuspUnit_CmprSts 7;
BA_ "InvalidValue" SG_ 223 AirSuspUnit_SrvModeSts "3";
BA_ "GenSigTimeoutTime" SG_ 223 AirSuspUnit_SrvModeSts 100;
BA_ "InvalidValue" SG_ 223 AirSuspUnit_AirTankP "255";
BA_ "GenSigTimeoutTime" SG_ 223 AirSuspUnit_AirTankP 100;
BA_ "GenSigStartValue" SG_ 223 AirSuspUnit_AirTankP 255;
BA_ "InvalidValue" SG_ 223 AirSuspUnit_Sts "7";
BA_ "GenSigTimeoutTime" SG_ 223 AirSuspUnit_Sts 100;
BA_ "GenSigTimeoutTime" SG_ 273 CRC_VCU_Batt_Info 250;
BA_ "GenSigStartValue" SG_ 273 CRC_VCU_Batt_Info 65535;
BA_ "GenSigTimeoutTime" SG_ 273 AlvCtr_VCU_Batt_Info 250;
BA_ "GenSigStartValue" SG_ 273 AlvCtr_VCU_Batt_Info 255;
BA_ "InvalidValue" SG_ 273 Bms_PackI "65535";
BA_ "GenSigTimeoutTime" SG_ 273 Bms_PackI 250;
BA_ "GenSigStartValue" SG_ 273 Bms_PackI 15000;
BA_ "InvalidValue" SG_ 273 Bms_PackU "65535";
BA_ "GenSigTimeoutTime" SG_ 273 Bms_PackU 250;
BA_ "GenSigStartValue" SG_ 273 Bms_PackU 3450;
BA_ "InvalidValue" SG_ 273 Acchg_RmngChgTi "4095";
BA_ "GenSigTimeoutTime" SG_ 273 Acchg_RmngChgTi 250;
BA_ "InvalidValue" SG_ 273 Fschg_RmngChgTi "4095";
BA_ "GenSigTimeoutTime" SG_ 273 Fschg_RmngChgTi 250;
BA_ "GenSigTimeoutTime" SG_ 279 CRC_VCU_Charging_Info 250;
BA_ "GenSigStartValue" SG_ 279 CRC_VCU_Charging_Info 65535;
BA_ "GenSigTimeoutTime" SG_ 279 AlvCtr_VCU_Charging_Info 250;
BA_ "GenSigStartValue" SG_ 279 AlvCtr_VCU_Charging_Info 255;
BA_ "InvalidValue" SG_ 279 Fschg_DcChgGunIn "3";
BA_ "GenSigTimeoutTime" SG_ 279 Fschg_DcChgGunIn 250;
BA_ "InvalidValue" SG_ 279 Acchg_AcChgGunIn "3";
BA_ "GenSigTimeoutTime" SG_ 279 Acchg_AcChgGunIn 250;
BA_ "GenSigTimeoutTime" SG_ 285 CRC_VCU_HVDrvSys_Status 250;
BA_ "GenSigStartValue" SG_ 285 CRC_VCU_HVDrvSys_Status 255;
BA_ "InvalidValue" SG_ 285 AlvCtr_VCU_HVDrvSys_Status "15";
BA_ "GenSigTimeoutTime" SG_ 285 AlvCtr_VCU_HVDrvSys_Status 250;
BA_ "GenSigStartValue" SG_ 285 AlvCtr_VCU_HVDrvSys_Status 15;
BA_ "InvalidValue" SG_ 285 Drvmc_ActDrvMode "7";
BA_ "GenSigTimeoutTime" SG_ 285 Drvmc_ActDrvMode 250;
BA_ "InvalidValue" SG_ 285 Enmgt_HvDrvSysSts "7";
BA_ "GenSigTimeoutTime" SG_ 285 Enmgt_HvDrvSysSts 250;
BA_ "InvalidValue" SG_ 285 Drvmc_ActDrvModeVld "3";
BA_ "GenSigTimeoutTime" SG_ 285 Drvmc_ActDrvModeVld 250;
BA_ "InvalidValue" SG_ 285 Eshift_ActGear "7";
BA_ "GenSigTimeoutTime" SG_ 285 Eshift_ActGear 250;
BA_ "GenSigStartValue" SG_ 285 Eshift_ActGear 7;
BA_ "GenSigTimeoutTime" SG_ 304 CRC_EBCM_Sts_Req 500;
BA_ "GenSigStartValue" SG_ 304 CRC_EBCM_Sts_Req 255;
BA_ "InvalidValue" SG_ 304 AlvCtr_EBCM_Sts_Req "15";
BA_ "GenSigTimeoutTime" SG_ 304 AlvCtr_EBCM_Sts_Req 500;
BA_ "GenSigStartValue" SG_ 304 AlvCtr_EBCM_Sts_Req 15;
BA_ "InvalidValue" SG_ 304 Abs_IntvSts "3";
BA_ "GenSigTimeoutTime" SG_ 304 Abs_IntvSts 500;
BA_ "GenSigStartValue" SG_ 304 Abs_IntvSts 3;
BA_ "InvalidValue" SG_ 304 Drvac_TcsAvl "3";
BA_ "GenSigTimeoutTime" SG_ 304 Drvac_TcsAvl 500;
BA_ "InvalidValue" SG_ 304 Drvac_FldLvlIndcrBrkFldSts "3";
BA_ "GenSigTimeoutTime" SG_ 304 Drvac_FldLvlIndcrBrkFldSts 500;
BA_ "InvalidValue" SG_ 304 Ecpbk_BrkLiOnReq "3";
BA_ "GenSigTimeoutTime" SG_ 304 Ecpbk_BrkLiOnReq 500;
BA_ "InvalidValue" SG_ 304 Ebd_SysSts "3";
BA_ "GenSigTimeoutTime" SG_ 304 Ebd_SysSts 500;
BA_ "GenSigStartValue" SG_ 304 Ebd_SysSts 3;
BA_ "InvalidValue" SG_ 304 Drvac_HdcSts "3";
BA_ "GenSigTimeoutTime" SG_ 304 Drvac_HdcSts 500;
BA_ "InvalidValue" SG_ 304 Drvac_TcsSts "3";
BA_ "GenSigTimeoutTime" SG_ 304 Drvac_TcsSts 500;
BA_ "InvalidValue" SG_ 304 Drvac_CorneringBrkCtlSts "3";
BA_ "GenSigTimeoutTime" SG_ 304 Drvac_CorneringBrkCtlSts 500;
BA_ "InvalidValue" SG_ 304 Drvac_HillStrtAssiSts "3";
BA_ "GenSigTimeoutTime" SG_ 304 Drvac_HillStrtAssiSts 500;
BA_ "InvalidValue" SG_ 304 Ecpbk_Sts "7";
BA_ "GenSigTimeoutTime" SG_ 304 Ecpbk_Sts 500;
BA_ "GenSigStartValue" SG_ 304 Ecpbk_Sts 7;
BA_ "GenSigTimeoutTime" SG_ 313 CRC_ZCUR_LampCmd 500;
BA_ "GenSigTimeoutTime" SG_ 313 AlvCtr_ZCUR_LampCmd 500;
BA_ "GenSigStartValue" SG_ 313 AlvCtr_ZCUR_LampCmd 255;
BA_ "GenSigTimeoutTime" SG_ 317 CRC_SBM_LVBatInfo_1 500;
BA_ "GenSigStartValue" SG_ 317 CRC_SBM_LVBatInfo_1 255;
BA_ "InvalidValue" SG_ 317 AlvCtr_SBM_LVBatInfo_1 "15";
BA_ "GenSigTimeoutTime" SG_ 317 AlvCtr_SBM_LVBatInfo_1 500;
BA_ "GenSigStartValue" SG_ 317 AlvCtr_SBM_LVBatInfo_1 15;
BA_ "InvalidValue" SG_ 317 Sbm_LVBattV "65535";
BA_ "GenSigTimeoutTime" SG_ 317 Sbm_LVBattV 500;
BA_ "InvalidValue" SG_ 317 Sbm_LvBatThermRunawy "3";
BA_ "GenSigTimeoutTime" SG_ 317 Sbm_LvBatThermRunawy 500;
BA_ "GenSigTimeoutTime" SG_ 318 CRC_SBM_LVBatInfo_2 500;
BA_ "GenSigStartValue" SG_ 318 CRC_SBM_LVBatInfo_2 65535;
BA_ "GenSigTimeoutTime" SG_ 318 AlvCtr_SBM_LVBatInfo_2 500;
BA_ "GenSigStartValue" SG_ 318 AlvCtr_SBM_LVBatInfo_2 255;
BA_ "InvalidValue" SG_ 318 Sbm_LVBatActSoh "127";
BA_ "GenSigTimeoutTime" SG_ 318 Sbm_LVBatActSoh 500;
BA_ "InvalidValue" SG_ 318 Sbm_CriticalSoCAlert "15";
BA_ "GenSigTimeoutTime" SG_ 318 Sbm_CriticalSoCAlert 500;
BA_ "InvalidValue" SG_ 318 Sbm_LvBattT "255";
BA_ "GenSigTimeoutTime" SG_ 318 Sbm_LvBattT 500;
BA_ "InvalidValue" SG_ 327 Engmt_LvAuxAvgEngCns "65535";
BA_ "GenSigTimeoutTime" SG_ 327 Engmt_LvAuxAvgEngCns 500;
BA_ "InvalidValue" SG_ 327 Engmt_InttsEngCnsRate "1023";
BA_ "GenSigTimeoutTime" SG_ 327 Engmt_InttsEngCnsRate 500;
BA_ "InvalidValue" SG_ 327 Engmt_TotAvgEngCns "65535";
BA_ "GenSigTimeoutTime" SG_ 327 Engmt_TotAvgEngCns 500;
BA_ "InvalidValue" SG_ 327 Engmt_EdsAvgEngCns "65535";
BA_ "GenSigTimeoutTime" SG_ 327 Engmt_EdsAvgEngCns 500;
BA_ "InvalidValue" SG_ 327 Engmt_ThermAvgEngCns "65535";
BA_ "GenSigTimeoutTime" SG_ 327 Engmt_ThermAvgEngCns 500;
BA_ "GenSigTimeoutTime" SG_ 349 CRC_VCU_To_Veh_Info 500;
BA_ "GenSigStartValue" SG_ 349 CRC_VCU_To_Veh_Info 65535;
BA_ "GenSigTimeoutTime" SG_ 349 AlvCtr_VCU_To_Veh_Info 500;
BA_ "GenSigStartValue" SG_ 349 AlvCtr_VCU_To_Veh_Info 255;
BA_ "InvalidValue" SG_ 349 Acchg_HVBatSoc "1023";
BA_ "GenSigTimeoutTime" SG_ 349 Acchg_HVBatSoc 500;
BA_ "GenSigStartValue" SG_ 349 Acchg_HVBatSoc 900;
BA_ "InvalidValue" SG_ 349 Acchg_AcChgSts "7";
BA_ "GenSigTimeoutTime" SG_ 349 Acchg_AcChgSts 500;
BA_ "InvalidValue" SG_ 349 Awd_ActWhlDrvMode "7";
BA_ "GenSigTimeoutTime" SG_ 349 Awd_ActWhlDrvMode 500;
BA_ "GenSigStartValue" SG_ 349 Awd_ActWhlDrvMode 1;
BA_ "InvalidValue" SG_ 349 Engmt_ChrgrDlvPwr "65535";
BA_ "GenSigTimeoutTime" SG_ 349 Engmt_ChrgrDlvPwr 500;
BA_ "InvalidValue" SG_ 349 Engmt_VehRmngDrvRng "1023";
BA_ "GenSigTimeoutTime" SG_ 349 Engmt_VehRmngDrvRng 500;
BA_ "GenSigStartValue" SG_ 349 Engmt_VehRmngDrvRng 1023;
BA_ "InvalidValue" SG_ 349 Cregb_CoastRgnLvlIndcr "7";
BA_ "GenSigTimeoutTime" SG_ 349 Cregb_CoastRgnLvlIndcr 500;
BA_ "InvalidValue" SG_ 349 Fschg_VehChrgnSts "7";
BA_ "GenSigTimeoutTime" SG_ 349 Fschg_VehChrgnSts 500;
BA_ "InvalidValue" SG_ 349 Eshift_ChngGearFromPark "3";
BA_ "GenSigTimeoutTime" SG_ 349 Eshift_ChngGearFromPark 500;
BA_ "InvalidValue" SG_ 349 Engmt_VehMilg "1023";
BA_ "GenSigTimeoutTime" SG_ 349 Engmt_VehMilg 500;
BA_ "GenSigStartValue" SG_ 349 Engmt_VehMilg 1023;
BA_ "InvalidValue" SG_ 349 Fschg_HVBatSoc "1023";
BA_ "GenSigTimeoutTime" SG_ 349 Fschg_HVBatSoc 500;
BA_ "InvalidValue" SG_ 349 Fschg_ChgGunLockSts "3";
BA_ "GenSigTimeoutTime" SG_ 349 Fschg_ChgGunLockSts 500;
BA_ "InvalidValue" SG_ 349 Awd_ActWhlDrvModeVld "3";
BA_ "GenSigTimeoutTime" SG_ 349 Awd_ActWhlDrvModeVld 500;
BA_ "GenSigTimeoutTime" SG_ 367 CRC_ZCUF_RlhsLight_Info 500;
BA_ "InvalidValue" SG_ 367 AlvCtr_ZCUF_RlhsLight_Info "15";
BA_ "GenSigTimeoutTime" SG_ 367 AlvCtr_ZCUF_RlhsLight_Info 500;
BA_ "GenSigStartValue" SG_ 367 AlvCtr_ZCUF_RlhsLight_Info 15;
BA_ "InvalidValue" SG_ 367 Rlhs_SolarDrvr "255";
BA_ "GenSigTimeoutTime" SG_ 367 Rlhs_SolarDrvr 500;
BA_ "InvalidValue" SG_ 367 Rlhs_SolarPass "255";
BA_ "GenSigTimeoutTime" SG_ 367 Rlhs_SolarPass 500;
BA_ "GenSigTimeoutTime" SG_ 371 CRC_HDLML_FrontLamp_Sts 500;
BA_ "GenSigStartValue" SG_ 371 CRC_HDLML_FrontLamp_Sts 65535;
BA_ "GenSigTimeoutTime" SG_ 371 AlvCtr_HDLML_FrontLamp_Sts 500;
BA_ "GenSigStartValue" SG_ 371 AlvCtr_HDLML_FrontLamp_Sts 255;
BA_ "InvalidValue" SG_ 371 Hdlamp_LeLoBeamLampSts "3";
BA_ "GenSigTimeoutTime" SG_ 371 Hdlamp_LeLoBeamLampSts 500;
BA_ "InvalidValue" SG_ 371 Hdlamp_LeHiBeamLampSts "7";
BA_ "GenSigTimeoutTime" SG_ 371 Hdlamp_LeHiBeamLampSts 500;
BA_ "GenSigTimeoutTime" SG_ 377 CRC_HDLMR_FrontLamp_Sts 500;
BA_ "GenSigStartValue" SG_ 377 CRC_HDLMR_FrontLamp_Sts 65535;
BA_ "GenSigTimeoutTime" SG_ 377 AlvCtr_HDLMR_FrontLamp_Sts 500;
BA_ "GenSigStartValue" SG_ 377 AlvCtr_HDLMR_FrontLamp_Sts 255;
BA_ "InvalidValue" SG_ 377 Hdlamp_RiLoBeamLampSts "3";
BA_ "GenSigTimeoutTime" SG_ 377 Hdlamp_RiLoBeamLampSts 500;
BA_ "InvalidValue" SG_ 377 Hdlamp_RiHiBeamLampSts "7";
BA_ "GenSigTimeoutTime" SG_ 377 Hdlamp_RiHiBeamLampSts 500;
BA_ "GenSigTimeoutTime" SG_ 383 CRC_SLMFL_FrontLamp_Sts 500;
BA_ "GenSigTimeoutTime" SG_ 383 AlvCtr_SLMFL_FrontLamp_Sts 500;
BA_ "GenSigStartValue" SG_ 383 AlvCtr_SLMFL_FrontLamp_Sts 255;
BA_ "InvalidValue" SG_ 383 Hdlamp_LeFrntPosnLampSts "3";
BA_ "GenSigTimeoutTime" SG_ 383 Hdlamp_LeFrntPosnLampSts 500;
BA_ "GenSigStartValue" SG_ 383 Hdlamp_LeFrntPosnLampSts 3;
BA_ "InvalidValue" SG_ 383 Hdlamp_LeDRLLampSts "3";
BA_ "GenSigTimeoutTime" SG_ 383 Hdlamp_LeDRLLampSts 500;
BA_ "GenSigStartValue" SG_ 383 Hdlamp_LeDRLLampSts 3;
BA_ "InvalidValue" SG_ 383 Hdlamp_FrntLeBodyTurnIndcrSts "7";
BA_ "GenSigTimeoutTime" SG_ 383 Hdlamp_FrntLeBodyTurnIndcrSts 500;
BA_ "GenSigStartValue" SG_ 383 Hdlamp_FrntLeBodyTurnIndcrSts 7;
BA_ "GenSigTimeoutTime" SG_ 387 CRC_SLMFR_FrontLamp_Sts 500;
BA_ "GenSigStartValue" SG_ 387 CRC_SLMFR_FrontLamp_Sts 65535;
BA_ "GenSigTimeoutTime" SG_ 387 AlvCtr_SLMFR_FrontLamp_Sts 500;
BA_ "GenSigStartValue" SG_ 387 AlvCtr_SLMFR_FrontLamp_Sts 255;
BA_ "InvalidValue" SG_ 387 Hdlamp_RiFrntPosnLampSts "3";
BA_ "GenSigTimeoutTime" SG_ 387 Hdlamp_RiFrntPosnLampSts 500;
BA_ "GenSigStartValue" SG_ 387 Hdlamp_RiFrntPosnLampSts 3;
BA_ "InvalidValue" SG_ 387 Hdlamp_RiDRLLampSts "3";
BA_ "GenSigTimeoutTime" SG_ 387 Hdlamp_RiDRLLampSts 500;
BA_ "GenSigStartValue" SG_ 387 Hdlamp_RiDRLLampSts 3;
BA_ "InvalidValue" SG_ 387 Hdlamp_FrntRiBodyTurnIndcrSts "7";
BA_ "GenSigTimeoutTime" SG_ 387 Hdlamp_FrntRiBodyTurnIndcrSts 500;
BA_ "GenSigStartValue" SG_ 387 Hdlamp_FrntRiBodyTurnIndcrSts 7;
BA_ "GenSigTimeoutTime" SG_ 393 CRC_RLML_RearLampSts 500;
BA_ "GenSigTimeoutTime" SG_ 393 AlvCtr_RLML_RearLampSts 500;
BA_ "GenSigStartValue" SG_ 393 AlvCtr_RLML_RearLampSts 255;
BA_ "InvalidValue" SG_ 393 Relamp_LeBodyBrkLampSts "3";
BA_ "GenSigTimeoutTime" SG_ 393 Relamp_LeBodyBrkLampSts 500;
BA_ "GenSigStartValue" SG_ 393 Relamp_LeBodyBrkLampSts 3;
BA_ "InvalidValue" SG_ 393 Relamp_ReLeBodyPosnLampSts "3";
BA_ "GenSigTimeoutTime" SG_ 393 Relamp_ReLeBodyPosnLampSts 500;
BA_ "GenSigStartValue" SG_ 393 Relamp_ReLeBodyPosnLampSts 3;
BA_ "InvalidValue" SG_ 393 Relamp_ReLeBodyTurnIndcrSts "7";
BA_ "GenSigTimeoutTime" SG_ 393 Relamp_ReLeBodyTurnIndcrSts 500;
BA_ "GenSigStartValue" SG_ 393 Relamp_ReLeBodyTurnIndcrSts 7;
BA_ "GenSigTimeoutTime" SG_ 399 CRC_RLMR_RearLampSts 500;
BA_ "GenSigTimeoutTime" SG_ 399 AlvCtr_RLMR_RearLampSts 500;
BA_ "GenSigStartValue" SG_ 399 AlvCtr_RLMR_RearLampSts 255;
BA_ "InvalidValue" SG_ 399 Relamp_RiBodyBrkLampSts "3";
BA_ "GenSigTimeoutTime" SG_ 399 Relamp_RiBodyBrkLampSts 500;
BA_ "GenSigStartValue" SG_ 399 Relamp_RiBodyBrkLampSts 3;
BA_ "InvalidValue" SG_ 399 Relamp_ReRiBodyPosnLampSts "3";
BA_ "GenSigTimeoutTime" SG_ 399 Relamp_ReRiBodyPosnLampSts 500;
BA_ "GenSigStartValue" SG_ 399 Relamp_ReRiBodyPosnLampSts 3;
BA_ "InvalidValue" SG_ 399 Relamp_ReRiBodyTurnIndcrSts "7";
BA_ "GenSigTimeoutTime" SG_ 399 Relamp_ReRiBodyTurnIndcrSts 500;
BA_ "GenSigStartValue" SG_ 399 Relamp_ReRiBodyTurnIndcrSts 7;
BA_ "GenSigTimeoutTime" SG_ 403 CRC_TLML_RearLampSts 500;
BA_ "GenSigTimeoutTime" SG_ 403 AlvCtr_TLML_RearLampSts 500;
BA_ "GenSigStartValue" SG_ 403 AlvCtr_TLML_RearLampSts 255;
BA_ "InvalidValue" SG_ 403 Relamp_LeTLGBrkLampSts "3";
BA_ "GenSigTimeoutTime" SG_ 403 Relamp_LeTLGBrkLampSts 500;
BA_ "GenSigStartValue" SG_ 403 Relamp_LeTLGBrkLampSts 3;
BA_ "InvalidValue" SG_ 403 Relamp_ReLeTLGPosnLampSts "3";
BA_ "GenSigTimeoutTime" SG_ 403 Relamp_ReLeTLGPosnLampSts 500;
BA_ "GenSigStartValue" SG_ 403 Relamp_ReLeTLGPosnLampSts 3;
BA_ "InvalidValue" SG_ 403 Relamp_ReLeTLGTurnIndcrSts "7";
BA_ "GenSigTimeoutTime" SG_ 403 Relamp_ReLeTLGTurnIndcrSts 500;
BA_ "GenSigStartValue" SG_ 403 Relamp_ReLeTLGTurnIndcrSts 7;
BA_ "GenSigTimeoutTime" SG_ 409 CRC_SLMFC_LampSts 500;
BA_ "GenSigTimeoutTime" SG_ 409 AlvCtr_SLMFC_LampSts 500;
BA_ "GenSigStartValue" SG_ 409 AlvCtr_SLMFC_LampSts 255;
BA_ "InvalidValue" SG_ 409 Hdlamp_FrntCentr_LeSignLampSts "3";
BA_ "GenSigTimeoutTime" SG_ 409 Hdlamp_FrntCentr_LeSignLampSts 500;
BA_ "GenSigStartValue" SG_ 409 Hdlamp_FrntCentr_LeSignLampSts 3;
BA_ "InvalidValue" SG_ 409 Hdlamp_FrntCentr_RiSignLampSts "3";
BA_ "GenSigTimeoutTime" SG_ 409 Hdlamp_FrntCentr_RiSignLampSts 500;
BA_ "GenSigStartValue" SG_ 409 Hdlamp_FrntCentr_RiSignLampSts 3;
BA_ "GenSigTimeoutTime" SG_ 410 CRC_SLMRC_LampSts 500;
BA_ "GenSigTimeoutTime" SG_ 410 AlvCtr_SLMRC_LampSts 500;
BA_ "GenSigStartValue" SG_ 410 AlvCtr_SLMRC_LampSts 255;
BA_ "InvalidValue" SG_ 410 Relamp_FrntCentr_LeSignLampSts "3";
BA_ "GenSigTimeoutTime" SG_ 410 Relamp_FrntCentr_LeSignLampSts 500;
BA_ "GenSigStartValue" SG_ 410 Relamp_FrntCentr_LeSignLampSts 3;
BA_ "InvalidValue" SG_ 410 Relamp_FrntCentr_RiSignLampSts "3";
BA_ "GenSigTimeoutTime" SG_ 410 Relamp_FrntCentr_RiSignLampSts 500;
BA_ "GenSigStartValue" SG_ 410 Relamp_FrntCentr_RiSignLampSts 3;
BA_ "GenSigTimeoutTime" SG_ 415 CRC_TLMR_RearLampSts 500;
BA_ "GenSigTimeoutTime" SG_ 415 AlvCtr_TLMR_RearLampSts 500;
BA_ "GenSigStartValue" SG_ 415 AlvCtr_TLMR_RearLampSts 255;
BA_ "InvalidValue" SG_ 415 Relamp_RiTLGBrkLampSts "3";
BA_ "GenSigTimeoutTime" SG_ 415 Relamp_RiTLGBrkLampSts 500;
BA_ "GenSigStartValue" SG_ 415 Relamp_RiTLGBrkLampSts 3;
BA_ "InvalidValue" SG_ 415 Relamp_ReRiTLGPosnLampSts "3";
BA_ "GenSigTimeoutTime" SG_ 415 Relamp_ReRiTLGPosnLampSts 500;
BA_ "GenSigStartValue" SG_ 415 Relamp_ReRiTLGPosnLampSts 3;
BA_ "InvalidValue" SG_ 415 Relamp_ReRiTLGTurnIndcrSts "7";
BA_ "GenSigTimeoutTime" SG_ 415 Relamp_ReRiTLGTurnIndcrSts 500;
BA_ "GenSigStartValue" SG_ 415 Relamp_ReRiTLGTurnIndcrSts 7;
BA_ "InvalidValue" SG_ 419 Ccsf_AgsOpenReq "3";
BA_ "GenSigTimeoutTime" SG_ 419 Ccsf_AgsOpenReq 500;
BA_ "GenSigTimeoutTime" SG_ 425 CRC_CCU_TemperatureFbk 500;
BA_ "InvalidValue" SG_ 425 AlvCtr_CCU_TemperatureFbk "15";
BA_ "GenSigTimeoutTime" SG_ 425 AlvCtr_CCU_TemperatureFbk 500;
BA_ "GenSigStartValue" SG_ 425 AlvCtr_CCU_TemperatureFbk 15;
BA_ "InvalidValue" SG_ 425 Caclh_AmbT "255";
BA_ "GenSigTimeoutTime" SG_ 425 Caclh_AmbT 500;
BA_ "GenSigTimeoutTime" SG_ 431 CRC_ZCUF_RlhsRainHumidity_Info 500;
BA_ "InvalidValue" SG_ 431 AlvCtr_ZCUF_RlhsRainHumidity_Inf "15";
BA_ "GenSigTimeoutTime" SG_ 431 AlvCtr_ZCUF_RlhsRainHumidity_Inf 500;
BA_ "GenSigStartValue" SG_ 431 AlvCtr_ZCUF_RlhsRainHumidity_Inf 15;
BA_ "InvalidValue" SG_ 431 Rlhs_RainFallSts "7";
BA_ "GenSigTimeoutTime" SG_ 431 Rlhs_RainFallSts 500;
BA_ "GenSigStartValue" SG_ 431 Rlhs_RainFallSts 7;
BA_ "GenSigTimeoutTime" SG_ 740 CRC_ADAS_Rvc_Info 5000;
BA_ "GenSigStartValue" SG_ 740 CRC_ADAS_Rvc_Info 65535;
BA_ "GenSigTimeoutTime" SG_ 740 AlvCtr_ADAS_Rvc_Info 5000;
BA_ "GenSigStartValue" SG_ 740 AlvCtr_ADAS_Rvc_Info 255;
BA_ "InvalidValue" SG_ 740 Rvc_ReBlindSpot_Sts "3";
BA_ "GenSigTimeoutTime" SG_ 740 Rvc_ReBlindSpot_Sts 5000;
BA_ "InvalidValue" SG_ 869 IVI_Acchr_chrggunUnlck_cmd "3";
BA_ "GenSigTimeoutTime" SG_ 869 IVI_Acchr_chrggunUnlck_cmd 5000;
BA_ "InvalidValue" SG_ 869 Acchg_IviChgStopReq "3";
BA_ "GenSigTimeoutTime" SG_ 869 Acchg_IviChgStopReq 5000;
BA_ "GenSigSendType" SG_ 869 Acchg_IviChgStopReq 2;
BA_ "InvalidValue" SG_ 869 Acchg_ChrgnSdleTi "4095";
BA_ "GenSigTimeoutTime" SG_ 869 Acchg_ChrgnSdleTi 5000;
BA_ "GenSigSendType" SG_ 869 Acchg_ChrgnSdleTi 2;
BA_ "InvalidValue" SG_ 869 Acchg_IviMaxChgILim "65535";
BA_ "GenSigTimeoutTime" SG_ 869 Acchg_IviMaxChgILim 5000;
BA_ "InvalidValue" SG_ 869 Acchg_PeakHourMngtEna "3";
BA_ "GenSigTimeoutTime" SG_ 869 Acchg_PeakHourMngtEna 5000;
BA_ "InvalidValue" SG_ 869 Acchg_IviEnaSdleChrgn "3";
BA_ "GenSigTimeoutTime" SG_ 869 Acchg_IviEnaSdleChrgn 5000;
BA_ "InvalidValue" SG_ 869 Acchg_IviTgtChgSocLvl "1023";
BA_ "GenSigTimeoutTime" SG_ 869 Acchg_IviTgtChgSocLvl 5000;
BA_ "GenSigStartValue" SG_ 869 Acchg_IviTgtChgSocLvl 900;
BA_ "InvalidValue" SG_ 869 Awd_WhlDrvModeSeln "3";
BA_ "GenSigTimeoutTime" SG_ 869 Awd_WhlDrvModeSeln 5000;
BA_ "GenSigSendType" SG_ 869 Awd_WhlDrvModeSeln 2;
BA_ "InvalidValue" SG_ 869 Eshift_TowMode_Req "3";
BA_ "GenSigTimeoutTime" SG_ 869 Eshift_TowMode_Req 5000;
BA_ "GenSigSendType" SG_ 869 Eshift_TowMode_Req 2;
BA_ "InvalidValue" SG_ 869 Drvmc_ValetModeAcvnSts "3";
BA_ "GenSigTimeoutTime" SG_ 869 Drvmc_ValetModeAcvnSts 5000;
BA_ "InvalidValue" SG_ 869 Drvmc_WashModeAcvnSts "3";
BA_ "GenSigTimeoutTime" SG_ 869 Drvmc_WashModeAcvnSts 5000;
BA_ "InvalidValue" SG_ 869 Dtqmt_SrvModeSpdLim "65535";
BA_ "GenSigTimeoutTime" SG_ 869 Dtqmt_SrvModeSpdLim 5000;
BA_ "InvalidValue" SG_ 869 Drvmc_ShowroomModeAcvnSts "3";
BA_ "GenSigTimeoutTime" SG_ 869 Drvmc_ShowroomModeAcvnSts 5000;
BA_ "InvalidValue" SG_ 869 Dtqmt_SrvSpdOvrrEna "3";
BA_ "GenSigTimeoutTime" SG_ 869 Dtqmt_SrvSpdOvrrEna 5000;
BA_ "GenSigSendType" SG_ 869 Dtqmt_SrvSpdOvrrEna 2;
BA_ "InvalidValue" SG_ 869 Drvmc_TrsptModeAcvnSts "3";
BA_ "GenSigTimeoutTime" SG_ 869 Drvmc_TrsptModeAcvnSts 5000;
BA_ "InvalidValue" SG_ 869 Dtqmt_ValetModeSpdLim "65535";
BA_ "GenSigTimeoutTime" SG_ 869 Dtqmt_ValetModeSpdLim 5000;
BA_ "GenSigSendType" SG_ 869 Dtqmt_ValetModeSpdLim 2;
BA_ "InvalidValue" SG_ 869 Drvmc_DrvModeSelnReq "7";
BA_ "GenSigTimeoutTime" SG_ 869 Drvmc_DrvModeSelnReq 5000;
BA_ "GenSigSendType" SG_ 869 Drvmc_DrvModeSelnReq 2;
BA_ "InvalidValue" SG_ 869 Cregb_RegenLvl_Req "7";
BA_ "GenSigTimeoutTime" SG_ 869 Cregb_RegenLvl_Req 5000;
BA_ "GenSigSendType" SG_ 869 Cregb_RegenLvl_Req 2;
BA_ "GenSigTimeoutTime" SG_ 873 CRC_ZCUR_IVI_Sts 5000;
BA_ "GenSigTimeoutTime" SG_ 873 AlvCtr_ZCUR_IVI_Sts 5000;
BA_ "GenSigStartValue" SG_ 873 AlvCtr_ZCUR_IVI_Sts 255;
BA_ "InvalidValue" SG_ 873 Acttg_TailGateSts "15";
BA_ "GenSigTimeoutTime" SG_ 873 Acttg_TailGateSts 5000;
BA_ "GenSigStartValue" SG_ 873 Acttg_TailGateSts 15;
BA_ "GenSigSendType" SG_ 873 Acttg_TailGateSts 2;
BA_ "InvalidValue" SG_ 873 Acttg_TailGateNmlznSts "3";
BA_ "GenSigTimeoutTime" SG_ 873 Acttg_TailGateNmlznSts 5000;
BA_ "GenSigStartValue" SG_ 873 Acttg_TailGateNmlznSts 3;
BA_ "GenSigSendType" SG_ 873 Acttg_TailGateNmlznSts 1;
BA_ "InvalidValue" SG_ 873 Acttg_TailGateAjarSts "3";
BA_ "GenSigTimeoutTime" SG_ 873 Acttg_TailGateAjarSts 5000;
BA_ "GenSigStartValue" SG_ 873 Acttg_TailGateAjarSts 3;
BA_ "GenSigSendType" SG_ 873 Acttg_TailGateAjarSts 2;
BA_ "InvalidValue" SG_ 873 Acttg_ActPosnAgSts "127";
BA_ "GenSigTimeoutTime" SG_ 873 Acttg_ActPosnAgSts 5000;
BA_ "GenSigSendType" SG_ 873 Acttg_ActPosnAgSts 2;
BA_ "InvalidValue" SG_ 873 SeatCfmt_ReLeVentnSts "7";
BA_ "GenSigTimeoutTime" SG_ 873 SeatCfmt_ReLeVentnSts 5000;
BA_ "GenSigStartValue" SG_ 873 SeatCfmt_ReLeVentnSts 7;
BA_ "InvalidValue" SG_ 873 SeatCfmt_ReRiVentnSts "7";
BA_ "GenSigTimeoutTime" SG_ 873 SeatCfmt_ReRiVentnSts 5000;
BA_ "GenSigStartValue" SG_ 873 SeatCfmt_ReRiVentnSts 7;
BA_ "InvalidValue" SG_ 873 SeatCfmt_ReLeVentnCshnFanFailSts "3";
BA_ "GenSigTimeoutTime" SG_ 873 SeatCfmt_ReLeVentnCshnFanFailSts 5000;
BA_ "GenSigStartValue" SG_ 873 SeatCfmt_ReLeVentnCshnFanFailSts 3;
BA_ "InvalidValue" SG_ 873 SeatCfmt_ReLeVentnSqubFanFailSts "3";
BA_ "GenSigTimeoutTime" SG_ 873 SeatCfmt_ReLeVentnSqubFanFailSts 5000;
BA_ "GenSigStartValue" SG_ 873 SeatCfmt_ReLeVentnSqubFanFailSts 3;
BA_ "InvalidValue" SG_ 873 SeatCfmt_ReRiVentnCshnFanFailSts "3";
BA_ "GenSigTimeoutTime" SG_ 873 SeatCfmt_ReRiVentnCshnFanFailSts 5000;
BA_ "GenSigStartValue" SG_ 873 SeatCfmt_ReRiVentnCshnFanFailSts 3;
BA_ "InvalidValue" SG_ 873 SeatCfmt_ReRiVentnSqubFanFailSts "3";
BA_ "GenSigTimeoutTime" SG_ 873 SeatCfmt_ReRiVentnSqubFanFailSts 5000;
BA_ "GenSigStartValue" SG_ 873 SeatCfmt_ReRiVentnSqubFanFailSts 3;
BA_ "InvalidValue" SG_ 873 ChrgrPort_LockUnlck_Sts "3";
BA_ "GenSigTimeoutTime" SG_ 873 ChrgrPort_LockUnlck_Sts 5000;
BA_ "GenSigStartValue" SG_ 873 ChrgrPort_LockUnlck_Sts 3;
BA_ "GenSigSendType" SG_ 873 ChrgrPort_LockUnlck_Sts 2;
BA_ "InvalidValue" SG_ 873 ChrgrPort_Ajar_Sts "3";
BA_ "GenSigTimeoutTime" SG_ 873 ChrgrPort_Ajar_Sts 5000;
BA_ "GenSigStartValue" SG_ 873 ChrgrPort_Ajar_Sts 3;
BA_ "GenSigSendType" SG_ 873 ChrgrPort_Ajar_Sts 2;
BA_ "InvalidValue" SG_ 873 Relamp_RiLicePlateSts "3";
BA_ "GenSigTimeoutTime" SG_ 873 Relamp_RiLicePlateSts 5000;
BA_ "GenSigStartValue" SG_ 873 Relamp_RiLicePlateSts 3;
BA_ "InvalidValue" SG_ 873 Relamp_LeLicePlateSts "3";
BA_ "GenSigTimeoutTime" SG_ 873 Relamp_LeLicePlateSts 5000;
BA_ "GenSigStartValue" SG_ 873 Relamp_LeLicePlateSts 3;
BA_ "InvalidValue" SG_ 873 Relamp_FogLampSts "3";
BA_ "GenSigTimeoutTime" SG_ 873 Relamp_FogLampSts 5000;
BA_ "GenSigStartValue" SG_ 873 Relamp_FogLampSts 3;
BA_ "InvalidValue" SG_ 873 Relamp_ChmslSts "3";
BA_ "GenSigTimeoutTime" SG_ 873 Relamp_ChmslSts 5000;
BA_ "GenSigStartValue" SG_ 873 Relamp_ChmslSts 3;
BA_ "InvalidValue" SG_ 873 Relamp_RevLmpSts "3";
BA_ "GenSigTimeoutTime" SG_ 873 Relamp_RevLmpSts 5000;
BA_ "GenSigStartValue" SG_ 873 Relamp_RevLmpSts 3;
BA_ "GenSigTimeoutTime" SG_ 883 CRC_CCU_FaultSts 500;
BA_ "GenSigStartValue" SG_ 883 CRC_CCU_FaultSts 255;
BA_ "InvalidValue" SG_ 883 AlvCtr_CCU_FaultSts "15";
BA_ "GenSigTimeoutTime" SG_ 883 AlvCtr_CCU_FaultSts 5000;
BA_ "GenSigStartValue" SG_ 883 AlvCtr_CCU_FaultSts 15;
BA_ "InvalidValue" SG_ 883 Ccsf_FrntBlowrFltSts "7";
BA_ "GenSigTimeoutTime" SG_ 883 Ccsf_FrntBlowrFltSts 5000;
BA_ "InvalidValue" SG_ 883 Ccsr_ReBlowrFltSts "7";
BA_ "GenSigTimeoutTime" SG_ 883 Ccsr_ReBlowrFltSts 5000;
BA_ "InvalidValue" SG_ 883 Ccsf_IoniserFltSts "3";
BA_ "GenSigTimeoutTime" SG_ 883 Ccsf_IoniserFltSts 5000;
BA_ "InvalidValue" SG_ 883 Ccsf_FragnConnLoss "3";
BA_ "GenSigTimeoutTime" SG_ 883 Ccsf_FragnConnLoss 5000;
BA_ "InvalidValue" SG_ 883 Ccsf_FrgrncFltSts "3";
BA_ "GenSigTimeoutTime" SG_ 883 Ccsf_FrgrncFltSts 5000;
BA_ "InvalidValue" SG_ 883 Ccsf_IoniserConnLoss "3";
BA_ "GenSigTimeoutTime" SG_ 883 Ccsf_IoniserConnLoss 5000;
BA_ "InvalidValue" SG_ 883 Ccsf_DemistFlapFltSts "7";
BA_ "GenSigTimeoutTime" SG_ 883 Ccsf_DemistFlapFltSts 5000;
BA_ "GenSigStartValue" SG_ 883 Ccsf_DemistFlapFltSts 7;
BA_ "GenSigTimeoutTime" SG_ 889 CRC_CCU_ClimSys_Sts 5000;
BA_ "GenSigStartValue" SG_ 889 CRC_CCU_ClimSys_Sts 255;
BA_ "InvalidValue" SG_ 889 AlvCtr_CCU_ClimSys_Sts "15";
BA_ "GenSigTimeoutTime" SG_ 889 AlvCtr_CCU_ClimSys_Sts 5000;
BA_ "GenSigStartValue" SG_ 889 AlvCtr_CCU_ClimSys_Sts 15;
BA_ "InvalidValue" SG_ 889 Ccsf_AirModeSelnFb "7";
BA_ "GenSigTimeoutTime" SG_ 889 Ccsf_AirModeSelnFb 5000;
BA_ "GenSigSendType" SG_ 889 Ccsf_AirModeSelnFb 2;
BA_ "InvalidValue" SG_ 889 Ccsf_FrntBlowrLvlFb "7";
BA_ "GenSigTimeoutTime" SG_ 889 Ccsf_FrntBlowrLvlFb 5000;
BA_ "GenSigSendType" SG_ 889 Ccsf_FrntBlowrLvlFb 2;
BA_ "InvalidValue" SG_ 889 Ccsf_IoniserOnOffSts "3";
BA_ "GenSigTimeoutTime" SG_ 889 Ccsf_IoniserOnOffSts 5000;
BA_ "GenSigSendType" SG_ 889 Ccsf_IoniserOnOffSts 2;
BA_ "InvalidValue" SG_ 889 Ccsf_DrvrDemistRcmn "3";
BA_ "GenSigTimeoutTime" SG_ 889 Ccsf_DrvrDemistRcmn 5000;
BA_ "GenSigSendType" SG_ 889 Ccsf_DrvrDemistRcmn 2;
BA_ "InvalidValue" SG_ 889 Ccsr_ReBlowrLvlFb "7";
BA_ "GenSigTimeoutTime" SG_ 889 Ccsr_ReBlowrLvlFb 5000;
BA_ "GenSigSendType" SG_ 889 Ccsr_ReBlowrLvlFb 2;
BA_ "InvalidValue" SG_ 889 Ccsf_RclFlapPos "15";
BA_ "GenSigTimeoutTime" SG_ 889 Ccsf_RclFlapPos 5000;
BA_ "GenSigSendType" SG_ 889 Ccsf_RclFlapPos 2;
BA_ "InvalidValue" SG_ 889 Ccsf_Co2Lvl "15";
BA_ "GenSigTimeoutTime" SG_ 889 Ccsf_Co2Lvl 5000;
BA_ "GenSigSendType" SG_ 889 Ccsf_Co2Lvl 2;
BA_ "InvalidValue" SG_ 889 Ccsf_CenLeVenDirSts "3";
BA_ "GenSigTimeoutTime" SG_ 889 Ccsf_CenLeVenDirSts 5000;
BA_ "InvalidValue" SG_ 889 Ccsf_CenRiVenDirSts "3";
BA_ "GenSigTimeoutTime" SG_ 889 Ccsf_CenRiVenDirSts 5000;
BA_ "InvalidValue" SG_ 889 Ccsf_AirQlyIdx "15";
BA_ "GenSigTimeoutTime" SG_ 889 Ccsf_AirQlyIdx 5000;
BA_ "GenSigSendType" SG_ 889 Ccsf_AirQlyIdx 2;
BA_ "InvalidValue" SG_ 889 Ccsf_RclModFb "3";
BA_ "GenSigTimeoutTime" SG_ 889 Ccsf_RclModFb 5000;
BA_ "GenSigStartValue" SG_ 889 Ccsf_RclModFb 3;
BA_ "GenSigTimeoutTime" SG_ 895 CRC_CCU_AcOpMode_Sts 5000;
BA_ "GenSigStartValue" SG_ 895 CRC_CCU_AcOpMode_Sts 255;
BA_ "InvalidValue" SG_ 895 AlvCtr_CCU_AcOpMode_Sts "15";
BA_ "GenSigTimeoutTime" SG_ 895 AlvCtr_CCU_AcOpMode_Sts 5000;
BA_ "GenSigStartValue" SG_ 895 AlvCtr_CCU_AcOpMode_Sts 15;
BA_ "InvalidValue" SG_ 895 Ccsr_HaloTSts "255";
BA_ "GenSigTimeoutTime" SG_ 895 Ccsr_HaloTSts 5000;
BA_ "GenSigSendType" SG_ 895 Ccsr_HaloTSts 2;
BA_ "InvalidValue" SG_ 895 Ccsf_AcAutoModeSts "3";
BA_ "GenSigTimeoutTime" SG_ 895 Ccsf_AcAutoModeSts 5000;
BA_ "GenSigStartValue" SG_ 895 Ccsf_AcAutoModeSts 3;
BA_ "GenSigSendType" SG_ 895 Ccsf_AcAutoModeSts 2;
BA_ "InvalidValue" SG_ 895 Caclh_AcLowPwrModeSts "3";
BA_ "GenSigTimeoutTime" SG_ 895 Caclh_AcLowPwrModeSts 5000;
BA_ "GenSigStartValue" SG_ 895 Caclh_AcLowPwrModeSts 3;
BA_ "InvalidValue" SG_ 895 Ccsf_DemistDefrstSts "3";
BA_ "GenSigTimeoutTime" SG_ 895 Ccsf_DemistDefrstSts 5000;
BA_ "GenSigStartValue" SG_ 895 Ccsf_DemistDefrstSts 3;
BA_ "InvalidValue" SG_ 895 Ccsf_FrntAcOnOffSts "3";
BA_ "GenSigTimeoutTime" SG_ 895 Ccsf_FrntAcOnOffSts 5000;
BA_ "GenSigStartValue" SG_ 895 Ccsf_FrntAcOnOffSts 3;
BA_ "InvalidValue" SG_ 895 Caclh_FrntAcOpModeSts "7";
BA_ "GenSigTimeoutTime" SG_ 895 Caclh_FrntAcOpModeSts 5000;
BA_ "GenSigStartValue" SG_ 895 Caclh_FrntAcOpModeSts 7;
BA_ "GenSigSendType" SG_ 895 Caclh_FrntAcOpModeSts 2;
BA_ "InvalidValue" SG_ 895 Caclh_ReAcOpModeSts "7";
BA_ "GenSigTimeoutTime" SG_ 895 Caclh_ReAcOpModeSts 5000;
BA_ "GenSigStartValue" SG_ 895 Caclh_ReAcOpModeSts 7;
BA_ "GenSigSendType" SG_ 895 Caclh_ReAcOpModeSts 2;
BA_ "InvalidValue" SG_ 895 Ccsr_ReAcOnOffSts "3";
BA_ "GenSigTimeoutTime" SG_ 895 Ccsr_ReAcOnOffSts 5000;
BA_ "GenSigStartValue" SG_ 895 Ccsr_ReAcOnOffSts 3;
BA_ "GenSigTimeoutTime" SG_ 899 CRC_CCU_ClimFrgrnc_Sts 5000;
BA_ "GenSigStartValue" SG_ 899 CRC_CCU_ClimFrgrnc_Sts 255;
BA_ "InvalidValue" SG_ 899 AlvCtr_CCU_ClimFrgrnc_Sts "15";
BA_ "GenSigTimeoutTime" SG_ 899 AlvCtr_CCU_ClimFrgrnc_Sts 5000;
BA_ "GenSigStartValue" SG_ 899 AlvCtr_CCU_ClimFrgrnc_Sts 15;
BA_ "InvalidValue" SG_ 899 Ccsf_Frgrnc3levelSts "1023";
BA_ "GenSigTimeoutTime" SG_ 899 Ccsf_Frgrnc3levelSts 5000;
BA_ "GenSigSendType" SG_ 899 Ccsf_Frgrnc3levelSts 2;
BA_ "InvalidValue" SG_ 899 Ccsf_FrgrncIntenSts "15";
BA_ "GenSigTimeoutTime" SG_ 899 Ccsf_FrgrncIntenSts 5000;
BA_ "GenSigSendType" SG_ 899 Ccsf_FrgrncIntenSts 2;
BA_ "InvalidValue" SG_ 899 Ccsf_FrgrncOnOffSts "3";
BA_ "GenSigTimeoutTime" SG_ 899 Ccsf_FrgrncOnOffSts 5000;
BA_ "GenSigSendType" SG_ 899 Ccsf_FrgrncOnOffSts 2;
BA_ "InvalidValue" SG_ 899 Ccsf_Frgrnc1levelSts "1023";
BA_ "GenSigTimeoutTime" SG_ 899 Ccsf_Frgrnc1levelSts 5000;
BA_ "GenSigSendType" SG_ 899 Ccsf_Frgrnc1levelSts 2;
BA_ "InvalidValue" SG_ 899 Ccsf_FrgrncSelnSts "7";
BA_ "GenSigTimeoutTime" SG_ 899 Ccsf_FrgrncSelnSts 5000;
BA_ "GenSigSendType" SG_ 899 Ccsf_FrgrncSelnSts 2;
BA_ "InvalidValue" SG_ 899 Ccsf_Frgrnc2levelSts "1023";
BA_ "GenSigTimeoutTime" SG_ 899 Ccsf_Frgrnc2levelSts 5000;
BA_ "GenSigSendType" SG_ 899 Ccsf_Frgrnc2levelSts 2;
BA_ "GenSigTimeoutTime" SG_ 911 CRC_PSMD_SeatAdjustment_Status 5000;
BA_ "GenSigStartValue" SG_ 911 CRC_PSMD_SeatAdjustment_Status 255;
BA_ "InvalidValue" SG_ 911 AlvCtr_PSMD_SeatAdjmt_Sts "15";
BA_ "GenSigTimeoutTime" SG_ 911 AlvCtr_PSMD_SeatAdjmt_Sts 5000;
BA_ "GenSigStartValue" SG_ 911 AlvCtr_PSMD_SeatAdjmt_Sts 15;
BA_ "InvalidValue" SG_ 911 SeatAdjmt_DrvLumInOutPosn "3";
BA_ "GenSigTimeoutTime" SG_ 911 SeatAdjmt_DrvLumInOutPosn 5000;
BA_ "GenSigStartValue" SG_ 911 SeatAdjmt_DrvLumInOutPosn 3;
BA_ "InvalidValue" SG_ 911 SeatAdjmt_DrvLumUpDwnPosn "7";
BA_ "GenSigTimeoutTime" SG_ 911 SeatAdjmt_DrvLumUpDwnPosn 5000;
BA_ "GenSigStartValue" SG_ 911 SeatAdjmt_DrvLumUpDwnPosn 7;
BA_ "InvalidValue" SG_ 911 SeatAdjmt_DrvLumSysFailSts "3";
BA_ "GenSigTimeoutTime" SG_ 911 SeatAdjmt_DrvLumSysFailSts 5000;
BA_ "GenSigStartValue" SG_ 911 SeatAdjmt_DrvLumSysFailSts 3;
BA_ "InvalidValue" SG_ 911 SeatAdjmt_DrvHeiUpDwnMotSts "7";
BA_ "GenSigTimeoutTime" SG_ 911 SeatAdjmt_DrvHeiUpDwnMotSts 5000;
BA_ "GenSigStartValue" SG_ 911 SeatAdjmt_DrvHeiUpDwnMotSts 7;
BA_ "InvalidValue" SG_ 911 SeatAdjmt_DrvReclUpDwnMotSts "7";
BA_ "GenSigTimeoutTime" SG_ 911 SeatAdjmt_DrvReclUpDwnMotSts 5000;
BA_ "GenSigStartValue" SG_ 911 SeatAdjmt_DrvReclUpDwnMotSts 7;
BA_ "InvalidValue" SG_ 911 SeatAdjmt_DrvAdjmtSts "3";
BA_ "GenSigTimeoutTime" SG_ 911 SeatAdjmt_DrvAdjmtSts 5000;
BA_ "GenSigStartValue" SG_ 911 SeatAdjmt_DrvAdjmtSts 3;
BA_ "InvalidValue" SG_ 911 SeatAdjmt_DrvFrntBackMotSts "7";
BA_ "GenSigTimeoutTime" SG_ 911 SeatAdjmt_DrvFrntBackMotSts 5000;
BA_ "GenSigStartValue" SG_ 911 SeatAdjmt_DrvFrntBackMotSts 7;
BA_ "InvalidValue" SG_ 911 SeatAdjmt_DrvTiltUpDwnMotSts "7";
BA_ "GenSigTimeoutTime" SG_ 911 SeatAdjmt_DrvTiltUpDwnMotSts 5000;
BA_ "GenSigStartValue" SG_ 911 SeatAdjmt_DrvTiltUpDwnMotSts 7;
BA_ "GenSigTimeoutTime" SG_ 915 CRC_PSMP_SeatAdjustment_Status 5000;
BA_ "GenSigStartValue" SG_ 915 CRC_PSMP_SeatAdjustment_Status 255;
BA_ "InvalidValue" SG_ 915 AlvCtr_PSMP_SeatAdjmt_Sts "15";
BA_ "GenSigTimeoutTime" SG_ 915 AlvCtr_PSMP_SeatAdjmt_Sts 5000;
BA_ "GenSigStartValue" SG_ 915 AlvCtr_PSMP_SeatAdjmt_Sts 15;
BA_ "InvalidValue" SG_ 915 SeatAdjmt_PassLumInOutPosn "3";
BA_ "GenSigTimeoutTime" SG_ 915 SeatAdjmt_PassLumInOutPosn 5000;
BA_ "GenSigStartValue" SG_ 915 SeatAdjmt_PassLumInOutPosn 3;
BA_ "InvalidValue" SG_ 915 SeatAdjmt_PassLumUpDownPosn "7";
BA_ "GenSigTimeoutTime" SG_ 915 SeatAdjmt_PassLumUpDownPosn 5000;
BA_ "GenSigStartValue" SG_ 915 SeatAdjmt_PassLumUpDownPosn 7;
BA_ "InvalidValue" SG_ 915 SeatAdjmt_PassLumSysFailSts "3";
BA_ "GenSigTimeoutTime" SG_ 915 SeatAdjmt_PassLumSysFailSts 5000;
BA_ "GenSigStartValue" SG_ 915 SeatAdjmt_PassLumSysFailSts 3;
BA_ "InvalidValue" SG_ 915 SeatAdjmt_PassReclUpDwnMotSts "7";
BA_ "GenSigTimeoutTime" SG_ 915 SeatAdjmt_PassReclUpDwnMotSts 5000;
BA_ "GenSigStartValue" SG_ 915 SeatAdjmt_PassReclUpDwnMotSts 7;
BA_ "InvalidValue" SG_ 915 SeatAdjmt_PassHeiUpDwnMotSts_ "7";
BA_ "GenSigTimeoutTime" SG_ 915 SeatAdjmt_PassHeiUpDwnMotSts_ 5000;
BA_ "GenSigStartValue" SG_ 915 SeatAdjmt_PassHeiUpDwnMotSts_ 7;
BA_ "InvalidValue" SG_ 915 SeatAdjmt_PassAdjmtSts "3";
BA_ "GenSigTimeoutTime" SG_ 915 SeatAdjmt_PassAdjmtSts 5000;
BA_ "GenSigStartValue" SG_ 915 SeatAdjmt_PassAdjmtSts 3;
BA_ "InvalidValue" SG_ 915 SeatAdjmt_PassFowdBawdMotSts "7";
BA_ "GenSigTimeoutTime" SG_ 915 SeatAdjmt_PassFowdBawdMotSts 5000;
BA_ "GenSigStartValue" SG_ 915 SeatAdjmt_PassFowdBawdMotSts 7;
BA_ "InvalidValue" SG_ 915 SeatAdjmt_PassTiltUpDwnMotSts "7";
BA_ "GenSigTimeoutTime" SG_ 915 SeatAdjmt_PassTiltUpDwnMotSts 5000;
BA_ "GenSigStartValue" SG_ 915 SeatAdjmt_PassTiltUpDwnMotSts 7;
BA_ "GenSigTimeoutTime" SG_ 921 CRC_PSMD_SeatPos_Status 5000;
BA_ "GenSigStartValue" SG_ 921 CRC_PSMD_SeatPos_Status 255;
BA_ "InvalidValue" SG_ 921 AlvCtr_PSMD_SeatPos_Status "15";
BA_ "GenSigTimeoutTime" SG_ 921 AlvCtr_PSMD_SeatPos_Status 5000;
BA_ "GenSigStartValue" SG_ 921 AlvCtr_PSMD_SeatPos_Status 15;
BA_ "InvalidValue" SG_ 921 SeatAdjmt_DrvFowdBawdPosn "2047";
BA_ "GenSigTimeoutTime" SG_ 921 SeatAdjmt_DrvFowdBawdPosn 5000;
BA_ "InvalidValue" SG_ 921 SeatAdjmt_DrvHeiUpDwnPosn "2047";
BA_ "GenSigTimeoutTime" SG_ 921 SeatAdjmt_DrvHeiUpDwnPosn 5000;
BA_ "InvalidValue" SG_ 921 SeatAdjmt_DrvReclUpDwnPosn "8191";
BA_ "GenSigTimeoutTime" SG_ 921 SeatAdjmt_DrvReclUpDwnPosn 5000;
BA_ "InvalidValue" SG_ 921 SeatAdjmt_DrvTiltUpDwnPosn "1023";
BA_ "GenSigTimeoutTime" SG_ 921 SeatAdjmt_DrvTiltUpDwnPosn 5000;
BA_ "GenSigTimeoutTime" SG_ 927 CRC_PSMD_SeatCmfrt_Status 5000;
BA_ "GenSigStartValue" SG_ 927 CRC_PSMD_SeatCmfrt_Status 255;
BA_ "InvalidValue" SG_ 927 AlvCtr_PSMD_SeatCmfrt_Status "15";
BA_ "GenSigTimeoutTime" SG_ 927 AlvCtr_PSMD_SeatCmfrt_Status 5000;
BA_ "GenSigStartValue" SG_ 927 AlvCtr_PSMD_SeatCmfrt_Status 15;
BA_ "InvalidValue" SG_ 927 SeatCfmt_DrvHeatgSts "7";
BA_ "GenSigTimeoutTime" SG_ 927 SeatCfmt_DrvHeatgSts 5000;
BA_ "GenSigStartValue" SG_ 927 SeatCfmt_DrvHeatgSts 7;
BA_ "InvalidValue" SG_ 927 SeatCfmt_DrvVentnSts "7";
BA_ "GenSigTimeoutTime" SG_ 927 SeatCfmt_DrvVentnSts 5000;
BA_ "GenSigStartValue" SG_ 927 SeatCfmt_DrvVentnSts 7;
BA_ "InvalidValue" SG_ 927 SeatCfmt_DrvVentnCshnFanFailSts "3";
BA_ "GenSigTimeoutTime" SG_ 927 SeatCfmt_DrvVentnCshnFanFailSts 5000;
BA_ "GenSigStartValue" SG_ 927 SeatCfmt_DrvVentnCshnFanFailSts 3;
BA_ "InvalidValue" SG_ 927 SeatCfmt_DrvHeatgBackPadFailSts "3";
BA_ "GenSigTimeoutTime" SG_ 927 SeatCfmt_DrvHeatgBackPadFailSts 5000;
BA_ "GenSigStartValue" SG_ 927 SeatCfmt_DrvHeatgBackPadFailSts 3;
BA_ "InvalidValue" SG_ 927 SeatCfmt_DrvMassgFailSts "3";
BA_ "GenSigTimeoutTime" SG_ 927 SeatCfmt_DrvMassgFailSts 5000;
BA_ "GenSigStartValue" SG_ 927 SeatCfmt_DrvMassgFailSts 3;
BA_ "InvalidValue" SG_ 927 SeatCfmt_DrvHeatgCshnPadFailSts "3";
BA_ "GenSigTimeoutTime" SG_ 927 SeatCfmt_DrvHeatgCshnPadFailSts 5000;
BA_ "GenSigStartValue" SG_ 927 SeatCfmt_DrvHeatgCshnPadFailSts 3;
BA_ "InvalidValue" SG_ 927 SeatCfmt_DrvMassg_Sts "3";
BA_ "GenSigTimeoutTime" SG_ 927 SeatCfmt_DrvMassg_Sts 5000;
BA_ "GenSigStartValue" SG_ 927 SeatCfmt_DrvMassg_Sts 3;
BA_ "InvalidValue" SG_ 927 SeatCfmt_DrvVentnSqubFanFailSts "3";
BA_ "GenSigTimeoutTime" SG_ 927 SeatCfmt_DrvVentnSqubFanFailSts 5000;
BA_ "GenSigStartValue" SG_ 927 SeatCfmt_DrvVentnSqubFanFailSts 3;
BA_ "GenSigTimeoutTime" SG_ 931 CRC_PSMP_SeatCmfrt_Status 5000;
BA_ "InvalidValue" SG_ 931 AlvCtr_PSMP_SeatCmfrt_Status "15";
BA_ "GenSigTimeoutTime" SG_ 931 AlvCtr_PSMP_SeatCmfrt_Status 5000;
BA_ "GenSigStartValue" SG_ 931 AlvCtr_PSMP_SeatCmfrt_Status 15;
BA_ "InvalidValue" SG_ 931 SeatCfmt_PassVentnSts "7";
BA_ "GenSigTimeoutTime" SG_ 931 SeatCfmt_PassVentnSts 5000;
BA_ "GenSigStartValue" SG_ 931 SeatCfmt_PassVentnSts 7;
BA_ "InvalidValue" SG_ 931 SeatCfmt_PassHeatgSts "7";
BA_ "GenSigTimeoutTime" SG_ 931 SeatCfmt_PassHeatgSts 5000;
BA_ "GenSigStartValue" SG_ 931 SeatCfmt_PassHeatgSts 7;
BA_ "InvalidValue" SG_ 931 SeatCfmt_PassMassgSts "3";
BA_ "GenSigTimeoutTime" SG_ 931 SeatCfmt_PassMassgSts 5000;
BA_ "GenSigStartValue" SG_ 931 SeatCfmt_PassMassgSts 3;
BA_ "InvalidValue" SG_ 931 SeatCfmt_PassVentnSqubFanFailSts "3";
BA_ "GenSigTimeoutTime" SG_ 931 SeatCfmt_PassVentnSqubFanFailSts 5000;
BA_ "GenSigStartValue" SG_ 931 SeatCfmt_PassVentnSqubFanFailSts 3;
BA_ "InvalidValue" SG_ 931 SeatCfmt_PassMassgFailSts "3";
BA_ "GenSigTimeoutTime" SG_ 931 SeatCfmt_PassMassgFailSts 5000;
BA_ "GenSigStartValue" SG_ 931 SeatCfmt_PassMassgFailSts 3;
BA_ "InvalidValue" SG_ 931 SeatCfmt_PassVentnCshnFanFailSts "3";
BA_ "GenSigTimeoutTime" SG_ 931 SeatCfmt_PassVentnCshnFanFailSts 5000;
BA_ "GenSigStartValue" SG_ 931 SeatCfmt_PassVentnCshnFanFailSts 3;
BA_ "InvalidValue" SG_ 931 SeatCfmt_PassHeatgBackPadFailSts "3";
BA_ "GenSigTimeoutTime" SG_ 931 SeatCfmt_PassHeatgBackPadFailSts 5000;
BA_ "GenSigStartValue" SG_ 931 SeatCfmt_PassHeatgBackPadFailSts 3;
BA_ "InvalidValue" SG_ 931 SeatCfmt_PassHeatgCshnPadFailSts "3";
BA_ "GenSigTimeoutTime" SG_ 931 SeatCfmt_PassHeatgCshnPadFailSts 5000;
BA_ "GenSigStartValue" SG_ 931 SeatCfmt_PassHeatgCshnPadFailSts 3;
BA_ "GenSigTimeoutTime" SG_ 937 CRC_PSMP_SeatPos_Status 5000;
BA_ "InvalidValue" SG_ 937 AlvCtr_PSMP_SeatPos_Status "15";
BA_ "GenSigTimeoutTime" SG_ 937 AlvCtr_PSMP_SeatPos_Status 5000;
BA_ "GenSigStartValue" SG_ 937 AlvCtr_PSMP_SeatPos_Status 15;
BA_ "InvalidValue" SG_ 937 SeatAdjmt_PassFowdBawdPosn "2047";
BA_ "GenSigTimeoutTime" SG_ 937 SeatAdjmt_PassFowdBawdPosn 5000;
BA_ "InvalidValue" SG_ 937 SeatAdjmt_PassHeiUpDwnPosn "2047";
BA_ "GenSigTimeoutTime" SG_ 937 SeatAdjmt_PassHeiUpDwnPosn 5000;
BA_ "InvalidValue" SG_ 937 SeatAdjmt_PassReclUpDwnPosn "8191";
BA_ "GenSigTimeoutTime" SG_ 937 SeatAdjmt_PassReclUpDwnPosn 5000;
BA_ "InvalidValue" SG_ 937 SeatAdjmt_PassTiltUpDwnPosn "1023";
BA_ "GenSigTimeoutTime" SG_ 937 SeatAdjmt_PassTiltUpDwnPosn 5000;
BA_ "GenSigTimeoutTime" SG_ 995 CRC_DCMD_ClosureSts 10000;
BA_ "GenSigStartValue" SG_ 995 CRC_DCMD_ClosureSts 255;
BA_ "InvalidValue" SG_ 995 AlvCtr_DCMD_ClosureSts "15";
BA_ "GenSigTimeoutTime" SG_ 995 AlvCtr_DCMD_ClosureSts 10000;
BA_ "GenSigStartValue" SG_ 995 AlvCtr_DCMD_ClosureSts 15;
BA_ "InvalidValue" SG_ 995 Pwd_DrvrDoorSts "15";
BA_ "GenSigTimeoutTime" SG_ 995 Pwd_DrvrDoorSts 10000;
BA_ "GenSigStartValue" SG_ 995 Pwd_DrvrDoorSts 15;
BA_ "GenSigSendType" SG_ 995 Pwd_DrvrDoorSts 2;
BA_ "InvalidValue" SG_ 995 CenLock_DrvrDoorLockUnlckSts "3";
BA_ "GenSigTimeoutTime" SG_ 995 CenLock_DrvrDoorLockUnlckSts 10000;
BA_ "GenSigStartValue" SG_ 995 CenLock_DrvrDoorLockUnlckSts 3;
BA_ "GenSigSendType" SG_ 995 CenLock_DrvrDoorLockUnlckSts 2;
BA_ "InvalidValue" SG_ 995 Pwd_DrvrDoorNmlznSts "3";
BA_ "GenSigTimeoutTime" SG_ 995 Pwd_DrvrDoorNmlznSts 10000;
BA_ "GenSigStartValue" SG_ 995 Pwd_DrvrDoorNmlznSts 3;
BA_ "GenSigSendType" SG_ 995 Pwd_DrvrDoorNmlznSts 2;
BA_ "InvalidValue" SG_ 995 CenLock_DrvrDoorAjarSts "3";
BA_ "GenSigTimeoutTime" SG_ 995 CenLock_DrvrDoorAjarSts 10000;
BA_ "GenSigStartValue" SG_ 995 CenLock_DrvrDoorAjarSts 3;
BA_ "GenSigSendType" SG_ 995 CenLock_DrvrDoorAjarSts 2;
BA_ "InvalidValue" SG_ 995 Pwind_DrvWndwSts "7";
BA_ "GenSigTimeoutTime" SG_ 995 Pwind_DrvWndwSts 10000;
BA_ "GenSigStartValue" SG_ 995 Pwind_DrvWndwSts 7;
BA_ "GenSigSendType" SG_ 995 Pwind_DrvWndwSts 2;
BA_ "InvalidValue" SG_ 995 Pwd_DrvDoorActPos "127";
BA_ "GenSigTimeoutTime" SG_ 995 Pwd_DrvDoorActPos 10000;
BA_ "GenSigSendType" SG_ 995 Pwd_DrvDoorActPos 2;
BA_ "InvalidValue" SG_ 997 SeatAdjmt_PassHeiStoredPosn "2047";
BA_ "GenSigSendType" SG_ 997 SeatAdjmt_PassHeiStoredPosn 1;
BA_ "InvalidValue" SG_ 997 SeatAdjmt_PassReclStoredPosn "8191";
BA_ "GenSigSendType" SG_ 997 SeatAdjmt_PassReclStoredPosn 1;
BA_ "InvalidValue" SG_ 997 SeatAdjmt_PassTiltStoredPosn "1023";
BA_ "GenSigSendType" SG_ 997 SeatAdjmt_PassTiltStoredPosn 1;
BA_ "InvalidValue" SG_ 997 SeatAdjmt_PassFowdBawdStoredPosn "2047";
BA_ "GenSigSendType" SG_ 997 SeatAdjmt_PassFowdBawdStoredPosn 1;
BA_ "GenSigTimeoutTime" SG_ 999 CRC_VCU_Sts 10000;
BA_ "GenSigStartValue" SG_ 999 CRC_VCU_Sts 65535;
BA_ "GenSigTimeoutTime" SG_ 999 AlvCtr_VCU_Sts 10000;
BA_ "GenSigStartValue" SG_ 999 AlvCtr_VCU_Sts 255;
BA_ "InvalidValue" SG_ 999 Engmt_LimphmSts "3";
BA_ "GenSigTimeoutTime" SG_ 999 Engmt_LimphmSts 10000;
BA_ "InvalidValue" SG_ 999 Fschg_ChgAuthenSts "7";
BA_ "GenSigTimeoutTime" SG_ 999 Fschg_ChgAuthenSts 10000;
BA_ "InvalidValue" SG_ 999 Acchg_ChgAuthnSts "7";
BA_ "GenSigTimeoutTime" SG_ 999 Acchg_ChgAuthnSts 10000;
BA_ "InvalidValue" SG_ 999 Thmgt_ThermFltSts "3";
BA_ "GenSigTimeoutTime" SG_ 999 Thmgt_ThermFltSts 10000;
BA_ "GenSigStartValue" SG_ 999 Thmgt_ThermFltSts 2;
BA_ "InvalidValue" SG_ 999 Cregb_CoastRgnTqPctg "255";
BA_ "GenSigTimeoutTime" SG_ 999 Cregb_CoastRgnTqPctg 10000;
BA_ "InvalidValue" SG_ 999 Hfdia_RemdActn "255";
BA_ "GenSigTimeoutTime" SG_ 999 Hfdia_RemdActn 10000;
BA_ "InvalidValue" SG_ 999 Hvsco_HvSysSts "7";
BA_ "GenSigTimeoutTime" SG_ 999 Hvsco_HvSysSts 10000;
BA_ "GenSigTimeoutTime" SG_ 1001 CRC_DCMP_ClosureSts 10000;
BA_ "GenSigStartValue" SG_ 1001 CRC_DCMP_ClosureSts 255;
BA_ "InvalidValue" SG_ 1001 AlvCtr_DCMP_ClosureSts "15";
BA_ "GenSigTimeoutTime" SG_ 1001 AlvCtr_DCMP_ClosureSts 10000;
BA_ "GenSigStartValue" SG_ 1001 AlvCtr_DCMP_ClosureSts 15;
BA_ "InvalidValue" SG_ 1001 CenLock_PassDoorAjarSts "3";
BA_ "GenSigTimeoutTime" SG_ 1001 CenLock_PassDoorAjarSts 10000;
BA_ "GenSigStartValue" SG_ 1001 CenLock_PassDoorAjarSts 3;
BA_ "GenSigSendType" SG_ 1001 CenLock_PassDoorAjarSts 2;
BA_ "InvalidValue" SG_ 1001 CenLock_PassDoorLockUnlckSts "3";
BA_ "GenSigTimeoutTime" SG_ 1001 CenLock_PassDoorLockUnlckSts 10000;
BA_ "GenSigStartValue" SG_ 1001 CenLock_PassDoorLockUnlckSts 3;
BA_ "GenSigSendType" SG_ 1001 CenLock_PassDoorLockUnlckSts 2;
BA_ "InvalidValue" SG_ 1001 Pwd_PassDoorSts "15";
BA_ "GenSigTimeoutTime" SG_ 1001 Pwd_PassDoorSts 10000;
BA_ "GenSigStartValue" SG_ 1001 Pwd_PassDoorSts 15;
BA_ "GenSigSendType" SG_ 1001 Pwd_PassDoorSts 2;
BA_ "InvalidValue" SG_ 1001 Pwd_PassDoorActPos "127";
BA_ "GenSigTimeoutTime" SG_ 1001 Pwd_PassDoorActPos 10000;
BA_ "GenSigSendType" SG_ 1001 Pwd_PassDoorActPos 2;
BA_ "InvalidValue" SG_ 1001 Pwind_PassWndwSts "7";
BA_ "GenSigTimeoutTime" SG_ 1001 Pwind_PassWndwSts 10000;
BA_ "GenSigStartValue" SG_ 1001 Pwind_PassWndwSts 7;
BA_ "GenSigSendType" SG_ 1001 Pwind_PassWndwSts 2;
BA_ "InvalidValue" SG_ 1001 Pwd_PassDoorNmlznSts "3";
BA_ "GenSigTimeoutTime" SG_ 1001 Pwd_PassDoorNmlznSts 10000;
BA_ "GenSigStartValue" SG_ 1001 Pwd_PassDoorNmlznSts 3;
BA_ "GenSigSendType" SG_ 1001 Pwd_PassDoorNmlznSts 2;
BA_ "GenSigTimeoutTime" SG_ 1007 CRC_DCMRR_ClosureSts 10000;
BA_ "GenSigStartValue" SG_ 1007 CRC_DCMRR_ClosureSts 255;
BA_ "InvalidValue" SG_ 1007 AlvCtr_DCMRR_ClosureSts "15";
BA_ "GenSigTimeoutTime" SG_ 1007 AlvCtr_DCMRR_ClosureSts 10000;
BA_ "GenSigStartValue" SG_ 1007 AlvCtr_DCMRR_ClosureSts 15;
BA_ "InvalidValue" SG_ 1007 CenLock_ReRiDoorLockUnlckSts "3";
BA_ "GenSigTimeoutTime" SG_ 1007 CenLock_ReRiDoorLockUnlckSts 10000;
BA_ "GenSigStartValue" SG_ 1007 CenLock_ReRiDoorLockUnlckSts 3;
BA_ "GenSigSendType" SG_ 1007 CenLock_ReRiDoorLockUnlckSts 2;
BA_ "InvalidValue" SG_ 1007 Pwind_ReRiWndwSts "7";
BA_ "GenSigTimeoutTime" SG_ 1007 Pwind_ReRiWndwSts 10000;
BA_ "GenSigStartValue" SG_ 1007 Pwind_ReRiWndwSts 7;
BA_ "GenSigSendType" SG_ 1007 Pwind_ReRiWndwSts 2;
BA_ "GenSigTimeoutTime" SG_ 1011 CRC_DCMRL_ClosureSts 10000;
BA_ "GenSigStartValue" SG_ 1011 CRC_DCMRL_ClosureSts 255;
BA_ "InvalidValue" SG_ 1011 AlvCtr_DCMRL_ClosureSts "15";
BA_ "GenSigTimeoutTime" SG_ 1011 AlvCtr_DCMRL_ClosureSts 10000;
BA_ "GenSigStartValue" SG_ 1011 AlvCtr_DCMRL_ClosureSts 15;
BA_ "InvalidValue" SG_ 1011 CenLock_ReLeDoorLockUnlckSts "3";
BA_ "GenSigTimeoutTime" SG_ 1011 CenLock_ReLeDoorLockUnlckSts 10000;
BA_ "GenSigStartValue" SG_ 1011 CenLock_ReLeDoorLockUnlckSts 3;
BA_ "GenSigSendType" SG_ 1011 CenLock_ReLeDoorLockUnlckSts 2;
BA_ "InvalidValue" SG_ 1011 CenLock_ReLeDoorAjarSts "3";
BA_ "GenSigTimeoutTime" SG_ 1011 CenLock_ReLeDoorAjarSts 10000;
BA_ "GenSigStartValue" SG_ 1011 CenLock_ReLeDoorAjarSts 3;
BA_ "GenSigSendType" SG_ 1011 CenLock_ReLeDoorAjarSts 2;
BA_ "InvalidValue" SG_ 1011 Pwind_ReLeWndwSts "7";
BA_ "GenSigTimeoutTime" SG_ 1011 Pwind_ReLeWndwSts 10000;
BA_ "GenSigStartValue" SG_ 1011 Pwind_ReLeWndwSts 7;
BA_ "GenSigSendType" SG_ 1011 Pwind_ReLeWndwSts 2;
BA_ "GenSigTimeoutTime" SG_ 1017 CRC_ZCUF_WiperSts 10000;
BA_ "GenSigTimeoutTime" SG_ 1017 AlvCtr_ZCUF_WiperSts 10000;
BA_ "GenSigStartValue" SG_ 1017 AlvCtr_ZCUF_WiperSts 255;
BA_ "InvalidValue" SG_ 1017 Wipr_FrntLeParkPosSts "3";
BA_ "GenSigTimeoutTime" SG_ 1017 Wipr_FrntLeParkPosSts 10000;
BA_ "GenSigStartValue" SG_ 1017 Wipr_FrntLeParkPosSts 3;
BA_ "GenSigSendType" SG_ 1017 Wipr_FrntLeParkPosSts 2;
BA_ "InvalidValue" SG_ 1017 Wipr_FrntLeSerPosSts "3";
BA_ "GenSigTimeoutTime" SG_ 1017 Wipr_FrntLeSerPosSts 10000;
BA_ "GenSigStartValue" SG_ 1017 Wipr_FrntLeSerPosSts 3;
BA_ "GenSigSendType" SG_ 1017 Wipr_FrntLeSerPosSts 2;
BA_ "InvalidValue" SG_ 1017 Wipr_FrntLeSts "3";
BA_ "GenSigTimeoutTime" SG_ 1017 Wipr_FrntLeSts 10000;
BA_ "GenSigStartValue" SG_ 1017 Wipr_FrntLeSts 3;
BA_ "GenSigSendType" SG_ 1017 Wipr_FrntLeSts 2;
BA_ "InvalidValue" SG_ 1017 Wipr_FrntRiParkPosSts "3";
BA_ "GenSigTimeoutTime" SG_ 1017 Wipr_FrntRiParkPosSts 10000;
BA_ "GenSigStartValue" SG_ 1017 Wipr_FrntRiParkPosSts 3;
BA_ "GenSigSendType" SG_ 1017 Wipr_FrntRiParkPosSts 2;
BA_ "InvalidValue" SG_ 1017 Wipr_FrntRiSerPosSts "3";
BA_ "GenSigTimeoutTime" SG_ 1017 Wipr_FrntRiSerPosSts 10000;
BA_ "GenSigStartValue" SG_ 1017 Wipr_FrntRiSerPosSts 3;
BA_ "GenSigSendType" SG_ 1017 Wipr_FrntRiSerPosSts 2;
BA_ "InvalidValue" SG_ 1017 Wipr_FrntRiSts "3";
BA_ "GenSigTimeoutTime" SG_ 1017 Wipr_FrntRiSts 10000;
BA_ "GenSigStartValue" SG_ 1017 Wipr_FrntRiSts 3;
BA_ "GenSigSendType" SG_ 1017 Wipr_FrntRiSts 2;
BA_ "InvalidValue" SG_ 1017 Wipr_WshrSts "3";
BA_ "GenSigTimeoutTime" SG_ 1017 Wipr_WshrSts 10000;
BA_ "GenSigStartValue" SG_ 1017 Wipr_WshrSts 3;
BA_ "GenSigSendType" SG_ 1017 Wipr_WshrSts 2;
BA_ "InvalidValue" SG_ 1017 Wipr_WshrFluidLevelSts "7";
BA_ "GenSigTimeoutTime" SG_ 1017 Wipr_WshrFluidLevelSts 10000;
BA_ "GenSigStartValue" SG_ 1017 Wipr_WshrFluidLevelSts 3;
BA_ "GenSigSendType" SG_ 1017 Wipr_WshrFluidLevelSts 2;
BA_ "InvalidValue" SG_ 1017 Wipr_FrntRiFaildSts "15";
BA_ "GenSigTimeoutTime" SG_ 1017 Wipr_FrntRiFaildSts 10000;
BA_ "GenSigStartValue" SG_ 1017 Wipr_FrntRiFaildSts 15;
BA_ "GenSigSendType" SG_ 1017 Wipr_FrntRiFaildSts 2;
BA_ "InvalidValue" SG_ 1017 Wipr_FrntLeFaildSts "15";
BA_ "GenSigTimeoutTime" SG_ 1017 Wipr_FrntLeFaildSts 10000;
BA_ "GenSigStartValue" SG_ 1017 Wipr_FrntLeFaildSts 15;
BA_ "GenSigSendType" SG_ 1017 Wipr_FrntLeFaildSts 2;
BA_ "InvalidValue" SG_ 1023 Ccs_DrvrSideSetTValSts "15";
BA_ "GenSigTimeoutTime" SG_ 1023 Ccs_DrvrSideSetTValSts 10000;
BA_ "GenSigStartValue" SG_ 1023 Ccs_DrvrSideSetTValSts 4;
BA_ "InvalidValue" SG_ 1023 Ccs_PassSideSetTValSts "15";
BA_ "GenSigTimeoutTime" SG_ 1023 Ccs_PassSideSetTValSts 10000;
BA_ "GenSigStartValue" SG_ 1023 Ccs_PassSideSetTValSts 4;
BA_ "InvalidValue" SG_ 1023 Ccs_ReRiSideSetTValSts "15";
BA_ "GenSigTimeoutTime" SG_ 1023 Ccs_ReRiSideSetTValSts 10000;
BA_ "GenSigStartValue" SG_ 1023 Ccs_ReRiSideSetTValSts 4;
BA_ "InvalidValue" SG_ 1023 Ccs_ReLeSideSetTValSts "15";
BA_ "GenSigTimeoutTime" SG_ 1023 Ccs_ReLeSideSetTValSts 10000;
BA_ "GenSigStartValue" SG_ 1023 Ccs_ReLeSideSetTValSts 4;
BA_ "InvalidValue" SG_ 1023 Ccs_HaloSetTValSts "15";
BA_ "GenSigTimeoutTime" SG_ 1023 Ccs_HaloSetTValSts 10000;
BA_ "GenSigStartValue" SG_ 1023 Ccs_HaloSetTValSts 4;
BA_ "GenSigTimeoutTime" SG_ 1027 CRC_ZCUF_CenLock_Info 10000;
BA_ "InvalidValue" SG_ 1027 AlvCtr_ZCUF_CenLock_Info "15";
BA_ "GenSigTimeoutTime" SG_ 1027 AlvCtr_ZCUF_CenLock_Info 10000;
BA_ "GenSigStartValue" SG_ 1027 AlvCtr_ZCUF_CenLock_Info 15;
BA_ "InvalidValue" SG_ 1027 CenLock_CAppLockUnlckSt "3";
BA_ "GenSigTimeoutTime" SG_ 1027 CenLock_CAppLockUnlckSt 10000;
BA_ "GenSigStartValue" SG_ 1027 CenLock_CAppLockUnlckSt 3;
BA_ "GenSigSendType" SG_ 1027 CenLock_CAppLockUnlckSt 2;
BA_ "InvalidValue" SG_ 1027 CenLock_LockUnlckSts "7";
BA_ "GenSigTimeoutTime" SG_ 1027 CenLock_LockUnlckSts 10000;
BA_ "GenSigStartValue" SG_ 1027 CenLock_LockUnlckSts 7;
BA_ "GenSigSendType" SG_ 1027 CenLock_LockUnlckSts 2;
BA_ "GenSigTimeoutTime" SG_ 1123 CRC_ACM_ActvTrackingStatus 10000;
BA_ "GenSigStartValue" SG_ 1123 CRC_ACM_ActvTrackingStatus 255;
BA_ "InvalidValue" SG_ 1123 AlvCtr_ACM_ActvTrackingStatus "15";
BA_ "GenSigTimeoutTime" SG_ 1123 AlvCtr_ACM_ActvTrackingStatus 10000;
BA_ "GenSigStartValue" SG_ 1123 AlvCtr_ACM_ActvTrackingStatus 15;
BA_ "InvalidValue" SG_ 1123 AirBg_SeatTrackPosPass "3";
BA_ "GenSigTimeoutTime" SG_ 1123 AirBg_SeatTrackPosPass 10000;
BA_ "GenSigSendType" SG_ 1123 AirBg_SeatTrackPosPass 2;
BA_ "InvalidValue" SG_ 1123 AirBg_SeatTrackPosDrvr "3";
BA_ "GenSigTimeoutTime" SG_ 1123 AirBg_SeatTrackPosDrvr 10000;
BA_ "GenSigSendType" SG_ 1123 AirBg_SeatTrackPosDrvr 2;
BA_ "InvalidValue" SG_ 1123 AirBg_PassAirbgDeacSts "3";
BA_ "GenSigTimeoutTime" SG_ 1123 AirBg_PassAirbgDeacSts 10000;
BA_ "GenSigSendType" SG_ 1123 AirBg_PassAirbgDeacSts 2;
BA_ "GenSigTimeoutTime" SG_ 1125 CRC_IVI_DrWndw_Cntr 10000;
BA_ "GenSigStartValue" SG_ 1125 CRC_IVI_DrWndw_Cntr 255;
BA_ "InvalidValue" SG_ 1125 AlvCtr_IVI_DrWndw_Cntr "15";
BA_ "GenSigTimeoutTime" SG_ 1125 AlvCtr_IVI_DrWndw_Cntr 10000;
BA_ "GenSigStartValue" SG_ 1125 AlvCtr_IVI_DrWndw_Cntr 15;
BA_ "InvalidValue" SG_ 1125 Pwd_DrvDoorUsrAgReq "127";
BA_ "GenSigTimeoutTime" SG_ 1125 Pwd_DrvDoorUsrAgReq 10000;
BA_ "GenSigSendType" SG_ 1125 Pwd_DrvDoorUsrAgReq 2;
BA_ "InvalidValue" SG_ 1125 Pwd_PassDoorUsrAgReq "127";
BA_ "GenSigTimeoutTime" SG_ 1125 Pwd_PassDoorUsrAgReq 10000;
BA_ "GenSigSendType" SG_ 1125 Pwd_PassDoorUsrAgReq 2;
BA_ "InvalidValue" SG_ 1125 CenLock_AudioVisualCfg "3";
BA_ "GenSigTimeoutTime" SG_ 1125 CenLock_AudioVisualCfg 10000;
BA_ "GenSigStartValue" SG_ 1125 CenLock_AudioVisualCfg 3;
BA_ "GenSigSendType" SG_ 1125 CenLock_AudioVisualCfg 2;
BA_ "InvalidValue" SG_ 1125 PwrSdSt_LeExtndRtractReq "3";
BA_ "GenSigTimeoutTime" SG_ 1125 PwrSdSt_LeExtndRtractReq 10000;
BA_ "GenSigSendType" SG_ 1125 PwrSdSt_LeExtndRtractReq 2;
BA_ "InvalidValue" SG_ 1125 PwrSdSt_RiExtndRtractReq "3";
BA_ "GenSigTimeoutTime" SG_ 1125 PwrSdSt_RiExtndRtractReq 10000;
BA_ "GenSigSendType" SG_ 1125 PwrSdSt_RiExtndRtractReq 2;
BA_ "InvalidValue" SG_ 1125 Pwind_WndwUpDwnUsrReq "3";
BA_ "GenSigTimeoutTime" SG_ 1125 Pwind_WndwUpDwnUsrReq 10000;
BA_ "GenSigSendType" SG_ 1125 Pwind_WndwUpDwnUsrReq 2;
BA_ "GenSigTimeoutTime" SG_ 1129 CRC_MFS_SwitchReq 10000;
BA_ "GenSigStartValue" SG_ 1129 CRC_MFS_SwitchReq 255;
BA_ "InvalidValue" SG_ 1129 AlvCtr_MFS_SwitchReq "15";
BA_ "GenSigTimeoutTime" SG_ 1129 AlvCtr_MFS_SwitchReq 10000;
BA_ "GenSigStartValue" SG_ 1129 AlvCtr_MFS_SwitchReq 15;
BA_ "InvalidValue" SG_ 1129 Mfsw_AdasScrlSwtReq "15";
BA_ "GenSigTimeoutTime" SG_ 1129 Mfsw_AdasScrlSwtReq 10000;
BA_ "GenSigStartValue" SG_ 1129 Mfsw_AdasScrlSwtReq 15;
BA_ "GenSigSendType" SG_ 1129 Mfsw_AdasScrlSwtReq 2;
BA_ "InvalidValue" SG_ 1129 Mfsw_ScrolSwtReq "15";
BA_ "GenSigTimeoutTime" SG_ 1129 Mfsw_ScrolSwtReq 10000;
BA_ "GenSigStartValue" SG_ 1129 Mfsw_ScrolSwtReq 15;
BA_ "GenSigSendType" SG_ 1129 Mfsw_ScrolSwtReq 2;
BA_ "InvalidValue" SG_ 1129 Mfsw_RimSwtWiperAcvnCmd "7";
BA_ "GenSigTimeoutTime" SG_ 1129 Mfsw_RimSwtWiperAcvnCmd 10000;
BA_ "GenSigStartValue" SG_ 1129 Mfsw_RimSwtWiperAcvnCmd 7;
BA_ "GenSigSendType" SG_ 1129 Mfsw_RimSwtWiperAcvnCmd 2;
BA_ "InvalidValue" SG_ 1129 Mfsw_WiperMenuReq "7";
BA_ "GenSigTimeoutTime" SG_ 1129 Mfsw_WiperMenuReq 10000;
BA_ "GenSigStartValue" SG_ 1129 Mfsw_WiperMenuReq 7;
BA_ "GenSigSendType" SG_ 1129 Mfsw_WiperMenuReq 2;
BA_ "InvalidValue" SG_ 1129 Mfsw_PaddSwtFavoSelReq "7";
BA_ "GenSigTimeoutTime" SG_ 1129 Mfsw_PaddSwtFavoSelReq 10000;
BA_ "GenSigStartValue" SG_ 1129 Mfsw_PaddSwtFavoSelReq 7;
BA_ "GenSigSendType" SG_ 1129 Mfsw_PaddSwtFavoSelReq 2;
BA_ "InvalidValue" SG_ 1129 Mfsw_PaddSwtGearShiftReq "7";
BA_ "GenSigTimeoutTime" SG_ 1129 Mfsw_PaddSwtGearShiftReq 10000;
BA_ "GenSigStartValue" SG_ 1129 Mfsw_PaddSwtGearShiftReq 7;
BA_ "GenSigSendType" SG_ 1129 Mfsw_PaddSwtGearShiftReq 2;
BA_ "InvalidValue" SG_ 1129 Mfsw_AdasSwtReq "3";
BA_ "GenSigTimeoutTime" SG_ 1129 Mfsw_AdasSwtReq 10000;
BA_ "GenSigStartValue" SG_ 1129 Mfsw_AdasSwtReq 3;
BA_ "GenSigSendType" SG_ 1129 Mfsw_AdasSwtReq 2;
BA_ "InvalidValue" SG_ 1129 Mfsw_VoiceSwtReq "7";
BA_ "GenSigTimeoutTime" SG_ 1129 Mfsw_VoiceSwtReq 10000;
BA_ "GenSigStartValue" SG_ 1129 Mfsw_VoiceSwtReq 7;
BA_ "GenSigSendType" SG_ 1129 Mfsw_VoiceSwtReq 2;
BA_ "InvalidValue" SG_ 1129 Mfsw_RimSwtHiBeamAcvnCmd "7";
BA_ "GenSigTimeoutTime" SG_ 1129 Mfsw_RimSwtHiBeamAcvnCmd 10000;
BA_ "GenSigStartValue" SG_ 1129 Mfsw_RimSwtHiBeamAcvnCmd 7;
BA_ "GenSigSendType" SG_ 1129 Mfsw_RimSwtHiBeamAcvnCmd 2;
BA_ "InvalidValue" SG_ 1129 Mfsw_DrvModSwtReq "7";
BA_ "GenSigTimeoutTime" SG_ 1129 Mfsw_DrvModSwtReq 10000;
BA_ "GenSigStartValue" SG_ 1129 Mfsw_DrvModSwtReq 7;
BA_ "GenSigSendType" SG_ 1129 Mfsw_DrvModSwtReq 2;
BA_ "InvalidValue" SG_ 1129 Mfsw_ParkSwtReq "7";
BA_ "GenSigTimeoutTime" SG_ 1129 Mfsw_ParkSwtReq 10000;
BA_ "GenSigStartValue" SG_ 1129 Mfsw_ParkSwtReq 7;
BA_ "GenSigSendType" SG_ 1129 Mfsw_ParkSwtReq 2;
BA_ "InvalidValue" SG_ 1129 Mfsw_FavoSwtReq "7";
BA_ "GenSigTimeoutTime" SG_ 1129 Mfsw_FavoSwtReq 10000;
BA_ "GenSigStartValue" SG_ 1129 Mfsw_FavoSwtReq 7;
BA_ "GenSigSendType" SG_ 1129 Mfsw_FavoSwtReq 2;
VAL_ 3221225472 IVI_CBV_ReptMsgBit_0 0 "False" 1 "True" ;
VAL_ 3221225472 IVI_CBV_NMCoordBit_3 0 "False" 1 "True" ;
VAL_ 3221225472 IVI_CBV_ActWakeBit_4 0 "No" 1 "Yes" ;
VAL_ 3221225472 IVI_CBV_PNIBit_6 0 "No" 1 "Yes" ;
VAL_ 3221225472 IVI_UDB_0 255 "NotAvailabe" ;
VAL_ 3221225472 IVI_UDB1_BStoRM_StBit_0 0 "No" 1 "Yes" ;
VAL_ 3221225472 IVI_UDB1_PBStoRM_StBit_1 0 "No" 1 "Yes" ;
VAL_ 3221225472 IVI_UDB1_RMtoNO_StBit_2 0 "No" 1 "Yes" ;
VAL_ 3221225472 IVI_UDB1_RStoNO_StBit_3 0 "No" 1 "Yes" ;
VAL_ 3221225472 IVI_UDB1_RStoRM_StBit_4 0 "No" 1 "Yes" ;
VAL_ 3221225472 IVI_UDB1_NOtoRM_StBit_5 0 "No" 1 "Yes" ;
VAL_ 3221225472 IVI_UDB1_NO_StBit_6 0 "No" 1 "Yes" ;
VAL_ 3221225472 IVI_UDB1_RM_StBit_7 0 "No" 1 "Yes" ;
VAL_ 3221225472 IVI_UDB2_IGN_WUPBit_0 0 "Inactive" 1 "Active" ;
VAL_ 3221225472 IVI_UDB2_RESET_WUPBit_1 0 "Inactive" 1 "Active" ;
VAL_ 3221225472 IVI_UDB2_NM_WUPBit_2 0 "Inactive" 1 "Active" ;
VAL_ 3221225472 IVI_UDB2_ECUSPEC_WUPBit_3 0 "Inactive" 1 "Active" ;
VAL_ 3221225472 IVI_UDB2_NM_AWAKEBit_4 0 "Inactive" 1 "Active" ;
VAL_ 3221225472 IVI_UDB2_IGN_AWAKEBit_5 0 "Inactive" 1 "Active" ;
VAL_ 3221225472 IVI_UDB2_DIAG_AWAKEBit_6 0 "Inactive" 1 "Active" ;
VAL_ 3221225472 IVI_UDB2_ECUSPEC_AWAKEBit_7 0 "Inactive" 1 "Active" ;
VAL_ 3221225472 ZCUF_CBV_ReptMsgBit_0 0 "False" 1 "True" ;
VAL_ 3221225472 ZCUF_CBV_NMCoordBit_3 0 "False" 1 "True" ;
VAL_ 3221225472 ZCUF_CBV_ActWakeBit_4 0 "No" 1 "Yes" ;
VAL_ 3221225472 ZCUF_CBV_PNIBit_6 0 "No" 1 "Yes" ;
VAL_ 3221225472 ZCUF_UDB_0 255 "NotAvailabe" ;
VAL_ 3221225472 ZCUF_UDB1_BStoRM_StBit_0 0 "No" 1 "Yes" ;
VAL_ 3221225472 ZCUF_UDB1_PBStoRM_StBit1 0 "No" 1 "Yes" ;
VAL_ 3221225472 ZCUF_UDB1_RMtoNO_StBit_2 0 "No" 1 "Yes" ;
VAL_ 3221225472 ZCUF_UDB1_RStoNO_StBit_3 0 "No" 1 "Yes" ;
VAL_ 3221225472 ZCUF_UDB1_RStoRM_StBit_4 0 "No" 1 "Yes" ;
VAL_ 3221225472 ZCUF_UDB1_NOtoRM_StBit_5 0 "No" 1 "Yes" ;
VAL_ 3221225472 ZCUF_UDB1_NO_StBit_6 0 "No" 1 "Yes" ;
VAL_ 3221225472 ZCUF_UDB1_RM_StBit_7 0 "No" 1 "Yes" ;
VAL_ 3221225472 ZCUF_UDB2_IGN_WUPBit_0 0 "Inactive" 1 "Active" ;
VAL_ 3221225472 ZCUF_UDB2_RESET_WUPBit_1 0 "Inactive" 1 "Active" ;
VAL_ 3221225472 ZCUF_UDB2_NM_WUPBit_2 0 "Inactive" 1 "Active" ;
VAL_ 3221225472 ZCUF_UDB2_ECUSPEC_WUPBit_3 0 "Inactive" 1 "Active" ;
VAL_ 3221225472 ZCUF_UDB2_NM_AWAKEBit_4 0 "Inactive" 1 "Active" ;
VAL_ 3221225472 ZCUF_UDB2_IGN_AWAKEBit_5 0 "Inactive" 1 "Active" ;
VAL_ 3221225472 ZCUF_UDB2_DIAG_AWAKEBit_6 0 "Inactive" 1 "Active" ;
VAL_ 3221225472 ZCUF_UDB2_ECUSPEC_AWKEBit7 0 "Inactive" 1 "Active" ;
VAL_ 99 AlvCtr_ACM_CrashStat 15 "Invalid Value" ;
VAL_ 99 Airbg_CrashSts 0 "No_Crash" 1 "Crash" 2 "Error" 3 "NotAvailable" ;
VAL_ 102 AlvCtr_EPS_SFA_SteerWhl_Pub_Info 15 "Invalid Value" ;
VAL_ 102 Stbwr_SfaSteerWhlTq 4094 "Error" 4095 "Not Available" ;
VAL_ 102 Stbwr_SfaEmgcyReq 0 "Inactive" 1 "Active" 2 "Error" 3 "NotAvailable" ;
VAL_ 102 Stbwr_SfaSteerWhlAg 65534 "Error" 65535 "Not Available" ;
VAL_ 102 Stbwr_TunSts 0 "Normal mode" 1 "ECO mode" 2 "Sport mode" 3 "ECO+ Mode" 4 "Sport+ Mode" 5 "Sand Mode" 6 "Error" 7 "NotAvailable" ;
VAL_ 102 Stbwr_CentrgSts 0 "SteeringAligned" 1 "AlignmentNeeded" 2 "CenteringNeeded" 3 "Reserved" 4 "Reserved" 5 "Reserved" 6 "Error" 7 "NotAvailable" ;
VAL_ 102 Stbwr_SfaCtlMode 0 "INT_STANDBY" 1 "INT_RWA_ALIGN" 2 "INT_SFA_ALIGN" 3 "INT_SELFCTRG" 4 "INT_ALIGN_CMPL" 5 "INT_NORMAL" 6 "INT_SOFTLOCK" 7 "INT_SOFTLOCK_ALIGND" 8 "Reserved" 9 "Reserved" 10 "Reserved" 11 "Reserved" 12 "Reserved" 13 "Reserved" 14 "Error" 15 "Not Available" ;
VAL_ 118 ReWhlSteer_MeasdStkVal 65534 "Error" 65535 "Not Available" ;
VAL_ 118 ReWhlSteer_Sts 0 "Inactive" 1 "Active" 2 "Error" 3 "NotAvailable" ;
VAL_ 119 Bms_BatPreCdnSts 0 "PreconditionOFF/Default" 1 "LowTemperaturePreconditionON" 2 "HighTemperaturePreconditionON" 3 "NotAvailable" ;
VAL_ 128 Stbwr_RwaPinionAg 65534 "Error" 65535 "Not Available" ;
VAL_ 128 Stbwr_RwaPinionAgSpd 4094 "Error" 4095 "Not Available" ;
VAL_ 128 Stbwr_RwaRackPosn 1048574 "Error" 1048575 "Not Available" ;
VAL_ 160 AlvCtr_EBCM_Veh_Info 15 "Invalid Value" ;
VAL_ 160 Abs_ActVehSpd 65534 "Error" 65535 "Not Available" ;
VAL_ 211 AlvCtr_ZCUF_Clamp_Info 15 "Invalid Value" ;
VAL_ 211 Clmmg_VehSt 0 "Vehicle_Parked" 1 "Vehicle_Alive" 2 "Vehicle_Entry" 3 "Vehicle_Driving" 4 "VehicleUpgrade" 5 "Reserved" 6 "Reserved" 7 "Reserved" 8 "Reserved" 9 "Reserved" 10 "Reserved" 11 "Reserved" 12 "Reserved" 13 "Reserved" 14 "Reserved" 15 "NotAvailable" ;
VAL_ 211 Clmmg_CL15_L 0 "Off" 1 "On" 2 "Error" 3 "NotAvailable" ;
VAL_ 211 Clmmg_CL30S_L 0 "Off" 1 "On" 2 "Error" 3 "NotAvailable" ;
VAL_ 211 Lvm_LoaShedReq 0 "NotRequested" 1 "Requested" 2 "Reserved" 3 "NotAvailable" ;
VAL_ 223 AirSuspUnit_HeiFL 4094 "Error" 4095 "Not Available" ;
VAL_ 223 AirSuspUnit_HeiFR 4094 "Error" 4095 "Not Available" ;
VAL_ 223 AirSuspUnit_HeiRR 4094 "Error" 4095 "Not Available" ;
VAL_ 223 AirSuspUnit_HeiRL 4094 "Error" 4095 "Not Available" ;
VAL_ 223 AirSuspUnit_HeiSts 0 "Nominal" 1 "Low" 2 "High" 3 "Reserved" 4 "Reserved" 5 "Reserved" 6 "Error" 7 "NotAvailable" ;
VAL_ 223 AirSuspUnit_CdcModeSts 0 "Soft1" 1 "Soft2" 2 "Hard1" 3 "Hard2" 4 "Reserved" 5 "Reserved" 6 "Error" 7 "NotAvailable" ;
VAL_ 223 AirSuspUnit_IngrsModAck 0 "NotAcknowledged" 1 "Acknowledged" 2 "Reserved" 3 "NotAvailable" ;
VAL_ 223 AirSuspUnit_SprgModeSts 0 "Low" 1 "High" 2 "Reserved" 3 "Reserved" 4 "Reserved" 5 "Reserved" 6 "Error" 7 "NotAvailable" ;
VAL_ 223 AirSuspUnit_CmprSts 0 "Ready" 1 "Running" 2 "Reserved" 3 "Reserved" 4 "Reserved" 5 "Reserved" 6 "Error" 7 "NotAvailable" ;
VAL_ 223 AirSuspUnit_SrvModeSts 0 "Disabled" 1 "Enabled" 2 "Error" 3 "NotAvailable" ;
VAL_ 223 AirSuspUnit_AirTankP 254 "Error" 255 "Not Available" ;
VAL_ 223 AirSuspUnit_Sts 0 "Available" 1 "Degradation State" 2 "Reserved" 3 "Reserved" 4 "Reserved" 5 "Reserved" 6 "Error" 7 "NotAvailable" ;
VAL_ 279 Fschg_DcChgGunIn 0 "Disconnect" 1 "Connected" 2 "Error" 3 "NotAvailable" ;
VAL_ 279 Acchg_AcChgGunIn 0 "Disconnect" 1 "Connected" 2 "Error" 3 "NotAvailable" ;
VAL_ 285 AlvCtr_VCU_HVDrvSys_Status 15 "Invalid Value" ;
VAL_ 285 Drvmc_ActDrvMode 0 "EcoPlus" 1 "Eco" 2 "Normal
" 3 "Sport" 4 "SportsPlus" 5 "Sand_Off
" 6 "Reserve" 7 "NotAvailable" ;
VAL_ 285 Enmgt_HvDrvSysSts 0 "NotAvailable" 1 "Normal" 2 "Degradation" 3 "LimpHome" 4 "Reserve" 5 "Reserve" 6 "Error" 7 "NotAvailable" ;
VAL_ 285 Drvmc_ActDrvModeVld 0 "Invalid " 1 "Valid" 2 "Error" 3 "NotAvailable" ;
VAL_ 285 Eshift_ActGear 0 "Park" 1 "Reverse" 2 "Neutral" 3 "Drive" 4 "Reserved" 5 "Reserved" 6 "Error" 7 "NotAvailable" ;
VAL_ 304 AlvCtr_EBCM_Sts_Req 15 "Invalid Value" ;
VAL_ 304 Abs_IntvSts 0 "Inactive" 1 "Active" 2 "Error" 3 "NotAvailable" ;
VAL_ 304 Drvac_TcsAvl 0 "Available" 1 "Reserved" 2 "Error" 3 "NotAvailable" ;
VAL_ 304 Drvac_FldLvlIndcrBrkFldSts 0 "Minimum" 1 "Nominal" 2 "Error" 3 "NotAvailable" ;
VAL_ 304 Ecpbk_BrkLiOnReq 0 "NoRequest" 1 "RequestedBrakeLightOFF" 2 "Requested Brake light ON" 3 "NotAvailable" ;
VAL_ 304 Ebd_SysSts 0 "Inactive" 1 "Active" 2 "Error" 3 "NotAvailable" ;
VAL_ 304 Drvac_HdcSts 0 "Inactive" 1 "Active" 2 "Error" 3 "NotAvailable" ;
VAL_ 304 Drvac_TcsSts 0 "Inactive" 1 "Active" 2 "Error" 3 "NotAvailable" ;
VAL_ 304 Drvac_CorneringBrkCtlSts 0 "Inactive" 1 "Active" 2 "Error" 3 "NotAvailable" ;
VAL_ 304 Drvac_HillStrtAssiSts 0 "Inactive" 1 "Active" 2 "Error" 3 "NotAvailable" ;
VAL_ 304 Ecpbk_Sts 0 "Released" 1 "Applied" 2 "DynamicBraking" 3 "Fault" 4 "Warning" 5 "Reserved" 6 "Error" 7 "NotAvailable" ;
VAL_ 317 AlvCtr_SBM_LVBatInfo_1 15 "Invalid Value" ;
VAL_ 317 Sbm_LvBatThermRunawy 0 "No_Warning" 1 "Warning" 2 "Reserved" 3 "NotAvailable" ;
VAL_ 318 Sbm_CriticalSoCAlert 0 "NoFault" 1 "Level1Fault" 2 "Level2Fault" 3 "Level3Fault" 4 "Start" 5 "Reserved" 6 "Reserved" 7 "Reserved" 8 "Reserved" 9 "Reserved" 10 "Reserved" 11 "Reserved" 12 "Reserved" 13 "Reserved" 14 "Reserved" 15 "NotAvailable" ;
VAL_ 349 Acchg_AcChgSts 0 "ChargingNotInProgress" 1 "ChargingInProgress" 2 "ChargingComplete" 3 "ChargeFault" 4 "GunPluggedInStandby" 5 "GunPluggedIn_Waiting" 6 "Preconditioning" 7 "NotAvailable" ;
VAL_ 349 Awd_ActWhlDrvMode 0 "Reserved" 1 "RWD" 2 "FWD" 3 "AWD" 4 "Reserved" 5 "Reserved" 6 "Reserved" 7 "NotAvailable" ;
VAL_ 349 Cregb_CoastRgnLvlIndcr 0 "Level0" 1 "Level1" 2 "Level2" 3 "Level3" 4 "Reserved" 5 "Reserved" 6 "Reserved" 7 "NotAvailable" ;
VAL_ 349 Fschg_VehChrgnSts 0 "ChargingNotInProgress" 1 "ChargingInProgress" 2 "ChargingComplete" 3 "ChargeFault" 4 "GunPluggedInStandby" 5 "GunPluggedIn_Waiting" 6 "Preconditioning" 7 "NotAvailable" ;
VAL_ 349 Eshift_ChngGearFromPark 0 "No_Warning" 1 "Warning" 2 "Reserved" 3 "NotAvailable" ;
VAL_ 349 Fschg_ChgGunLockSts 0 "Unlock" 1 "Lock" 2 "Error" 3 "NotAvailable" ;
VAL_ 349 Awd_ActWhlDrvModeVld 0 "Invalid " 1 "Valid" 2 "Error" 3 "NotAvailable" ;
VAL_ 367 AlvCtr_ZCUF_RlhsLight_Info 15 "Invalid Value" ;
VAL_ 371 Hdlamp_LeLoBeamLampSts 0 "Off" 1 "On" 2 "Error" 3 "NotAvailable" ;
VAL_ 371 Hdlamp_LeHiBeamLampSts 0 "Off" 1 "On" 2 "Flash" 3 "Reserved" 4 "Reserved" 5 "Reserved" 6 "Error" 7 "NotAvailable" ;
VAL_ 377 Hdlamp_RiLoBeamLampSts 0 "Off" 1 "On" 2 "Error" 3 "NotAvailable" ;
VAL_ 377 Hdlamp_RiHiBeamLampSts 0 "Off" 1 "On" 2 "Flash" 3 "Reserved" 4 "Reserved" 5 "Reserved" 6 "Error" 7 "NotAvailable" ;
VAL_ 383 Hdlamp_LeFrntPosnLampSts 0 "Off" 1 "On" 2 "Error" 3 "NotAvailable" ;
VAL_ 383 Hdlamp_LeDRLLampSts 0 "Off" 1 "On" 2 "Error" 3 "NotAvailable" ;
VAL_ 383 Hdlamp_FrntLeBodyTurnIndcrSts 0 "Off" 1 "On" 2 "Flash" 3 "Reserved" 4 "Reserved" 5 "Reserved" 6 "Error" 7 "NotAvailable" ;
VAL_ 387 Hdlamp_RiFrntPosnLampSts 0 "Off" 1 "On" 2 "Error" 3 "NotAvailable" ;
VAL_ 387 Hdlamp_RiDRLLampSts 0 "Off" 1 "On" 2 "Error" 3 "NotAvailable" ;
VAL_ 387 Hdlamp_FrntRiBodyTurnIndcrSts 0 "Off" 1 "On" 2 "Flash" 3 "Reserved" 4 "Reserved" 5 "Reserved" 6 "Error" 7 "NotAvailable" ;
VAL_ 393 Relamp_LeBodyBrkLampSts 0 "Off" 1 "On" 2 "Error" 3 "NotAvailable" ;
VAL_ 393 Relamp_ReLeBodyPosnLampSts 0 "Off" 1 "On" 2 "Error" 3 "NotAvailable" ;
VAL_ 393 Relamp_ReLeBodyTurnIndcrSts 0 "Off" 1 "On" 2 "Flash" 3 "Reserved" 4 "Reserved" 5 "Reserved" 6 "Error" 7 "NotAvailable" ;
VAL_ 399 Relamp_RiBodyBrkLampSts 0 "Off" 1 "On" 2 "Error" 3 "NotAvailable" ;
VAL_ 399 Relamp_ReRiBodyPosnLampSts 0 "Off" 1 "On" 2 "Error" 3 "NotAvailable" ;
VAL_ 399 Relamp_ReRiBodyTurnIndcrSts 0 "Off" 1 "On" 2 "Flash" 3 "Reserved" 4 "Reserved" 5 "Reserved" 6 "Error" 7 "NotAvailable" ;
VAL_ 403 Relamp_LeTLGBrkLampSts 0 "Off" 1 "On" 2 "Error" 3 "NotAvailable" ;
VAL_ 403 Relamp_ReLeTLGPosnLampSts 0 "Off" 1 "On" 2 "Error" 3 "NotAvailable" ;
VAL_ 403 Relamp_ReLeTLGTurnIndcrSts 0 "Off" 1 "On" 2 "Flash" 3 "Reserved" 4 "Reserved" 5 "Reserved" 6 "Error" 7 "NotAvailable" ;
VAL_ 409 Hdlamp_FrntCentr_LeSignLampSts 0 "Off" 1 "On" 2 "Error" 3 "NotAvailable" ;
VAL_ 409 Hdlamp_FrntCentr_RiSignLampSts 0 "Off" 1 "On" 2 "Error" 3 "NotAvailable" ;
VAL_ 410 Relamp_FrntCentr_LeSignLampSts 0 "Off" 1 "On" 2 "Error" 3 "NotAvailable" ;
VAL_ 410 Relamp_FrntCentr_RiSignLampSts 0 "Off" 1 "On" 2 "Error" 3 "NotAvailable" ;
VAL_ 415 Relamp_RiTLGBrkLampSts 0 "Off" 1 "On" 2 "Error" 3 "NotAvailable" ;
VAL_ 415 Relamp_ReRiTLGPosnLampSts 0 "Off" 1 "On" 2 "Error" 3 "NotAvailable" ;
VAL_ 415 Relamp_ReRiTLGTurnIndcrSts 0 "Off" 1 "On" 2 "Flash" 3 "Reserved" 4 "Reserved" 5 "Reserved" 6 "Error" 7 "NotAvailable" ;
VAL_ 419 Ccsf_AgsOpenReq 0 "Unlock" 1 "Lock" 2 "Reserved" 3 "NotAvailable" ;
VAL_ 425 AlvCtr_CCU_TemperatureFbk 15 "Invalid Value" ;
VAL_ 431 AlvCtr_ZCUF_RlhsRainHumidity_Inf 15 "Invalid Value" ;
VAL_ 431 Rlhs_RainFallSts 0 "No_Rain" 1 "Light_Rain" 2 "Moderate_Rain" 3 "Heavy_Rain" 4 "Reserved" 5 "Reserved" 6 "Error" 7 "NotAvailable" ;
VAL_ 740 Rvc_ReBlindSpot_Sts 0 "REAR_BLIND_SPOT_CLEAR" 1 "REAR_BLIND_SPOT_OBST" 6 "REAR_BLIND_SPOT_ERROR" 7 "REAR_BLIND_SPOT_SNA" ;
VAL_ 869 IVI_Acchr_chrggunUnlck_cmd 0 "Unlock" 1 "Lock" 2 "Reserved" 3 "NotAvailable" ;
VAL_ 869 Acchg_IviChgStopReq 0 "Off" 1 "On" 2 "Error" 3 "NotAvailable" ;
VAL_ 869 Acchg_PeakHourMngtEna 0 "Disable" 1 "Enable" 2 "Reserved" 3 "Not Available" ;
VAL_ 869 Acchg_IviEnaSdleChrgn 0 "Off" 1 "On" 2 "Error" 3 "NotAvailable" ;
VAL_ 869 Awd_WhlDrvModeSeln 0 "RWD" 1 "AWD" 2 "Reserved" 3 "NotAvailable" ;
VAL_ 869 Eshift_TowMode_Req 0 "Deactivated" 1 "Activated" 2 "Error" 3 "NotAvailable" ;
VAL_ 869 Drvmc_ValetModeAcvnSts 0 "Inactive" 1 "Active" 2 "Error" 3 "NotAvailable" ;
VAL_ 869 Drvmc_WashModeAcvnSts 0 "Inactive" 1 "Active" 2 "Error" 3 "NotAvailable" ;
VAL_ 869 Dtqmt_SrvModeSpdLim 65534 "Error" 65535 "Not Available" ;
VAL_ 869 Drvmc_ShowroomModeAcvnSts 0 "Inactive" 1 "Active" 2 "Error" 3 "NotAvailable" ;
VAL_ 869 Dtqmt_SrvSpdOvrrEna 0 "Off" 1 "On" 2 "Error" 3 "NotAvailable" ;
VAL_ 869 Drvmc_TrsptModeAcvnSts 0 "Inactive" 1 "Active" 2 "Error" 3 "NotAvailable" ;
VAL_ 869 Dtqmt_ValetModeSpdLim 65534 "Error" 65535 "Not Available" ;
VAL_ 869 Drvmc_DrvModeSelnReq 0 "EcoPlus" 1 "Eco" 2 "Normal
" 3 "Sport" 4 "SportsPlus" 5 "Sand_Off
" 6 "Reserve" 7 "NotAvailable" ;
VAL_ 869 Cregb_RegenLvl_Req 0 "Level0" 1 "Level1" 2 "Level2" 3 "Level3" 4 "Reserved" 5 "Reserved" 6 "Reserved" 7 "NotAvailable" ;
VAL_ 873 Acttg_TailGateSts 0 "Opening" 1 "Opened" 2 "Closing" 3 "Closed" 4 "Intermediate" 5 "ObstacleDetected" 6 "AntipinchDetected" 7 "BasicPositionStored" 8 "MechanicalEndPositionLearned" 9 "RequestRejected" 10 "VehicleSpeedThresholdCrossed" 11 "Reserved" 12 "Reserved" 13 "Reserved" 14 "Error" 15 "NotAvailable" ;
VAL_ 873 Acttg_TailGateNmlznSts 0 "Denormalised" 1 "Normalised" 2 "Learning" 3 "NotAvailable" ;
VAL_ 873 Acttg_TailGateAjarSts 0 "Open" 1 "Closed" 2 "Error" 3 "NotAvailable" ;
VAL_ 873 SeatCfmt_ReLeVentnSts 0 "Off" 1 "Low" 2 "Medium" 3 "High" 4 "Reserved" 5 "Reserved" 6 "Reserved" 7 "Invalid" ;
VAL_ 873 SeatCfmt_ReRiVentnSts 0 "Off" 1 "Low" 2 "Medium" 3 "High" 4 "Reserved" 5 "Reserved" 6 "Reserved" 7 "Invalid" ;
VAL_ 873 SeatCfmt_ReLeVentnCshnFanFailSts 0 "Normal" 1 "Faulty" 2 "Reserved" 3 "NotAvailable" ;
VAL_ 873 SeatCfmt_ReLeVentnSqubFanFailSts 0 "Normal" 1 "Faulty" 2 "Reserved" 3 "NotAvailable" ;
VAL_ 873 SeatCfmt_ReRiVentnCshnFanFailSts 0 "Normal" 1 "Faulty" 2 "Reserved" 3 "NotAvailable" ;
VAL_ 873 SeatCfmt_ReRiVentnSqubFanFailSts 0 "Normal" 1 "Faulty" 2 "Reserved" 3 "NotAvailable" ;
VAL_ 873 ChrgrPort_LockUnlck_Sts 0 "Unlock" 1 "Lock" 2 "Error" 3 "NotAvailable" ;
VAL_ 873 ChrgrPort_Ajar_Sts 0 "Open" 1 "Closed" 2 "Error" 3 "NotAvailable" ;
VAL_ 873 Relamp_RiLicePlateSts 0 "Off" 1 "On" 2 "Error" 3 "NotAvailable" ;
VAL_ 873 Relamp_LeLicePlateSts 0 "Off" 1 "On" 2 "Error" 3 "NotAvailable" ;
VAL_ 873 Relamp_FogLampSts 0 "Off" 1 "On" 2 "Error" 3 "NotAvailable" ;
VAL_ 873 Relamp_ChmslSts 0 "Off" 1 "On" 2 "Error" 3 "NotAvailable" ;
VAL_ 873 Relamp_RevLmpSts 0 "Off" 1 "On" 2 "Error" 3 "NotAvailable" ;
VAL_ 883 AlvCtr_CCU_FaultSts 15 "Invalid Value" ;
VAL_ 883 Ccsf_FrntBlowrFltSts 0 "NoFault" 1 "OpenCircuit" 2 "ShortToPower" 3 "OverCurrent" 4 "OverTemperature" 5 "Reserved" 6 "Reserved" 7 "NotAvailable" ;
VAL_ 883 Ccsr_ReBlowrFltSts 0 "NoFault" 1 "OpenCircuit" 2 "ShortToPower" 3 "OverCurrent" 4 "OverTemperature" 5 "Reserved" 6 "Reserved" 7 "NotAvailable" ;
VAL_ 883 Ccsf_IoniserFltSts 0 "Normal" 1 "Faulty" 2 "Reserved" 3 "NotAvailable" ;
VAL_ 883 Ccsf_FragnConnLoss 0 "Normal" 1 "Faulty" 2 "Reserved" 3 "NotAvailable" ;
VAL_ 883 Ccsf_FrgrncFltSts 0 "Normal" 1 "Faulty" 2 "Reserved" 3 "NotAvailable" ;
VAL_ 883 Ccsf_IoniserConnLoss 0 "Normal" 1 "Faulty" 2 "Reserved" 3 "NotAvailable" ;
VAL_ 883 Ccsf_DemistFlapFltSts 0 "Normal" 1 "OpenCircuit" 2 "ShortToPower" 3 "ShortToGround" 4 "Reserved" 5 "Reserved" 6 "Error" 7 "NotAvailable" ;
VAL_ 889 AlvCtr_CCU_ClimSys_Sts 15 "Invalid Value" ;
VAL_ 889 Ccsf_AirModeSelnFb 0 "Face" 1 "FaceFoot" 2 "Foot" 3 "FootSideWindowDemist" 4 "SideWindowDemist" 5 "DiffuseAmbient" 6 "DiffuseAmbientFace" 7 "NotAvailable" ;
VAL_ 889 Ccsf_FrntBlowrLvlFb 0 "Level0" 1 "Level1" 2 "Level2" 3 "Level3" 4 "Level4" 5 "Level5" 6 "Error" 7 "NotAvailable" ;
VAL_ 889 Ccsf_IoniserOnOffSts 0 "Off" 1 "On" 2 "Error" 3 "NotAvailable" ;
VAL_ 889 Ccsf_DrvrDemistRcmn 0 "Not_Requested" 1 "Requested" 2 "Error" 3 "NotAvailable" ;
VAL_ 889 Ccsr_ReBlowrLvlFb 0 "Level0" 1 "Level1" 2 "Level2" 3 "Level3" 4 "Level4" 5 "Level5" 6 "Error" 7 "NotAvailable" ;
VAL_ 889 Ccsf_CenLeVenDirSts 0 "NormallyOutwards" 1 "HarmonicsUpDown" 2 "HarmonicsSideBySide" 3 "NotAvailable" ;
VAL_ 889 Ccsf_CenRiVenDirSts 0 "NormallyOutwards" 1 "HarmonicsUpDown" 2 "HarmonicsSideBySide" 3 "NotAvailable" ;
VAL_ 889 Ccsf_AirQlyIdx 0 "PureAir" 1 "PollutionLevel1" 2 "PollutionLevel2" 3 "PollutionLevel3" 4 "PollutionLevel4" 5 "PollutionLevel5" 6 "PollutionLevel6" 7 "PollutionLevel7" 8 "PollutionLevel8" 9 "PollutionLevel9" 10 "PollutionLevel10" 11 "Reserve" 12 "Reserve" 13 "FailureMode" 14 "InitialMode" 15 "NotAvailable" ;
VAL_ 889 Ccsf_RclModFb 0 "Off" 1 "On" 2 "Error" 3 "NotAvailable" ;
VAL_ 895 AlvCtr_CCU_AcOpMode_Sts 15 "Invalid Value" ;
VAL_ 895 Ccsf_AcAutoModeSts 0 "Off" 1 "On" 2 "Error" 3 "NotAvailable" ;
VAL_ 895 Caclh_AcLowPwrModeSts 0 "Off" 1 "On" 2 "Error" 3 "NotAvailable" ;
VAL_ 895 Ccsf_DemistDefrstSts 0 "Off" 1 "On" 2 "Error" 3 "NotAvailable" ;
VAL_ 895 Ccsf_FrntAcOnOffSts 0 "Off" 1 "On" 2 "Error" 3 "NotAvailable" ;
VAL_ 895 Caclh_FrntAcOpModeSts 0 "ACOff" 1 "ACCoolingOn" 2 "ACHeatingOn" 3 "ACCoolingFault" 4 "ACHeatingFault" 5 "ACLowPowerOperation" 6 "ACOffBlowerFault" 7 "NotAvailable" ;
VAL_ 895 Caclh_ReAcOpModeSts 0 "ACOff" 1 "ACCoolingOn" 2 "ACCoolingFault" 3 "ACLowPowerOperation" 4 "ACOffBlowerFault" 5 "Reserved" 6 "Reserved" 7 "NotAvailable" ;
VAL_ 895 Ccsr_ReAcOnOffSts 0 "Off" 1 "On" 2 "Error" 3 "NotAvailable" ;
VAL_ 899 AlvCtr_CCU_ClimFrgrnc_Sts 15 "Invalid Value" ;
VAL_ 899 Ccsf_FrgrncOnOffSts 0 "Off" 1 "On" 2 "Error" 3 "NotAvailable" ;
VAL_ 899 Ccsf_FrgrncSelnSts 0 "FragranceSlot1" 1 "FragranceSlot2" 2 "FragranceSlot3" 3 "FragranceSlot4" 4 "Reserved" 5 "Reserved" 6 "Error" 7 "NotAvailable" ;
VAL_ 911 AlvCtr_PSMD_SeatAdjmt_Sts 15 "Invalid Value" ;
VAL_ 911 SeatAdjmt_DrvLumInOutPosn 0 "NoRequest" 1 "In" 2 "Out" 3 "Error" ;
VAL_ 911 SeatAdjmt_DrvLumUpDwnPosn 0 "FullyUp" 1 "Intermediate" 2 "FullyDown" 3 "Denormalised" 4 "ObstacleDetected" 5 "Reserved" 6 "Error" 7 "NotAvailable" ;
VAL_ 911 SeatAdjmt_DrvLumSysFailSts 0 "Normal" 1 "Faulty" 2 "Reserved" 3 "NotAvailable" ;
VAL_ 911 SeatAdjmt_DrvHeiUpDwnMotSts 0 "FullyUp" 1 "Intermediate" 2 "FullyDown" 3 "Denormalised" 4 "ObstacleDetected" 5 "Reserved" 6 "Error" 7 "NotAvailable" ;
VAL_ 911 SeatAdjmt_DrvReclUpDwnMotSts 0 "FullyUp" 1 "Intermediate" 2 "FullyDown" 3 "Denormalised" 4 "ObstacleDetected" 5 "Reserved" 6 "Error" 7 "NotAvailable" ;
VAL_ 911 SeatAdjmt_DrvAdjmtSts 0 "InProgress" 1 "Completed" 2 "Error" 3 "NotAvailable" ;
VAL_ 911 SeatAdjmt_DrvFrntBackMotSts 0 "FullyForward" 1 "Intermediate" 2 "FullyBackward" 3 "Denormalised" 4 "ObstacleDetected" 5 "Reserved" 6 "Error" 7 "NotAvailable" ;
VAL_ 911 SeatAdjmt_DrvTiltUpDwnMotSts 0 "FullyUp" 1 "Intermediate" 2 "FullyDown" 3 "Denormalised" 4 "ObstacleDetected" 5 "Reserved" 6 "Error" 7 "NotAvailable" ;
VAL_ 915 AlvCtr_PSMP_SeatAdjmt_Sts 15 "Invalid Value" ;
VAL_ 915 SeatAdjmt_PassLumInOutPosn 0 "NoRequest" 1 "In" 2 "Out" 3 "Error" ;
VAL_ 915 SeatAdjmt_PassLumUpDownPosn 0 "FullyUp" 1 "Intermediate" 2 "FullyDown" 3 "Denormalised" 4 "ObstacleDetected" 5 "Reserved" 6 "Error" 7 "NotAvailable" ;
VAL_ 915 SeatAdjmt_PassLumSysFailSts 0 "Normal" 1 "Faulty" 2 "Reserved" 3 "NotAvailable" ;
VAL_ 915 SeatAdjmt_PassReclUpDwnMotSts 0 "FullyUp" 1 "Intermediate" 2 "FullyDown" 3 "Denormalised" 4 "ObstacleDetected" 5 "Reserved" 6 "Error" 7 "NotAvailable" ;
VAL_ 915 SeatAdjmt_PassHeiUpDwnMotSts_ 0 "FullyUp" 1 "Intermediate" 2 "FullyDown" 3 "Denormalised" 4 "ObstacleDetected" 5 "Reserved" 6 "Error" 7 "NotAvailable" ;
VAL_ 915 SeatAdjmt_PassAdjmtSts 0 "InProgress" 1 "Completed" 2 "Error" 3 "NotAvailable" ;
VAL_ 915 SeatAdjmt_PassFowdBawdMotSts 0 "FullyForward" 1 "Intermediate" 2 "FullyBackward" 3 "Denormalised" 4 "ObstacleDetected" 5 "Reserved" 6 "Error" 7 "NotAvailable" ;
VAL_ 915 SeatAdjmt_PassTiltUpDwnMotSts 0 "FullyUp" 1 "Intermediate" 2 "FullyDown" 3 "Denormalised" 4 "ObstacleDetected" 5 "Reserved" 6 "Error" 7 "NotAvailable" ;
VAL_ 921 AlvCtr_PSMD_SeatPos_Status 15 "Invalid Value" ;
VAL_ 927 AlvCtr_PSMD_SeatCmfrt_Status 15 "Invalid Value" ;
VAL_ 927 SeatCfmt_DrvHeatgSts 0 "Off" 1 "Low" 2 "Medium" 3 "High" 4 "Reserved" 5 "Reserved" 6 "Reserved" 7 "Invalid" ;
VAL_ 927 SeatCfmt_DrvVentnSts 0 "Off" 1 "Low" 2 "Medium" 3 "High" 4 "Reserved" 5 "Reserved" 6 "Reserved" 7 "Invalid" ;
VAL_ 927 SeatCfmt_DrvVentnCshnFanFailSts 0 "Normal" 1 "Faulty" 2 "Reserved" 3 "NotAvailable" ;
VAL_ 927 SeatCfmt_DrvHeatgBackPadFailSts 0 "Normal" 1 "Faulty" 2 "Reserved" 3 "NotAvailable" ;
VAL_ 927 SeatCfmt_DrvMassgFailSts 0 "Normal" 1 "Faulty" 2 "Reserved" 3 "NotAvailable" ;
VAL_ 927 SeatCfmt_DrvHeatgCshnPadFailSts 0 "Normal" 1 "Faulty" 2 "Reserved" 3 "NotAvailable" ;
VAL_ 927 SeatCfmt_DrvMassg_Sts 0 "Off" 1 "On" 2 "Error" 3 "NotAvailable" ;
VAL_ 927 SeatCfmt_DrvVentnSqubFanFailSts 0 "Normal" 1 "Faulty" 2 "Reserved" 3 "NotAvailable" ;
VAL_ 931 AlvCtr_PSMP_SeatCmfrt_Status 15 "Invalid Value" ;
VAL_ 931 SeatCfmt_PassVentnSts 0 "Off" 1 "Low" 2 "Medium" 3 "High" 4 "Reserved" 5 "Reserved" 6 "Reserved" 7 "Invalid" ;
VAL_ 931 SeatCfmt_PassHeatgSts 0 "Off" 1 "Low" 2 "Medium" 3 "High" 4 "Reserved" 5 "Reserved" 6 "Reserved" 7 "Invalid" ;
VAL_ 931 SeatCfmt_PassMassgSts 0 "Off" 1 "On" 2 "Error" 3 "NotAvailable" ;
VAL_ 931 SeatCfmt_PassVentnSqubFanFailSts 0 "Normal" 1 "Faulty" 2 "Reserved" 3 "NotAvailable" ;
VAL_ 931 SeatCfmt_PassMassgFailSts 0 "Normal" 1 "Faulty" 2 "Reserved" 3 "NotAvailable" ;
VAL_ 931 SeatCfmt_PassVentnCshnFanFailSts 0 "Normal" 1 "Faulty" 2 "Reserved" 3 "NotAvailable" ;
VAL_ 931 SeatCfmt_PassHeatgBackPadFailSts 0 "Normal" 1 "Faulty" 2 "Reserved" 3 "NotAvailable" ;
VAL_ 931 SeatCfmt_PassHeatgCshnPadFailSts 0 "Normal" 1 "Faulty" 2 "Reserved" 3 "NotAvailable" ;
VAL_ 937 AlvCtr_PSMP_SeatPos_Status 15 "Invalid Value" ;
VAL_ 995 AlvCtr_DCMD_ClosureSts 15 "Invalid Value" ;
VAL_ 995 Pwd_DrvrDoorSts 0 "Opening" 1 "Opened" 2 "Closing" 3 "Closed" 4 "Intermediate" 5 "ObstacleDetected" 6 "AntipinchDetected" 7 "BasicPositionStored" 8 "MechanicalEndPositionLearned" 9 "RequestRejected" 10 "VehicleSpeedThresholdCrossed" 11 "Reserved" 12 "Reserved" 13 "Reserved" 14 "Error" 15 "NotAvailable" ;
VAL_ 995 CenLock_DrvrDoorLockUnlckSts 0 "Unlock" 1 "Lock" 2 "Error" 3 "NotAvailable" ;
VAL_ 995 Pwd_DrvrDoorNmlznSts 0 "Denormalised" 1 "Normalised" 2 "Learning" 3 "NotAvailable" ;
VAL_ 995 CenLock_DrvrDoorAjarSts 0 "Open" 1 "Closed" 2 "Error" 3 "NotAvailable" ;
VAL_ 995 Pwind_DrvWndwSts 0 "FullyClose" 1 "PartiallyOpen" 2 "FullyOpen" 3 "Denormalised" 4 "VentilationPosition" 5 "Reserved" 6 "Error" 7 "NotAvailable" ;
VAL_ 999 Engmt_LimphmSts 0 "Disable" 1 "Enable" 2 "Reserved" 3 "Not Available" ;
VAL_ 999 Fschg_ChgAuthenSts 0 "NotAuthenticating" 1 "Authenticating" 2 "AuthenticationSuccess" 3 "AuthenticationFailed" 4 "Reserve" 5 "Reserve" 6 "Reserve" 7 "NotAvailable" ;
VAL_ 999 Acchg_ChgAuthnSts 0 "NotAuthenticating" 1 "Authenticating" 2 "AuthenticationSuccess" 3 "AuthenticationFailed" 4 "Reserve" 5 "Reserve" 6 "Reserve" 7 "NotAvailable" ;
VAL_ 999 Thmgt_ThermFltSts 0 "Not_Detected" 1 "Detected" 2 "Error" 3 "NotAvailable" ;
VAL_ 999 Hfdia_RemdActn 0 "Warning" 1 "AC Charge Inhibition Request" 2 "Fast Charge Inhibition Request" 3 "Emergency Shutdown Request" 4 "Regen Brake Disable Request" 5 "HV Power Reduction Request" 6 "Limp Home Mode" 7 "Drive Inhibition Request" 8 "MCU_F Inhibition" 9 "MCU_R Inhibition" 10 "HV Power Down Request" 11 "Speed Limitation Request" 12 "Battery charge Power Reduction" 13 "DC DC Disable" 14 "MCU_F Power Reduction" 15 "MCU_R Power Reduction" 16 "Neutral Request" 255 "SNA" ;
VAL_ 999 Hvsco_HvSysSts 0 "NotReady" 1 "HVOn" 2 "ReadyToDrive
" 3 "Charging" 4 "Error" 5 "PowerDown" 6 "EmergencySutdown" 7 "NotAvailable" ;
VAL_ 1001 AlvCtr_DCMP_ClosureSts 15 "Invalid Value" ;
VAL_ 1001 CenLock_PassDoorAjarSts 0 "Open" 1 "Closed" 2 "Error" 3 "NotAvailable" ;
VAL_ 1001 CenLock_PassDoorLockUnlckSts 0 "Unlock" 1 "Lock" 2 "Error" 3 "NotAvailable" ;
VAL_ 1001 Pwd_PassDoorSts 0 "Opening" 1 "Opened" 2 "Closing" 3 "Closed" 4 "Intermediate" 5 "ObstacleDetected" 6 "AntipinchDetected" 7 "BasicPositionStored" 8 "MechanicalEndPositionLearned" 9 "RequestRejected" 10 "VehicleSpeedThresholdCrossed" 11 "Reserved" 12 "Reserved" 13 "Reserved" 14 "Error" 15 "NotAvailable" ;
VAL_ 1001 Pwind_PassWndwSts 0 "FullyClose" 1 "PartiallyOpen" 2 "FullyOpen" 3 "Denormalised" 4 "VentilationPosition" 5 "Reserved" 6 "Error" 7 "NotAvailable" ;
VAL_ 1001 Pwd_PassDoorNmlznSts 0 "Denormalised" 1 "Normalised" 2 "Learning" 3 "NotAvailable" ;
VAL_ 1007 AlvCtr_DCMRR_ClosureSts 15 "Invalid Value" ;
VAL_ 1007 CenLock_ReRiDoorLockUnlckSts 0 "Unlock" 1 "Lock" 2 "Error" 3 "NotAvailable" ;
VAL_ 1007 Pwind_ReRiWndwSts 0 "FullyClose" 1 "PartiallyOpen" 2 "FullyOpen" 3 "Denormalised" 4 "VentilationPosition" 5 "Reserved" 6 "Error" 7 "NotAvailable" ;
VAL_ 1011 AlvCtr_DCMRL_ClosureSts 15 "Invalid Value" ;
VAL_ 1011 CenLock_ReLeDoorLockUnlckSts 0 "Unlock" 1 "Lock" 2 "Error" 3 "NotAvailable" ;
VAL_ 1011 CenLock_ReLeDoorAjarSts 0 "Open" 1 "Closed" 2 "Error" 3 "NotAvailable" ;
VAL_ 1011 Pwind_ReLeWndwSts 0 "FullyClose" 1 "PartiallyOpen" 2 "FullyOpen" 3 "Denormalised" 4 "VentilationPosition" 5 "Reserved" 6 "Error" 7 "NotAvailable" ;
VAL_ 1017 Wipr_FrntLeParkPosSts 0 "PositionNotDefine" 1 "OutOfParkPosition" 2 "InParkPosition" 3 "NotAvailable" ;
VAL_ 1017 Wipr_FrntLeSerPosSts 0 "Off" 1 "On" 2 "Error" 3 "NotAvailable" ;
VAL_ 1017 Wipr_FrntLeSts 0 "Off" 1 "On" 2 "Error" 3 "NotAvailable" ;
VAL_ 1017 Wipr_FrntRiParkPosSts 0 "PositionNotDefine" 1 "OutOfParkPosition" 2 "InParkPosition" 3 "NotAvailable" ;
VAL_ 1017 Wipr_FrntRiSerPosSts 0 "Off" 1 "On" 2 "Error" 3 "NotAvailable" ;
VAL_ 1017 Wipr_FrntRiSts 0 "Off" 1 "On" 2 "Error" 3 "NotAvailable" ;
VAL_ 1017 Wipr_WshrSts 0 "Off" 1 "On" 2 "Error" 3 "NotAvailable" ;
VAL_ 1017 Wipr_WshrFluidLevelSts 0 "Off" 1 "Low" 2 "Medium" 3 "High" 4 "Reserved" 5 "Reserved" 6 "Reserved" 7 "Invalid" ;
VAL_ 1017 Wipr_FrntRiFaildSts 0 "NoFault" 1 "LowTempWarn" 2 "LossComWarn" 3 "OverheatWarn" 4 "OverloadWarn" 5 "BlockedPositionErr" 6 "LoadDumpErr" 7 "MaxCurrentErr" 8 "NoCurrentErr" 9 "OverloadErr" 10 "OverVoltageErr" 11 "PositionSensorErr" 12 "ResponseErr" 13 "ShortCircuitErr" 14 "UndervoltageErr" 15 "NotAvailable" ;
VAL_ 1017 Wipr_FrntLeFaildSts 0 "NoFault" 1 "LowTempWarn" 2 "LossComWarn" 3 "OverheatWarn" 4 "OverloadWarn" 5 "BlockedPositionErr" 6 "LoadDumpErr" 7 "MaxCurrentErr" 8 "NoCurrentErr" 9 "OverloadErr" 10 "OverVoltageErr" 11 "PositionSensorErr" 12 "ResponseErr" 13 "ShortCircuitErr" 14 "UndervoltageErr" 15 "NotAvailable" ;
VAL_ 1027 AlvCtr_ZCUF_CenLock_Info 15 "Invalid Value" ;
VAL_ 1027 CenLock_CAppLockUnlckSt 0 "Unlock" 1 "Lock" 2 "Error" 3 "NotAvailable" ;
VAL_ 1027 CenLock_LockUnlckSts 0 "UnlockfromOustSide" 1 "UnlockfromInSide" 2 "LockFromOutSide" 3 "LockFromInSide" 4 "Reserved" 5 "Reserved" 6 "Error" 7 "NotAvailable" ;
VAL_ 1123 AlvCtr_ACM_ActvTrackingStatus 15 "Invalid Value" ;
VAL_ 1123 AirBg_SeatTrackPosPass 0 "Notlatched" 1 "latched" 2 "Error" 3 "NotAvailable" ;
VAL_ 1123 AirBg_SeatTrackPosDrvr 0 "Notlatched" 1 "latched" 2 "Error" 3 "NotAvailable" ;
VAL_ 1123 AirBg_PassAirbgDeacSts 0 "NotDeactivated" 1 "Deactivated" 2 "Error" 3 "NotAvailable" ;
VAL_ 1125 AlvCtr_IVI_DrWndw_Cntr 15 "Invalid Value" ;
VAL_ 1125 CenLock_AudioVisualCfg 0 "Visual" 1 "Audio" 2 "Both_Enable" 3 "NotAvailable" ;
VAL_ 1125 PwrSdSt_LeExtndRtractReq 0 "Not available" 1 "Available" 2 "Error" 3 "SNA" ;
VAL_ 1125 PwrSdSt_RiExtndRtractReq 0 "Not available" 1 "Available" 2 "Error" 3 "SNA" ;
VAL_ 1125 Pwind_WndwUpDwnUsrReq 0 "AutoUp" 1 "AutoDown" 2 "Reserved" 3 "NotAvailable" ;
VAL_ 1129 AlvCtr_MFS_SwitchReq 15 "Invalid Value" ;
VAL_ 1129 Mfsw_AdasScrlSwtReq 0 "NoRequest" 1 "UpPress" 2 "DownPress" 3 "LeftPress" 4 "RightPress" 5 "ShortPress" 6 "LongPress" 7 "SwitchFault" 8 "Reserved" 9 "Reserved" 10 "Reserved" 11 "Reserved" 12 "Reserved" 13 "Reserved" 14 "Error" 15 "NotAvailable" ;
VAL_ 1129 Mfsw_ScrolSwtReq 0 "NoRequest" 1 "UpPress" 2 "DownPress" 3 "LeftPress" 4 "RightPress" 5 "ShortPress" 6 "LongPress" 7 "SwitchFault" 8 "Reserved" 9 "Reserved" 10 "Reserved" 11 "Reserved" 12 "Reserved" 13 "Reserved" 14 "Error" 15 "NotAvailable" ;
VAL_ 1129 Mfsw_RimSwtWiperAcvnCmd 0 "No_Request" 1 "ShortPress" 2 "Longpress" 3 "Reserved" 4 "Reserved" 5 "Reserved" 6 "Switch Fault" 7 "NotAvailable" ;
VAL_ 1129 Mfsw_WiperMenuReq 0 "NoRequest" 1 "ShowWiperMenu" 2 "WiperMenuSelectionUp" 3 "WiperMenuSelectionDown" 4 "WiperModeSelection" 5 "Reserved" 6 "Error" 7 "NotAvailable" ;
VAL_ 1129 Mfsw_PaddSwtFavoSelReq 0 "NoRequest" 1 "BPosPaddleShortPull" 2 "BNegPaddleShortpull" 3 "BPosPaddleShortfault" 4 "BNegPaddleShortfault" 5 "BothPaddleShorPull " 6 "Reserved" 7 "NotAvailable" ;
VAL_ 1129 Mfsw_PaddSwtGearShiftReq 0 "NoRequest" 1 "DrivePaddleShortPull" 2 "ReversePaddleShortPull" 3 "DrivePaddleFault" 4 "ReversePaddleFault" 5 "BothPaddleShortPull" 6 "Reserved" 7 "NotAvailable" ;
VAL_ 1129 Mfsw_AdasSwtReq 0 "Not_Pressed" 1 "Pressed" 2 "Error" 3 "NotAvailable" ;
VAL_ 1129 Mfsw_VoiceSwtReq 0 "NoRequest" 1 "VoiceAssistActivateShortpressed" 2 "VoiceAssistActivateLongPress" 3 "Reserved" 4 "Reserved" 5 "Reserved" 6 "Error" 7 "NotAvailable" ;
VAL_ 1129 Mfsw_RimSwtHiBeamAcvnCmd 0 "No_Request" 1 "ShortPress" 2 "Longpress" 3 "Reserved" 4 "Reserved" 5 "Reserved" 6 "Switch Fault" 7 "NotAvailable" ;
VAL_ 1129 Mfsw_DrvModSwtReq 0 "No_Request" 1 "ShortPress" 2 "Longpress" 3 "Reserved" 4 "Reserved" 5 "Reserved" 6 "Switch Fault" 7 "NotAvailable" ;
VAL_ 1129 Mfsw_ParkSwtReq 0 "No_Request" 1 "ShortPress" 2 "Longpress" 3 "Reserved" 4 "Reserved" 5 "Reserved" 6 "Switch Fault" 7 "NotAvailable" ;
VAL_ 1129 Mfsw_FavoSwtReq 0 "No_Request" 1 "ShortPress" 2 "Longpress" 3 "Reserved" 4 "Reserved" 5 "Reserved" 6 "Switch Fault" 7 "NotAvailable" ;
